VERSION "ICM"

NS_ :

BS_ :

BU_ : ICM Vector_XXX

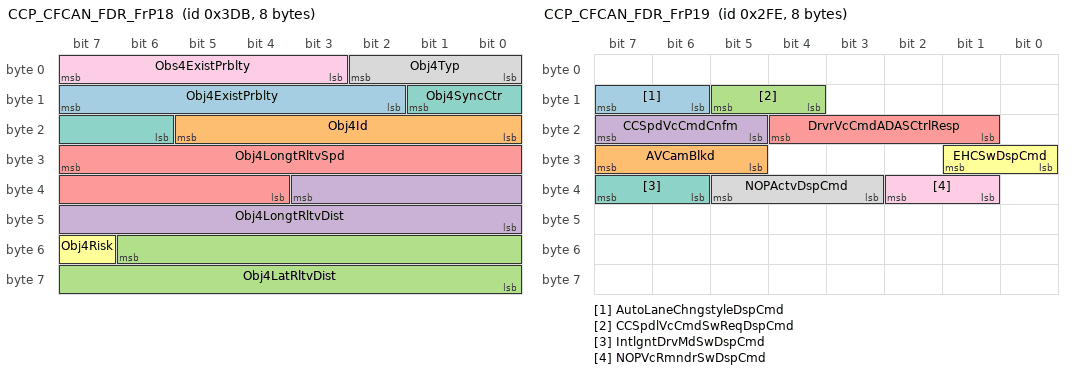
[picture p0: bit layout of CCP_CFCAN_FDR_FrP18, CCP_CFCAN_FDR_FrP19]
BO_ 987 CCP_CFCAN_FDR_FrP18 : 8 Vector_XXX
 SG_ Obj4ExistPrblty : 15|6@0+ (0.015625,0.0) [0.0|0.984375] "" ICM
 SG_ Obj4Id : 21|6@0+ (1.0,0.0) [0.0|63.0] "" ICM
 SG_ Obj4LatRltvDist : 54|15@0+ (0.0078,-128.0) [-128.0|127.58259999999999] "" ICM
 SG_ Obj4LongtRltvDist : 35|12@0+ (0.0625,-128.0) [-128.0|127.9375] "" ICM
 SG_ Obj4LongtRltvSpd : 31|12@0+ (0.0625,-128.0) [-128.0|127.9375] "" ICM
 SG_ Obj4Risk : 55|1@0+ (1,0) [0|1] "" ICM
 SG_ Obj4SyncCtr : 9|4@0+ (1.0,0.0) [0.0|15.0] "" ICM
 SG_ Obj4Typ : 2|3@0+ (1,0) [0|7] "" ICM
 SG_ Obs4ExistPrblty : 7|5@0+ (0.03125,0.0) [0.0|0.96875] "" ICM

BO_ 766 CCP_CFCAN_FDR_FrP19 : 8 Vector_XXX
 SG_ AutoLaneChngstyleDspCmd : 15|2@0+ (1,0) [0|3] "" ICM
 SG_ AVCamBlkd : 31|3@0+ (1,0) [0|7] "" ICM
 SG_ CCSpdlVcCmdSwReqDspCmd : 13|2@0+ (1,0) [0|3] "" ICM
 SG_ CCSpdVcCmdCnfm : 23|3@0+ (1,0) [0|7] "" ICM
 SG_ DrvrVcCmdADASCtrlResp : 20|4@0+ (1,0) [0|15] "" ICM
 SG_ EHCSwDspCmd : 25|2@0+ (1,0) [0|3] "" ICM
 SG_ IntlgntDrvMdSwDspCmd : 39|2@0+ (1,0) [0|3] "" ICM
 SG_ NOPActvDspCmd : 37|3@0+ (1,0) [0|7] "" ICM
 SG_ NOPVcRmndrSwDspCmd : 34|2@0+ (1,0) [0|3] "" ICM

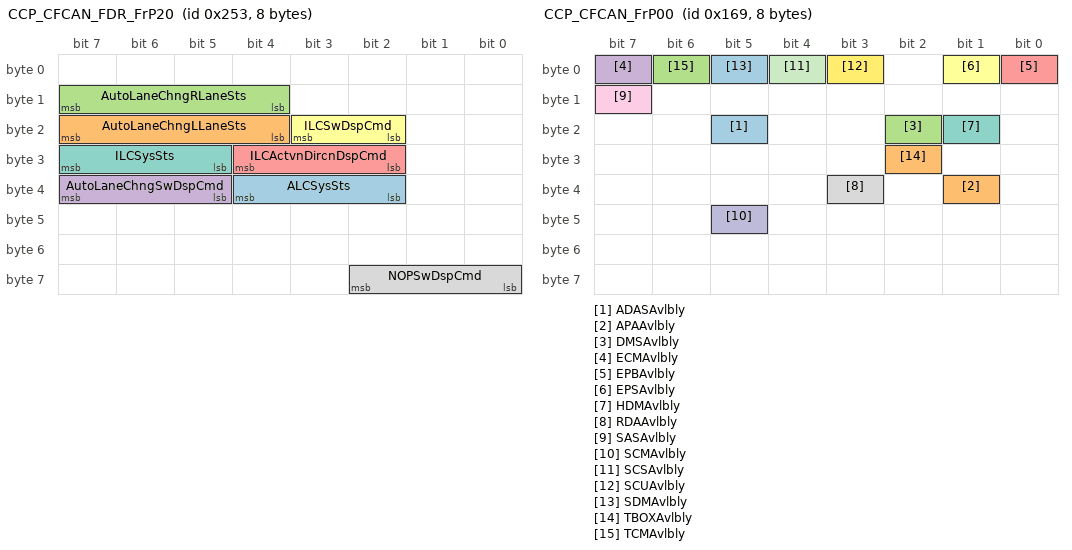
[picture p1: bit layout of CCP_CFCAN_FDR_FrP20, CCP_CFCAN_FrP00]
BO_ 595 CCP_CFCAN_FDR_FrP20 : 8 Vector_XXX
 SG_ ALCSysSts : 36|3@0+ (1,0) [0|7] "" ICM
 SG_ AutoLaneChngLLaneSts : 23|4@0+ (1,0) [0|15] "" ICM
 SG_ AutoLaneChngRLaneSts : 15|4@0+ (1,0) [0|15] "" ICM
 SG_ AutoLaneChngSwDspCmd : 39|3@0+ (1,0) [0|7] "" ICM
 SG_ ILCActvnDircnDspCmd : 28|3@0+ (1,0) [0|7] "" ICM
 SG_ ILCSwDspCmd : 19|2@0+ (1,0) [0|3] "" ICM
 SG_ ILCSysSts : 31|3@0+ (1,0) [0|7] "" ICM
 SG_ NOPSwDspCmd : 58|3@0+ (1,0) [0|7] "" ICM

BO_ 361 CCP_CFCAN_FrP00 : 8 Vector_XXX
 SG_ ADASAvlbly : 21|1@0+ (1,0) [0|1] "" ICM
 SG_ APAAvlbly : 33|1@0+ (1,0) [0|1] "" ICM
 SG_ DMSAvlbly : 18|1@0+ (1,0) [0|1] "" ICM
 SG_ ECMAvlbly : 7|1@0+ (1,0) [0|1] "" ICM
 SG_ EPBAvlbly : 0|1@0+ (1,0) [0|1] "" ICM
 SG_ EPSAvlbly : 1|1@0+ (1,0) [0|1] "" ICM
 SG_ HDMAvlbly : 17|1@0+ (1,0) [0|1] "" ICM
 SG_ RDAAvlbly : 35|1@0+ (1,0) [0|1] "" ICM
 SG_ SASAvlbly : 15|1@0+ (1,0) [0|1] "" ICM
 SG_ SCMAvlbly : 45|1@0+ (1,0) [0|1] "" ICM
 SG_ SCSAvlbly : 4|1@0+ (1,0) [0|1] "" ICM
 SG_ SCUAvlbly : 3|1@0+ (1,0) [0|1] "" ICM
 SG_ SDMAvlbly : 5|1@0+ (1,0) [0|1] "" ICM
 SG_ TBOXAvlbly : 26|1@0+ (1,0) [0|1] "" ICM
 SG_ TCMAvlbly : 6|1@0+ (1,0) [0|1] "" ICM

BO_ 821 CCP_CFCAN_FrP01 : 8 Vector_XXX
 SG_ VehEnrgRdyLvl : 26|3@0+ (1,0) [0|7] "" ICM
 SG_ VehEnrgRdyLvlV : 12|1@0+ (1,0) [0|1] "" ICM

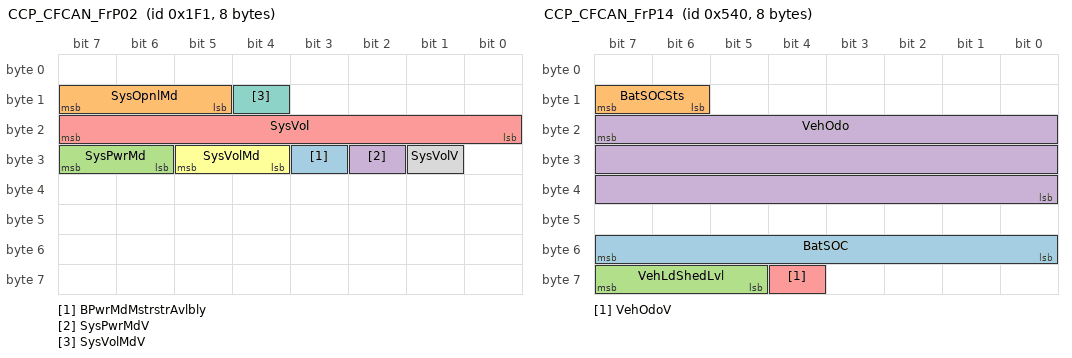
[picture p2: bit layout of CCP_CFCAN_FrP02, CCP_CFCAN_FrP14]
BO_ 497 CCP_CFCAN_FrP02 : 8 Vector_XXX
 SG_ BPwrMdMstrstrAvlbly : 27|1@0+ (1,0) [0|1] "" ICM
 SG_ SysOpnlMd : 15|3@0+ (1,0) [0|7] "" ICM
 SG_ SysPwrMd : 31|2@0+ (1,0) [0|3] "" ICM
 SG_ SysPwrMdV : 26|1@0+ (1,0) [0|1] "" ICM
 SG_ SysVol : 23|8@0+ (0.1,3.0) [3.0|28.5] "V" ICM
 SG_ SysVolMd : 29|2@0+ (1,0) [0|3] "" ICM
 SG_ SysVolMdV : 12|1@0+ (1,0) [0|1] "" ICM
 SG_ SysVolV : 25|1@0+ (1,0) [0|1] "" ICM

BO_ 803 CCP_CFCAN_FrP04 : 8 Vector_XXX
 SG_ BatAgngSta : 55|3@0+ (1,0) [0|7] "" ICM
 SG_ BatVol : 39|14@0+ (0.00097656,3.0) [3.0|17.9999616] "V" ICM

BO_ 794 CCP_CFCAN_FrP05 : 8 Vector_XXX
 SG_ VehCofignBodyCtrlrTyp : 2|3@0+ (1,0) [0|7] "" ICM
 SG_ VehCofignCCTyp : 41|2@0+ (1,0) [0|3] "" ICM
 SG_ VehCofignEnTyp : 12|5@0+ (1.0,0.0) [13.0|31.0] "Reserved" ICM
 SG_ VehCofignParkngBrkTyp : 55|2@0+ (1,0) [0|3] "" ICM
 SG_ VehCofignSlipCtrlTyp : 53|2@0+ (1,0) [0|3] "" ICM
 SG_ VehCofignSpSt : 51|1@0+ (1,0) [0|1] "" ICM
 SG_ VehCofignStrgTyp : 45|2@0+ (1,0) [0|3] "" ICM
 SG_ VehCofignTPMSTyp : 14|2@0+ (1,0) [0|3] "" ICM
 SG_ VehCofignTrnsfCaseTyp : 43|2@0+ (1,0) [0|3] "" ICM
 SG_ VehCofignTrTyp : 19|4@0+ (1.0,0.0) [9.0|15.0] "Reserved" ICM
 SG_ VehInfoBodyTyp : 31|4@0+ (1.0,0.0) [5.0|15.0] "Reserved" ICM
 SG_ VehInfoBrand : 47|2@0+ (1,0) [0|3] "" ICM
 SG_ VehInfoDrvHadlTyp : 15|1@0+ (1,0) [0|1] "" ICM
 SG_ VehInfoEmsnRegn : 23|4@0+ (1,0) [0|15] "" ICM
 SG_ VehInfoMdlYear : 63|5@0+ (1,0) [0|31] "" ICM
 SG_ VehInfoMkt : 7|5@0+ (1.0,0.0) [7.0|31.0] "Reserved" ICM
 SG_ VehInfoPf : 27|4@0+ (1.0,0.0) [8.0|15.0] "Reserved" ICM

BO_ 872 CCP_CFCAN_FrP06 : 6 Vector_XXX
 SG_ VehDrvngMd : 15|3@0+ (1,0) [0|7] "" ICM
 SG_ VehDrvngMdCofign : 21|4@0+ (1,0) [0|15] "" ICM
 SG_ VehDrvngMdRmndr : 23|2@0+ (1,0) [0|3] "" ICM

BO_ 814 CCP_CFCAN_FrP07 : 8 Vector_XXX
 SG_ GenrSta : 15|3@0+ (1,0) [0|7] "" ICM
 SG_ GwStrgCustSetngDspCmd : 26|2@0+ (1,0) [0|3] "" ICM

BO_ 886 CCP_CFCAN_FrP08 : 8 Vector_XXX
 SG_ PMDCSta : 33|2@0+ (1,0) [0|3] "" ICM

BO_ 1008 CCP_CFCAN_FrP12 : 8 Vector_XXX
 SG_ OtsdAirTemCrVal : 63|8@0+ (0.5,-40.0) [-40.0|87.5] "deg C" ICM
 SG_ OtsdAirTemCrValV : 48|1@0+ (1,0) [0|1] "" ICM

BO_ 1344 CCP_CFCAN_FrP14 : 8 Vector_XXX
 SG_ BatSOC : 55|8@0+ (0.4,0.0) [0.0|100.0] "%" ICM
 SG_ BatSOCSts : 15|2@0+ (1,0) [0|3] "" ICM
 SG_ VehLdShedLvl : 63|3@0+ (1,0) [0|7] "" ICM
 SG_ VehOdo : 23|24@0+ (1.0,0.0) [0.0|16777200.0] "" ICM
 SG_ VehOdoV : 60|1@0+ (1,0) [0|1] "" ICM

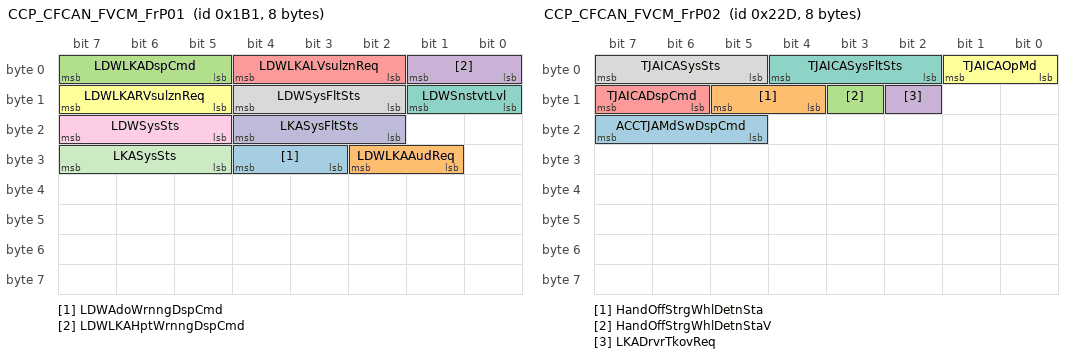
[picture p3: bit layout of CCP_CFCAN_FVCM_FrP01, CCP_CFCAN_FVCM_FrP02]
BO_ 433 CCP_CFCAN_FVCM_FrP01 : 8 Vector_XXX
 SG_ LDWAdoWrnngDspCmd : 28|2@0+ (1,0) [0|3] "" ICM
 SG_ LDWLKAAudReq : 26|2@0+ (1,0) [0|3] "" ICM
 SG_ LDWLKADspCmd : 7|3@0+ (1,0) [0|7] "" ICM
 SG_ LDWLKAHptWrnngDspCmd : 1|2@0+ (1,0) [0|3] "" ICM
 SG_ LDWLKALVsulznReq : 4|3@0+ (1,0) [0|7] "" ICM
 SG_ LDWLKARVsulznReq : 15|3@0+ (1,0) [0|7] "" ICM
 SG_ LDWSnstvtLvl : 9|2@0+ (1,0) [0|3] "" ICM
 SG_ LDWSysFltSts : 12|3@0+ (1,0) [0|7] "" ICM
 SG_ LDWSysSts : 23|3@0+ (1,0) [0|7] "" ICM
 SG_ LKASysFltSts : 20|3@0+ (1,0) [0|7] "" ICM
 SG_ LKASysSts : 31|3@0+ (1,0) [0|7] "" ICM

BO_ 557 CCP_CFCAN_FVCM_FrP02 : 8 Vector_XXX
 SG_ ACCTJAMdSwDspCmd : 23|3@0+ (1,0) [0|7] "" ICM
 SG_ HandOffStrgWhlDetnSta : 13|2@0+ (1,0) [0|3] "" ICM
 SG_ HandOffStrgWhlDetnStaV : 11|1@0+ (1,0) [0|1] "" ICM
 SG_ LKADrvrTkovReq : 10|1@0+ (1,0) [0|1] "" ICM
 SG_ TJAICADspCmd : 15|2@0+ (1,0) [0|3] "" ICM
 SG_ TJAICAOpMd : 1|2@0+ (1,0) [0|3] "" ICM
 SG_ TJAICASysFltSts : 4|3@0+ (1,0) [0|7] "" ICM
 SG_ TJAICASysSts : 7|3@0+ (1,0) [0|7] "" ICM

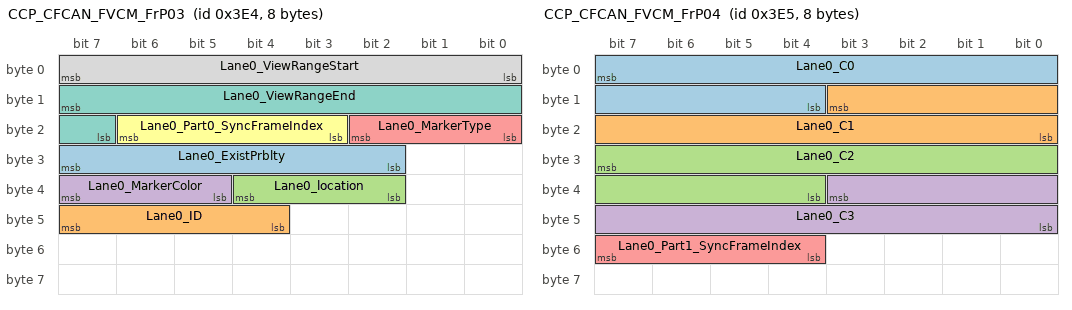
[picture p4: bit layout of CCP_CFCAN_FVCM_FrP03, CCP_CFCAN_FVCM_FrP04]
BO_ 996 CCP_CFCAN_FVCM_FrP03 : 8 Vector_XXX
 SG_ Lane0_ExistPrblty : 31|6@0+ (0.015625,0.0) [0.0|0.984375] "" ICM
 SG_ Lane0_ID : 47|4@0+ (1.0,0.0) [0.0|15.0] "" ICM
 SG_ Lane0_location : 36|3@0+ (1,0) [0|7] "" ICM
 SG_ Lane0_MarkerColor : 39|3@0+ (1,0) [0|7] "" ICM
 SG_ Lane0_MarkerType : 18|3@0+ (1,0) [0|7] "" ICM
 SG_ Lane0_Part0_SyncFrameIndex : 22|4@0+ (1.0,0.0) [0.0|15.0] "" ICM
 SG_ Lane0_ViewRangeEnd : 15|9@0+ (0.25,0.0) [0.0|127.75] "" ICM
 SG_ Lane0_ViewRangeStart : 7|8@0+ (0.25,0.0) [0.0|63.75] "" ICM

BO_ 997 CCP_CFCAN_FVCM_FrP04 : 8 Vector_XXX
 SG_ Lane0_C0 : 7|12@0+ (0.00390625,-8.0) [-8.0|7.99609375] "" ICM
 SG_ Lane0_C1 : 11|12@0+ (0.00048828125,-1.0) [-1.0|0.99951171875] "" ICM
 SG_ Lane0_C2 : 31|12@0+ (0.000015259,-0.03124285) [-0.03124285|-0.023689645] "" ICM
 SG_ Lane0_C3 : 35|12@0+ (0.0000038147,-0.0078125) [-0.0078125|0.0078086965] "" ICM
 SG_ Lane0_Part1_SyncFrameIndex : 55|4@0+ (1.0,0.0) [0.0|15.0] "" ICM

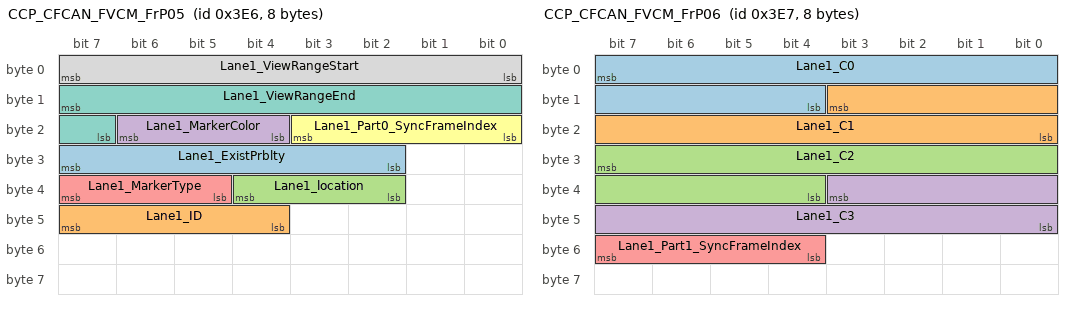
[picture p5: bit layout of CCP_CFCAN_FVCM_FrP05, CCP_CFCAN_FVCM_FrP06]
BO_ 998 CCP_CFCAN_FVCM_FrP05 : 8 Vector_XXX
 SG_ Lane1_ExistPrblty : 31|6@0+ (0.015625,0.0) [0.0|0.984375] "" ICM
 SG_ Lane1_ID : 47|4@0+ (1.0,0.0) [0.0|15.0] "" ICM
 SG_ Lane1_location : 36|3@0+ (1,0) [0|7] "" ICM
 SG_ Lane1_MarkerColor : 22|3@0+ (1,0) [0|7] "" ICM
 SG_ Lane1_MarkerType : 39|3@0+ (1,0) [0|7] "" ICM
 SG_ Lane1_Part0_SyncFrameIndex : 19|4@0+ (1.0,0.0) [0.0|15.0] "" ICM
 SG_ Lane1_ViewRangeEnd : 15|9@0+ (0.25,0.0) [0.0|127.75] "" ICM
 SG_ Lane1_ViewRangeStart : 7|8@0+ (0.25,0.0) [0.0|63.75] "" ICM

BO_ 999 CCP_CFCAN_FVCM_FrP06 : 8 Vector_XXX
 SG_ Lane1_C0 : 7|12@0+ (0.00390625,-8.0) [-8.0|7.99609375] "" ICM
 SG_ Lane1_C1 : 11|12@0+ (0.00048828125,-1.0) [-1.0|0.99951171875] "" ICM
 SG_ Lane1_C2 : 31|12@0+ (0.000015259,-0.03124285) [-0.03124285|0.031242755000000007] "" ICM
 SG_ Lane1_C3 : 35|12@0+ (0.0000038147,-0.0078125) [-0.0078125|0.0078086965] "" ICM
 SG_ Lane1_Part1_SyncFrameIndex : 55|4@0+ (1.0,0.0) [0.0|15.0] "" ICM

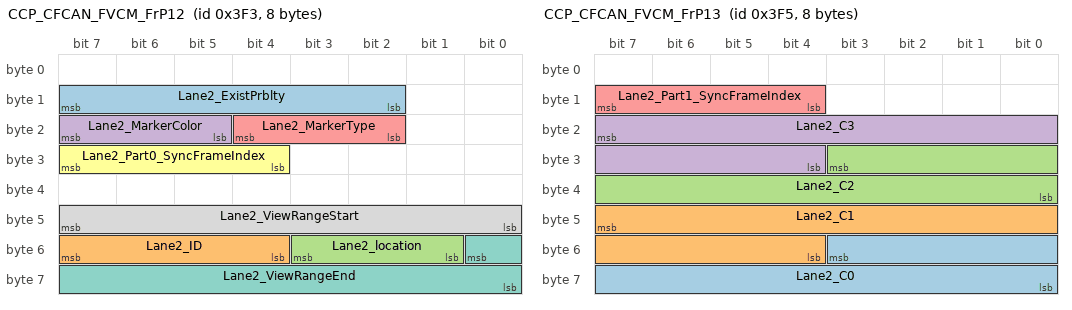
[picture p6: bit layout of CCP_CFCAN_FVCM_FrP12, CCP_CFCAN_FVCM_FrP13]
BO_ 1011 CCP_CFCAN_FVCM_FrP12 : 8 Vector_XXX
 SG_ Lane2_ExistPrblty : 15|6@0+ (0.015625,0.0) [0.0|0.984375] "" ICM
 SG_ Lane2_ID : 55|4@0+ (1.0,0.0) [0.0|15.0] "" ICM
 SG_ Lane2_location : 51|3@0+ (1,0) [0|7] "" ICM
 SG_ Lane2_MarkerColor : 23|3@0+ (1,0) [0|7] "" ICM
 SG_ Lane2_MarkerType : 20|3@0+ (1,0) [0|7] "" ICM
 SG_ Lane2_Part0_SyncFrameIndex : 31|4@0+ (1.0,0.0) [0.0|15.0] "" ICM
 SG_ Lane2_ViewRangeEnd : 48|9@0+ (0.25,0.0) [0.0|127.75] "" ICM
 SG_ Lane2_ViewRangeStart : 47|8@0+ (0.25,0.0) [0.0|63.75] "" ICM

BO_ 1013 CCP_CFCAN_FVCM_FrP13 : 8 Vector_XXX
 SG_ Lane2_C0 : 51|12@0+ (0.00390625,-8.0) [-8.0|7.99609375] "" ICM
 SG_ Lane2_C1 : 47|12@0+ (0.00048828125,-1.0) [-1.0|0.99951171875] "" ICM
 SG_ Lane2_C2 : 27|12@0+ (0.000015259,-0.03124285) [-0.03124285|0.031242755000000007] "" ICM
 SG_ Lane2_C3 : 23|12@0+ (0.0000038147,-0.0078125) [-0.0078125|0.0078086965] "" ICM
 SG_ Lane2_Part1_SyncFrameIndex : 15|4@0+ (1.0,0.0) [0.0|15.0] "" ICM

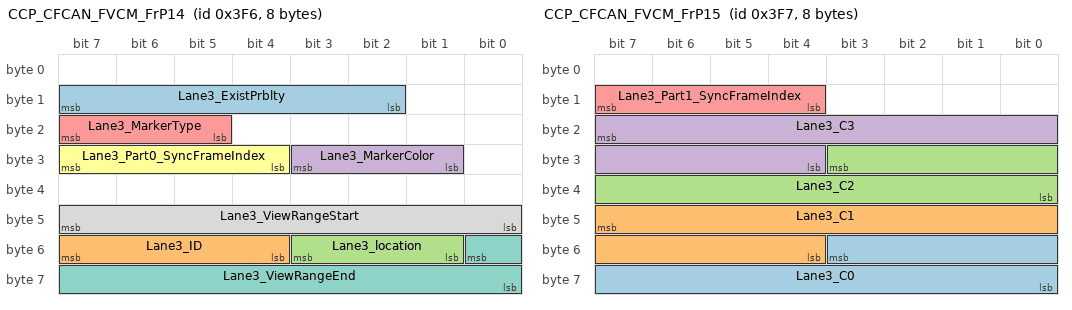
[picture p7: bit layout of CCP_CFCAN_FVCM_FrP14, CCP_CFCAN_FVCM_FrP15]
BO_ 1014 CCP_CFCAN_FVCM_FrP14 : 8 Vector_XXX
 SG_ Lane3_ExistPrblty : 15|6@0+ (0.015625,0.0) [0.0|0.984375] "" ICM
 SG_ Lane3_ID : 55|4@0+ (1.0,0.0) [0.0|15.0] "" ICM
 SG_ Lane3_location : 51|3@0+ (1,0) [0|7] "" ICM
 SG_ Lane3_MarkerColor : 27|3@0+ (1,0) [0|7] "" ICM
 SG_ Lane3_MarkerType : 23|3@0+ (1,0) [0|7] "" ICM
 SG_ Lane3_Part0_SyncFrameIndex : 31|4@0+ (1.0,0.0) [0.0|15.0] "" ICM
 SG_ Lane3_ViewRangeEnd : 48|9@0+ (0.25,0.0) [0.0|127.75] "" ICM
 SG_ Lane3_ViewRangeStart : 47|8@0+ (0.25,0.0) [0.0|63.75] "" ICM

BO_ 1015 CCP_CFCAN_FVCM_FrP15 : 8 Vector_XXX
 SG_ Lane3_C0 : 51|12@0+ (0.00390625,-8.0) [-8.0|7.99609375] "" ICM
 SG_ Lane3_C1 : 47|12@0+ (0.00048828125,-1.0) [-1.0|0.99951171875] "" ICM
 SG_ Lane3_C2 : 27|12@0+ (0.000015259,-0.03124285) [-0.03124285|0.031242755000000007] "" ICM
 SG_ Lane3_C3 : 23|12@0+ (0.0000038147,-0.0078125) [-0.0078125|0.0078086965] "" ICM
 SG_ Lane3_Part1_SyncFrameIndex : 15|4@0+ (1.0,0.0) [0.0|15.0] "" ICM

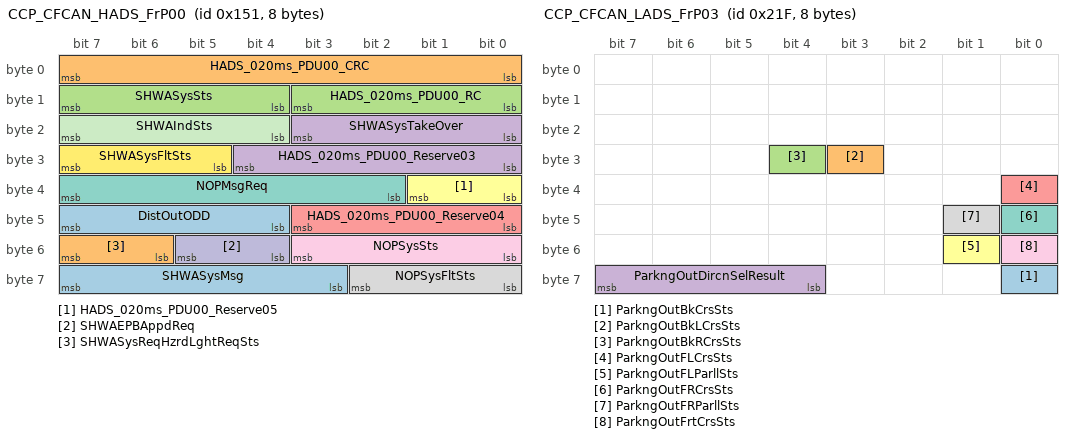
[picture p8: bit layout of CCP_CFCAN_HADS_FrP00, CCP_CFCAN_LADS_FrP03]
BO_ 337 CCP_CFCAN_HADS_FrP00 : 8 Vector_XXX
 SG_ DistOutODD : 47|4@0+ (1,0) [0|15] "" ICM
 SG_ HADS_020ms_PDU00_CRC : 7|8@0+ (1.0,0.0) [0.0|255.0] "" ICM
 SG_ HADS_020ms_PDU00_RC : 11|4@0+ (1.0,0.0) [0.0|15.0] "" ICM
 SG_ HADS_020ms_PDU00_Reserve03 : 28|5@0+ (1,0) [0|31] "" ICM
 SG_ HADS_020ms_PDU00_Reserve04 : 43|4@0+ (1,0) [0|15] "" ICM
 SG_ HADS_020ms_PDU00_Reserve05 : 33|2@0+ (1,0) [0|3] "" ICM
 SG_ NOPMsgReq : 39|6@0+ (1,0) [0|63] "" ICM
 SG_ NOPSysFltSts : 58|3@0+ (1,0) [0|7] "" ICM
 SG_ NOPSysSts : 51|4@0+ (1,0) [0|15] "" ICM
 SG_ SHWAEPBAppdReq : 53|2@0+ (1,0) [0|3] "" ICM
 SG_ SHWAIndSts : 23|4@0+ (1,0) [0|15] "" ICM
 SG_ SHWASysFltSts : 31|3@0+ (1,0) [0|7] "" ICM
 SG_ SHWASysMsg : 63|5@0+ (1,0) [0|31] "" ICM
 SG_ SHWASysReqHzrdLghtReqSts : 55|2@0+ (1,0) [0|3] "" ICM
 SG_ SHWASysSts : 15|4@0+ (1,0) [0|15] "" ICM
 SG_ SHWASysTakeOver : 19|4@0+ (1,0) [0|15] "" ICM

BO_ 581 CCP_CFCAN_HDM_FrP00 : 8 Vector_XXX
 SG_ HDMLicVPrd : 31|16@0+ (1.0,0.0) [0.0|65534.0] "days" ICM
 SG_ HDMSysFltSts : 15|2@0+ (1,0) [0|3] "" ICM
 SG_ HDMSysIMUCalSts : 20|3@0+ (1,0) [0|7] "" ICM
 SG_ HDMSysLicActvnSts : 47|3@0+ (1,0) [0|7] "" ICM

BO_ 591 CCP_CFCAN_LADS_FrP02 : 8 Vector_XXX
 SG_ APASts : 27|3@0+ (1,0) [0|7] "" ICM

BO_ 543 CCP_CFCAN_LADS_FrP03 : 8 Vector_XXX
 SG_ ParkngOutBkCrsSts : 56|1@0+ (1,0) [0|1] "" ICM
 SG_ ParkngOutBkLCrsSts : 27|1@0+ (1,0) [0|1] "" ICM
 SG_ ParkngOutBkRCrsSts : 28|1@0+ (1,0) [0|1] "" ICM
 SG_ ParkngOutDircnSelResult : 63|4@0+ (1,0) [0|15] "" ICM
 SG_ ParkngOutFLCrsSts : 32|1@0+ (1,0) [0|1] "" ICM
 SG_ ParkngOutFLParllSts : 49|1@0+ (1,0) [0|1] "" ICM
 SG_ ParkngOutFRCrsSts : 40|1@0+ (1,0) [0|1] "" ICM
 SG_ ParkngOutFRParllSts : 41|1@0+ (1,0) [0|1] "" ICM
 SG_ ParkngOutFrtCrsSts : 48|1@0+ (1,0) [0|1] "" ICM

BO_ 765 CCP_CFCAN_LADS_FrP10 : 8 Vector_XXX
 SG_ AVMCalMdReqResp_LADS : 39|3@0+ (1,0) [0|7] "" ICM
 SG_ AVMSysSts_LADS : 13|2@0+ (1,0) [0|3] "" ICM

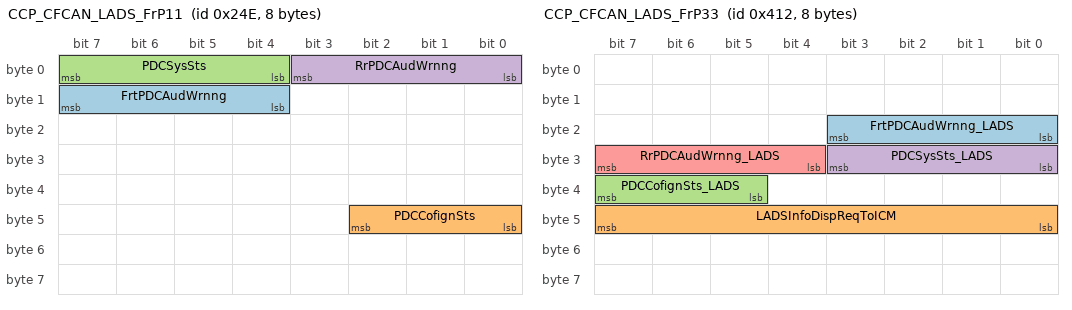
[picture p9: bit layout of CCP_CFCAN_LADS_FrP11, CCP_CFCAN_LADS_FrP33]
BO_ 590 CCP_CFCAN_LADS_FrP11 : 8 Vector_XXX
 SG_ FrtPDCAudWrnng : 15|4@0+ (1,0) [0|15] "" ICM
 SG_ PDCCofignSts : 42|3@0+ (1,0) [0|7] "" ICM
 SG_ PDCSysSts : 7|4@0+ (1,0) [0|15] "" ICM
 SG_ RrPDCAudWrnng : 3|4@0+ (1,0) [0|15] "" ICM

BO_ 1038 CCP_CFCAN_LADS_FrP30 : 8 Vector_XXX
 SG_ MUWSwSts : 26|2@0+ (1,0) [0|3] "" ICM

BO_ 605 CCP_CFCAN_LADS_FrP32 : 8 Vector_XXX
 SG_ HD_AVMCurView : 39|6@0+ (1,0) [0|63] "" ICM
 SG_ HD_AVMsysrdy : 33|1@0+ (1,0) [0|1] "" ICM

BO_ 1042 CCP_CFCAN_LADS_FrP33 : 8 Vector_XXX
 SG_ FrtPDCAudWrnng_LADS : 19|4@0+ (1,0) [0|15] "" ICM
 SG_ LADSInfoDispReqToICM : 47|8@0+ (1,0) [0|255] "" ICM
 SG_ PDCCofignSts_LADS : 39|3@0+ (1,0) [0|7] "" ICM
 SG_ PDCSysSts_LADS : 27|4@0+ (1,0) [0|15] "" ICM
 SG_ RrPDCAudWrnng_LADS : 31|4@0+ (1,0) [0|15] "" ICM

BO_ 1216 CCP_CFCAN_NM : 8 Vector_XXX
 SG_ NmPDU_CFCAN_CCP : 7|64@0+ (1,0) [0|0] "" ICM

BO_ 778 CCP_CFCAN_SCM_FrP01 : 8 Vector_XXX
 SG_ SCMCustSetngDspCmd : 15|2@0+ (1,0) [0|3] "" ICM
 SG_ SusFlrSts : 23|2@0+ (1,0) [0|3] "" ICM
 SG_ SusMdSts : 13|2@0+ (1,0) [0|3] "" ICM

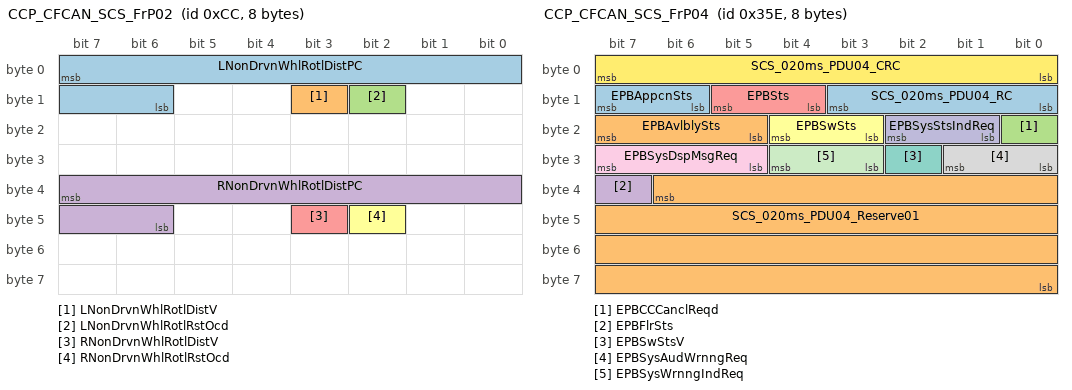
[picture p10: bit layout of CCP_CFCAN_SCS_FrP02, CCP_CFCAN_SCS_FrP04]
BO_ 204 CCP_CFCAN_SCS_FrP02 : 8 Vector_XXX
 SG_ LNonDrvnWhlRotlDistPC : 7|10@0+ (1.0,0.0) [0.0|1023.0] "" ICM
 SG_ LNonDrvnWhlRotlDistV : 11|1@0+ (1,0) [0|1] "" ICM
 SG_ LNonDrvnWhlRotlRstOcd : 10|1@0+ (1,0) [0|1] "" ICM
 SG_ RNonDrvnWhlRotlDistPC : 39|10@0+ (1.0,0.0) [0.0|1023.0] "" ICM
 SG_ RNonDrvnWhlRotlDistV : 43|1@0+ (1,0) [0|1] "" ICM
 SG_ RNonDrvnWhlRotlRstOcd : 42|1@0+ (1,0) [0|1] "" ICM

BO_ 862 CCP_CFCAN_SCS_FrP04 : 8 Vector_XXX
 SG_ EPBAppcnSts : 15|2@0+ (1,0) [0|3] "" ICM
 SG_ EPBAvlblySts : 23|3@0+ (1,0) [0|7] "" ICM
 SG_ EPBCCCanclReqd : 16|1@0+ (1,0) [0|1] "" ICM
 SG_ EPBFlrSts : 39|1@0+ (1,0) [0|1] "" ICM
 SG_ EPBSts : 13|2@0+ (1,0) [0|3] "" ICM
 SG_ EPBSwSts : 20|2@0+ (1,0) [0|3] "" ICM
 SG_ EPBSwStsV : 26|1@0+ (1,0) [0|1] "" ICM
 SG_ EPBSysAudWrnngReq : 25|2@0+ (1,0) [0|3] "" ICM
 SG_ EPBSysDspMsgReq : 31|3@0+ (1,0) [0|7] "" ICM
 SG_ EPBSysStsIndReq : 18|2@0+ (1,0) [0|3] "" ICM
 SG_ EPBSysWrnngIndReq : 28|2@0+ (1,0) [0|3] "" ICM
 SG_ SCS_020ms_PDU04_CRC : 7|8@0+ (1.0,0.0) [0.0|255.0] "" ICM
 SG_ SCS_020ms_PDU04_RC : 11|4@0+ (1.0,0.0) [0.0|15.0] "" ICM
 SG_ SCS_020ms_PDU04_Reserve01 : 38|31@0+ (1,0) [0|2147483647] "" ICM

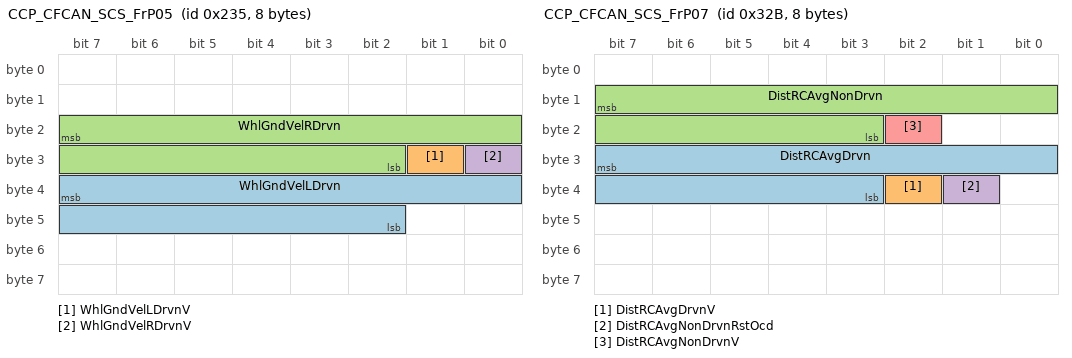
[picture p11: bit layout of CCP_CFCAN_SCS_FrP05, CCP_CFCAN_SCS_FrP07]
BO_ 565 CCP_CFCAN_SCS_FrP05 : 8 Vector_XXX
 SG_ WhlGndVelLDrvn : 39|14@0+ (0.03125,0.0) [0.0|511.96875] "km/h" ICM
 SG_ WhlGndVelLDrvnV : 25|1@0+ (1,0) [0|1] "" ICM
 SG_ WhlGndVelRDrvn : 23|14@0+ (0.03125,0.0) [0.0|511.96875] "km/h" ICM
 SG_ WhlGndVelRDrvnV : 24|1@0+ (1,0) [0|1] "" ICM

BO_ 811 CCP_CFCAN_SCS_FrP07 : 8 Vector_XXX
 SG_ DistRCAvgDrvn : 31|13@0+ (0.125,0.0) [0.0|1023.875] "m" ICM
 SG_ DistRCAvgDrvnV : 34|1@0+ (1,0) [0|1] "" ICM
 SG_ DistRCAvgNonDrvn : 15|13@0+ (0.125,0.0) [0.0|1023.875] "m" ICM
 SG_ DistRCAvgNonDrvnRstOcd : 33|1@0+ (1,0) [0|1] "" ICM
 SG_ DistRCAvgNonDrvnV : 18|1@0+ (1,0) [0|1] "" ICM

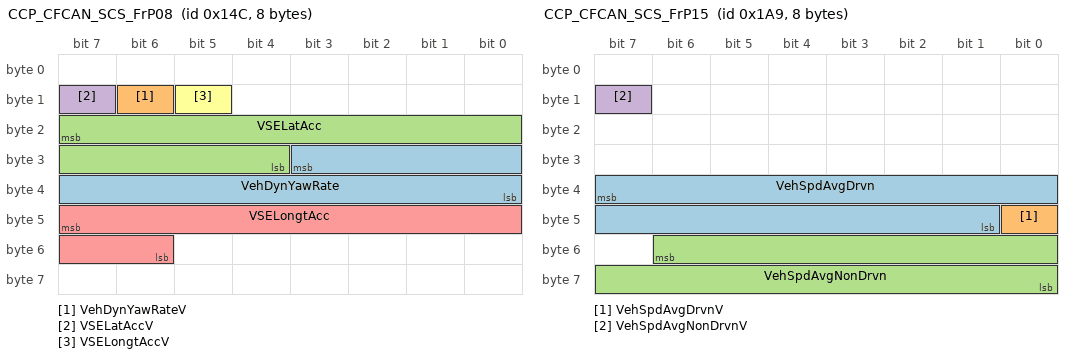
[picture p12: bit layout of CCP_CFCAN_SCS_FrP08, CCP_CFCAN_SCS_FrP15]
BO_ 332 CCP_CFCAN_SCS_FrP08 : 8 Vector_XXX
 SG_ VehDynYawRate : 27|12@0- (0.0625,0.0) [-128.0|127.9375] "deg/sec" ICM
 SG_ VehDynYawRateV : 14|1@0+ (1,0) [0|1] "" ICM
 SG_ VSELatAcc : 23|12@0- (0.015625,0.0) [-32.0|31.984375] "m/s^2" ICM
 SG_ VSELatAccV : 15|1@0+ (1,0) [0|1] "" ICM
 SG_ VSELongtAcc : 47|10@0- (0.03,0.0) [-15.36|15.33] "m/s^2" ICM
 SG_ VSELongtAccV : 13|1@0+ (1,0) [0|1] "" ICM

BO_ 425 CCP_CFCAN_SCS_FrP15 : 8 Vector_XXX
 SG_ VehSpdAvgDrvn : 39|15@0+ (0.015625,0.0) [0.0|511.984375] "km/h" ICM
 SG_ VehSpdAvgDrvnV : 40|1@0+ (1,0) [0|1] "" ICM
 SG_ VehSpdAvgNonDrvn : 54|15@0+ (0.015625,0.0) [0.0|511.984375] "km/h" ICM
 SG_ VehSpdAvgNonDrvnV : 15|1@0+ (1,0) [0|1] "" ICM

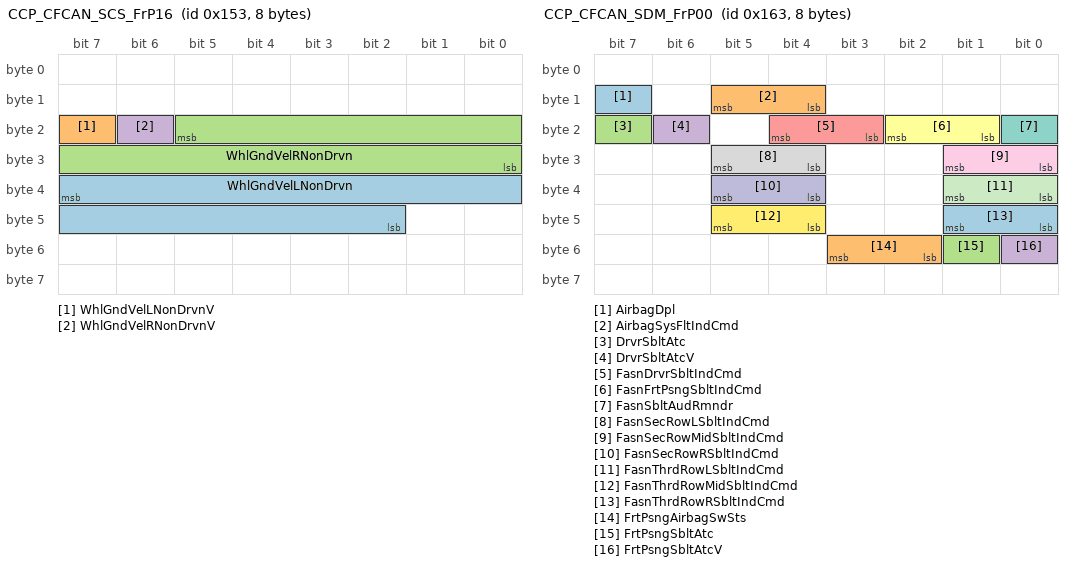
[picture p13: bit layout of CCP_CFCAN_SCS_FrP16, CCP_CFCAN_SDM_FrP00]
BO_ 339 CCP_CFCAN_SCS_FrP16 : 8 Vector_XXX
 SG_ WhlGndVelLNonDrvn : 39|14@0+ (0.03125,0.0) [0.0|511.96875] "km/h" ICM
 SG_ WhlGndVelLNonDrvnV : 23|1@0+ (1,0) [0|1] "" ICM
 SG_ WhlGndVelRNonDrvn : 21|14@0+ (0.03125,0.0) [0.0|511.96875] "km/h" ICM
 SG_ WhlGndVelRNonDrvnV : 22|1@0+ (1,0) [0|1] "" ICM

BO_ 355 CCP_CFCAN_SDM_FrP00 : 8 Vector_XXX
 SG_ AirbagDpl : 15|1@0+ (1,0) [0|1] "" ICM
 SG_ AirbagSysFltIndCmd : 13|2@0+ (1,0) [0|3] "" ICM
 SG_ DrvrSbltAtc : 23|1@0+ (1,0) [0|1] "" ICM
 SG_ DrvrSbltAtcV : 22|1@0+ (1,0) [0|1] "" ICM
 SG_ FasnDrvrSbltIndCmd : 20|2@0+ (1,0) [0|3] "" ICM
 SG_ FasnFrtPsngSbltIndCmd : 18|2@0+ (1,0) [0|3] "" ICM
 SG_ FasnSbltAudRmndr : 16|1@0+ (1,0) [0|1] "" ICM
 SG_ FasnSecRowLSbltIndCmd : 29|2@0+ (1,0) [0|3] "" ICM
 SG_ FasnSecRowMidSbltIndCmd : 25|2@0+ (1,0) [0|3] "" ICM
 SG_ FasnSecRowRSbltIndCmd : 37|2@0+ (1,0) [0|3] "" ICM
 SG_ FasnThrdRowLSbltIndCmd : 33|2@0+ (1,0) [0|3] "" ICM
 SG_ FasnThrdRowMidSbltIndCmd : 45|2@0+ (1,0) [0|3] "" ICM
 SG_ FasnThrdRowRSbltIndCmd : 41|2@0+ (1,0) [0|3] "" ICM
 SG_ FrtPsngAirbagSwSts : 51|2@0+ (1,0) [0|3] "" ICM
 SG_ FrtPsngSbltAtc : 49|1@0+ (1,0) [0|1] "" ICM
 SG_ FrtPsngSbltAtcV : 48|1@0+ (1,0) [0|1] "" ICM

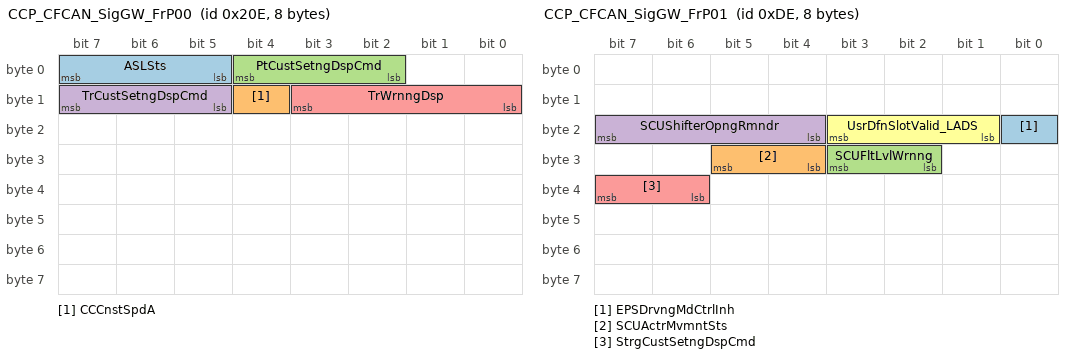
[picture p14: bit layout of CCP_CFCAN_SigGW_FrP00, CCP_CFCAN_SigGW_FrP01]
BO_ 526 CCP_CFCAN_SigGW_FrP00 : 8 Vector_XXX
 SG_ ASLSts : 7|3@0+ (1,0) [0|7] "" ICM
 SG_ CCCnstSpdA : 12|1@0+ (1,0) [0|1] "" ICM
 SG_ PtCustSetngDspCmd : 4|3@0+ (1,0) [0|7] "" ICM
 SG_ TrCustSetngDspCmd : 15|3@0+ (1.0,0.0) [0.0|7.0] "" ICM
 SG_ TrWrnngDsp : 11|4@0+ (1,0) [0|15] "" ICM

BO_ 222 CCP_CFCAN_SigGW_FrP01 : 8 Vector_XXX
 SG_ EPSDrvngMdCtrlInh : 16|1@0+ (1,0) [0|1] "" ICM
 SG_ SCUActrMvmntSts : 29|2@0+ (1,0) [0|3] "" ICM
 SG_ SCUFltLvlWrnng : 27|2@0+ (1,0) [0|3] "" ICM
 SG_ SCUShifterOpngRmndr : 23|4@0+ (1,0) [0|15] "" ICM
 SG_ StrgCustSetngDspCmd : 39|2@0+ (1,0) [0|3] "" ICM
 SG_ UsrDfnSlotValid_LADS : 19|3@0+ (1,0) [0|7] "" ICM

BO_ 362 CCP_CFCAN_SigGW_FrP02 : 8 Vector_XXX
 SG_ ABSIO : 47|1@0+ (1,0) [0|1] "" ICM
 SG_ ACCSysFltSts : 2|3@0+ (1,0) [0|7] "" ICM
 SG_ ACCSysSts : 15|3@0+ (1,0) [0|7] "" ICM
 SG_ AEBSysFltSts : 12|3@0+ (1,0) [0|7] "" ICM
 SG_ AEBSysSts : 23|3@0+ (1,0) [0|7] "" ICM
 SG_ AutoHoldMsg : 7|3@0+ (1,0) [0|7] "" ICM
 SG_ AutoHoldSysSts : 60|2@0+ (1,0) [0|3] "" ICM
 SG_ AutoMainBeamLghtReq : 9|2@0+ (1,0) [0|3] "" ICM
 SG_ BrkSysRedBrkTlltReq : 4|1@0+ (1,0) [0|1] "" ICM
 SG_ EnASSSta : 25|2@0+ (1,0) [0|3] "" ICM
 SG_ FCTASysFltSts : 28|3@0+ (1,0) [0|7] "" ICM
 SG_ FVCMBlkd : 29|1@0+ (1,0) [0|1] "" ICM
 SG_ FVCMCalPrgsReq : 20|3@0+ (1,0) [0|7] "" ICM
 SG_ FVCMFltSts : 17|2@0+ (1,0) [0|3] "" ICM
 SG_ HDCSysSts : 63|3@0+ (1,0) [0|7] "" ICM
 SG_ SCSMdSts : 31|2@0+ (1,0) [0|3] "" ICM
 SG_ TCSOpngMd : 45|3@0+ (1,0) [0|7] "" ICM
 SG_ TCSOpngSts : 42|3@0+ (1,0) [0|7] "" ICM
 SG_ VSEMd : 53|3@0+ (1,0) [0|7] "" ICM
 SG_ VSESts : 50|3@0+ (1,0) [0|7] "" ICM

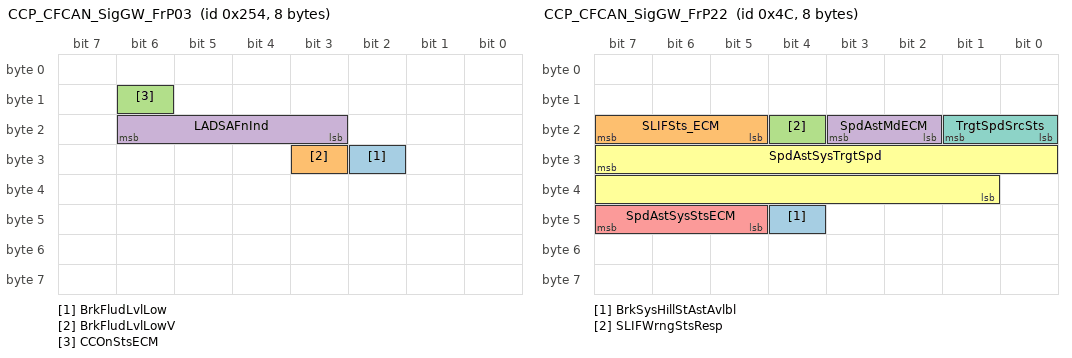
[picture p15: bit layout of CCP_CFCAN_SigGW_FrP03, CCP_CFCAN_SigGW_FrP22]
BO_ 596 CCP_CFCAN_SigGW_FrP03 : 8 Vector_XXX
 SG_ BrkFludLvlLow : 26|1@0+ (1,0) [0|1] "" ICM
 SG_ BrkFludLvlLowV : 27|1@0+ (1,0) [0|1] "" ICM
 SG_ CCOnStsECM : 14|1@0+ (1,0) [0|1] "" ICM
 SG_ LADSAFnInd : 22|4@0+ (1,0) [0|15] "" ICM

BO_ 1353 CCP_CFCAN_SigGW_FrP06 : 8 Vector_XXX
 SG_ EnOilPrsLowIO : 3|1@0+ (1,0) [0|1] "" ICM

BO_ 934 CCP_CFCAN_SigGW_FrP21 : 8 Vector_XXX
 SG_ StrgCDMSSetngDspCmd : 7|7@0+ (1,0) [0|127] "" ICM

BO_ 76 CCP_CFCAN_SigGW_FrP22 : 8 Vector_XXX
 SG_ BrkSysHillStAstAvlbl : 44|1@0+ (1,0) [0|1] "" ICM
 SG_ SLIFSts_ECM : 23|3@0+ (1,0) [0|7] "" ICM
 SG_ SLIFWrngStsResp : 20|1@0+ (1,0) [0|1] "" ICM
 SG_ SpdAstMdECM : 19|2@0+ (1,0) [0|3] "" ICM
 SG_ SpdAstSysStsECM : 47|3@0+ (1,0) [0|7] "" ICM
 SG_ SpdAstSysTrgtSpd : 31|15@0+ (0.015625,0.0) [0.0|511.984375] "" ICM
 SG_ TrgtSpdSrcSts : 17|2@0+ (1,0) [0|3] "" ICM

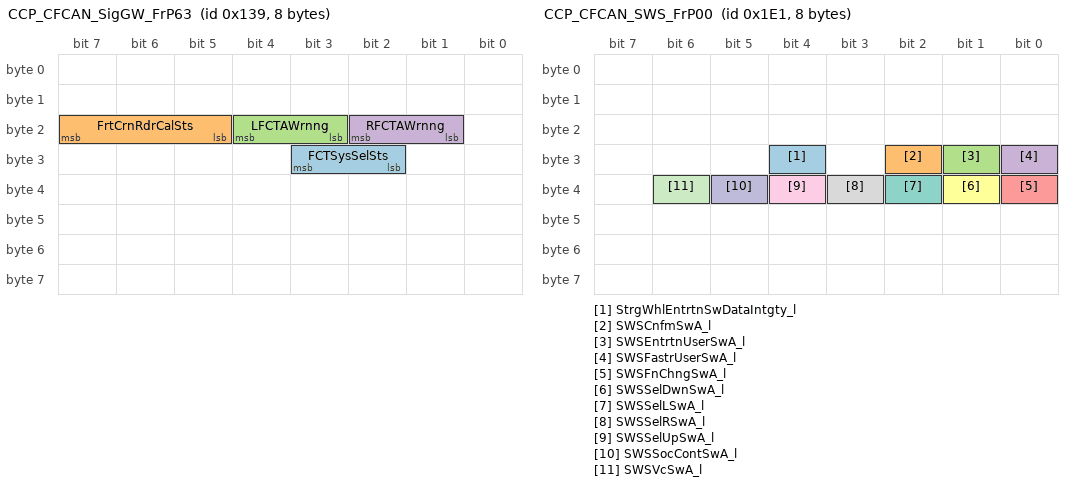
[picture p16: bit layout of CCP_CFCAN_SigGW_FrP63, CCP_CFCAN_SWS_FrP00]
BO_ 313 CCP_CFCAN_SigGW_FrP63 : 8 Vector_XXX
 SG_ FCTSysSelSts : 27|2@0+ (1,0) [0|3] "" ICM
 SG_ FrtCrnRdrCalSts : 23|3@0+ (1,0) [0|7] "" ICM
 SG_ LFCTAWrnng : 20|2@0+ (1,0) [0|3] "" ICM
 SG_ RFCTAWrnng : 18|2@0+ (1,0) [0|3] "" ICM

BO_ 553 CCP_CFCAN_SigGW_FrP67 : 8 Vector_XXX
 SG_ BSDSelSts : 29|2@0+ (1,0) [0|3] "" ICM
 SG_ DOWSelSts : 39|2@0+ (1,0) [0|3] "" ICM
 SG_ LBSDAndLCAWrnng : 37|2@0+ (1,0) [0|3] "" ICM
 SG_ LCASelSts : 27|2@0+ (1,0) [0|3] "" ICM
 SG_ LDOWWrnng : 35|2@0+ (1,0) [0|3] "" ICM
 SG_ LRCTAWrnng : 33|2@0+ (1,0) [0|3] "" ICM
 SG_ RBSDAndLCAWrnng : 47|2@0+ (1,0) [0|3] "" ICM
 SG_ RCTBPrflReq : 63|1@0+ (1,0) [0|1] "" ICM
 SG_ RCTBReq : 31|2@0+ (1,0) [0|3] "" ICM
 SG_ RCTBSysFltSts : 10|3@0+ (1,0) [0|7] "" ICM
 SG_ RCTBSysSta : 15|5@0+ (1,0) [0|31] "" ICM
 SG_ RCTBTrgtDcl : 7|8@0+ (0.1,-12.7) [-12.7|12.8] "m/s^2" ICM
 SG_ RCTSysSelSts : 45|2@0+ (1,0) [0|3] "" ICM
 SG_ RCWSelSts : 43|2@0+ (1,0) [0|3] "" ICM
 SG_ RCWWrnng : 41|2@0+ (1,0) [0|3] "" ICM
 SG_ RDASwSts : 25|2@0+ (1,0) [0|3] "" ICM
 SG_ RDASysSta : 23|5@0+ (1,0) [0|31] "" ICM
 SG_ RDOWWrnng : 55|2@0+ (1,0) [0|3] "" ICM
 SG_ RrCrnRdrCalSts : 18|3@0+ (1,0) [0|7] "" ICM
 SG_ RRCTAWrnng : 49|2@0+ (1,0) [0|3] "" ICM

BO_ 560 CCP_CFCAN_SigGW_FrP90 : 8 Vector_XXX
 SG_ ELSDCustSetngDspCmd : 31|2@0+ (1,0) [0|3] "" ICM
 SG_ EnToqActuExtdRng : 51|12@0+ (0.5,-848.0) [-848.0|1199.5] "Nm" ICM

BO_ 481 CCP_CFCAN_SWS_FrP00 : 8 Vector_XXX
 SG_ StrgWhlEntrtnSwDataIntgty_l : 28|1@0+ (1,0) [0|1] "" ICM
 SG_ SWSCnfmSwA_l : 26|1@0+ (1,0) [0|1] "" ICM
 SG_ SWSEntrtnUserSwA_l : 25|1@0+ (1,0) [0|1] "" ICM
 SG_ SWSFastrUserSwA_l : 24|1@0+ (1,0) [0|1] "" ICM
 SG_ SWSFnChngSwA_l : 32|1@0+ (1,0) [0|1] "" ICM
 SG_ SWSSelDwnSwA_l : 33|1@0+ (1,0) [0|1] "" ICM
 SG_ SWSSelLSwA_l : 34|1@0+ (1,0) [0|1] "" ICM
 SG_ SWSSelRSwA_l : 35|1@0+ (1,0) [0|1] "" ICM
 SG_ SWSSelUpSwA_l : 36|1@0+ (1,0) [0|1] "" ICM
 SG_ SWSSocContSwA_l : 37|1@0+ (1,0) [0|1] "" ICM
 SG_ SWSVcSwA_l : 38|1@0+ (1,0) [0|1] "" ICM

BO_ 819 CCP_CFCAN_TBOX_FrP01 : 8 Vector_XXX
 SG_ FOTASts : 15|1@0+ (1,0) [0|1] "" ICM
 SG_ FOTAStsV : 23|1@0+ (1,0) [0|1] "" ICM

BO_ 852 CCP_CFCAN_TBOX_FrP02 : 8 Vector_XXX
 SG_ EmgcCallFlrSts : 6|2@0+ (1,0) [0|3] "" ICM
 SG_ EmgcCallTrigd : 4|1@0+ (1,0) [0|1] "" ICM

BO_ 501 CCP_CFCAN_TCM_FrP02 : 8 Vector_XXX
 SG_ AutocTrCmddGear_TCM : 15|4@0+ (1,0) [0|15] "" ICM
 SG_ DrvrShftCtrlReqDndIO : 21|1@0+ (1,0) [0|1] "" ICM
 SG_ DrvrShftCtrlTrgtGear_TCM : 19|4@0+ (1,0) [0|15] "" ICM
 SG_ TCM_025ms_PDU02_CRC : 7|8@0+ (1.0,0.0) [0.0|255.0] "" ICM
 SG_ TCM_025ms_PDU02_RC : 11|4@0+ (1.0,0.0) [0.0|15.0] "" ICM
 SG_ TCM_025ms_PDU02_Reserve03 : 47|1@0+ (1,0) [0|1] "" ICM
 SG_ TCM_025ms_PDU02_Reserve04 : 23|2@0+ (1,0) [0|3] "" ICM
 SG_ TCM_025ms_PDU02_Reserve05 : 63|8@0+ (1,0) [0|255] "" ICM
 SG_ TrCrpMdA_TCM : 46|1@0+ (1,0) [0|1] "" ICM
 SG_ TrEngdSta_TCM : 49|2@0+ (1,0) [0|3] "" ICM
 SG_ TrEngdStaV_TCM : 50|1@0+ (1,0) [0|1] "" ICM
 SG_ TrEPBAppReq : 20|1@0+ (1,0) [0|1] "" ICM
 SG_ TrEstdGear_TCM : 39|4@0+ (1,0) [0|15] "" ICM
 SG_ TrEstdGearV_TCM : 45|1@0+ (1,0) [0|1] "" ICM
 SG_ TrIntnlSwPos : 54|4@0+ (1,0) [0|15] "" ICM
 SG_ TrIntnlSwPosV : 55|1@0+ (1,0) [0|1] "" ICM
 SG_ TrPrkPos : 31|2@0+ (1,0) [0|3] "" ICM
 SG_ TrPrkSysF : 29|1@0+ (1,0) [0|1] "" ICM
 SG_ TrShftLvrPos_TCM : 27|4@0+ (1,0) [0|15] "" ICM
 SG_ TrShftLvrPosV_TCM : 28|1@0+ (1,0) [0|1] "" ICM
 SG_ TrShftPtrnASts_TCM : 44|3@0+ (1,0) [0|7] "" ICM
 SG_ TrTapUpTapDwnMdSts_TCM : 41|2@0+ (1,0) [0|3] "" ICM
 SG_ TrTrgtShftLvrPos : 35|4@0+ (1,0) [0|15] "" ICM

BO_ 1358 CCP_CFCAN_TCM_FrP09 : 8 Vector_XXX
 SG_ TrClThrmlProtnNotfn : 35|4@0+ (1,0) [0|15] "" ICM
 SG_ TrEstdClCldnTemTrgtDsp : 55|8@0+ (0.392157,0.0) [0.0|100.000035] "%" ICM
 SG_ TrEstdClTemDsp : 47|8@0+ (0.392157,0.0) [0.0|100.000035] "%" ICM
 SG_ TrNonEmsnRltdMalfA : 4|1@0+ (1,0) [0|1] "" ICM

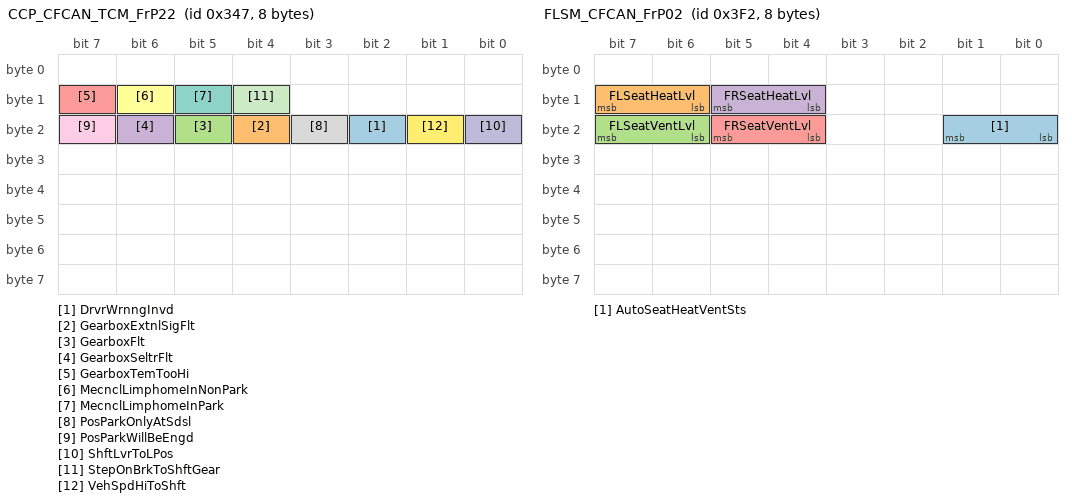
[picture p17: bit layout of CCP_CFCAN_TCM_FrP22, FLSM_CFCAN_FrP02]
BO_ 839 CCP_CFCAN_TCM_FrP22 : 8 Vector_XXX
 SG_ DrvrWrnngInvd : 18|1@0+ (1,0) [0|1] "" ICM
 SG_ GearboxExtnlSigFlt : 20|1@0+ (1,0) [0|1] "" ICM
 SG_ GearboxFlt : 21|1@0+ (1,0) [0|1] "" ICM
 SG_ GearboxSeltrFlt : 22|1@0+ (1,0) [0|1] "" ICM
 SG_ GearboxTemTooHi : 15|1@0+ (1,0) [0|1] "" ICM
 SG_ MecnclLimphomeInNonPark : 14|1@0+ (1,0) [0|1] "" ICM
 SG_ MecnclLimphomeInPark : 13|1@0+ (1,0) [0|1] "" ICM
 SG_ PosParkOnlyAtSdsl : 19|1@0+ (1,0) [0|1] "" ICM
 SG_ PosParkWillBeEngd : 23|1@0+ (1,0) [0|1] "" ICM
 SG_ ShftLvrToLPos : 16|1@0+ (1,0) [0|1] "" ICM
 SG_ StepOnBrkToShftGear : 12|1@0+ (1,0) [0|1] "" ICM
 SG_ VehSpdHiToShft : 17|1@0+ (1,0) [0|1] "" ICM

BO_ 770 CMM_CFCAN_FrP01 : 8 Vector_XXX
 SG_ FuelDoorOpenIO : 23|1@0+ (1,0) [0|1] "" ICM
 SG_ RmndPwrOffIO : 12|1@0+ (1,0) [0|1] "" ICM
 SG_ SrvcFuelSysIO : 13|1@0+ (1,0) [0|1] "" ICM
 SG_ VehRfulSta : 15|2@0+ (1,0) [0|3] "" ICM

BO_ 2015 Diag_CFCAN_FunReq : 8 Vector_XXX
 SG_ Diag_CFCAN_FunReq : 7|64@0+ (1,0) [0|0] "" ICM

BO_ 1889 Diag_CFCAN_PhyReq_FICM : 8 Vector_XXX
 SG_ Diag_CFCAN_PhyReq_ICM : 7|64@0+ (1,0) [0|0] "" ICM

BO_ 1546 DIAG_PhysReq_VKR : 8 Vector_XXX
 SG_ DiagnosticReqVKR : 7|64@0+ (1,0) [0|18446744073709551615] "" ICM

BO_ 1010 FLSM_CFCAN_FrP02 : 8 Vector_XXX
 SG_ AutoSeatHeatVentSts : 17|2@0+ (1,0) [0|3] "" ICM
 SG_ FLSeatHeatLvl : 15|2@0+ (1,0) [0|3] "" ICM
 SG_ FLSeatVentLvl : 23|2@0+ (1,0) [0|3] "" ICM
 SG_ FRSeatHeatLvl : 13|2@0+ (1,0) [0|3] "" ICM
 SG_ FRSeatVentLvl : 21|2@0+ (1,0) [0|3] "" ICM

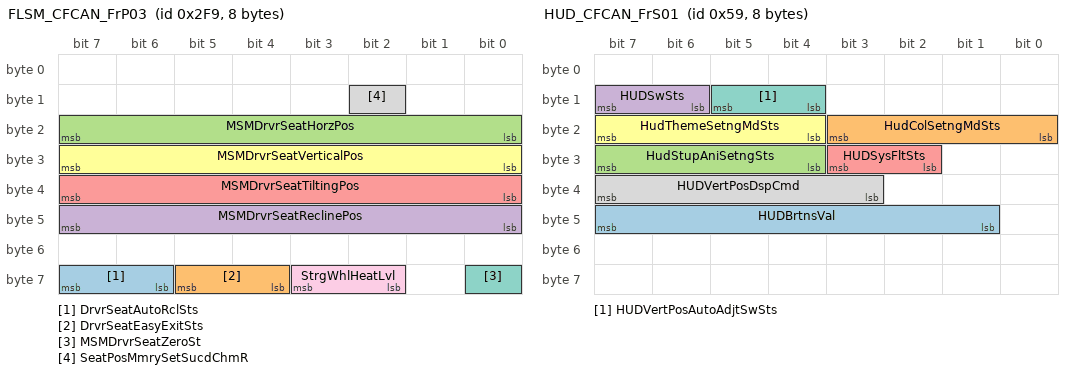
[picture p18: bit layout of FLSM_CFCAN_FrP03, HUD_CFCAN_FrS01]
BO_ 761 FLSM_CFCAN_FrP03 : 8 Vector_XXX
 SG_ DrvrSeatAutoRclSts : 63|2@0+ (1,0) [0|3] "" ICM
 SG_ DrvrSeatEasyExitSts : 61|2@0+ (1,0) [0|3] "" ICM
 SG_ MSMDrvrSeatHorzPos : 23|8@0+ (1.0,0.0) [0.0|100.0] "%" ICM
 SG_ MSMDrvrSeatReclinePos : 47|8@0+ (1.0,0.0) [0.0|100.0] "%" ICM
 SG_ MSMDrvrSeatTiltingPos : 39|8@0+ (1.0,0.0) [0.0|100.0] "%" ICM
 SG_ MSMDrvrSeatVerticalPos : 31|8@0+ (1.0,0.0) [0.0|100.0] "%" ICM
 SG_ MSMDrvrSeatZeroSt : 56|1@0+ (1,0) [0|1] "" ICM
 SG_ SeatPosMmrySetSucdChmR : 10|1@0+ (1,0) [0|1] "" ICM
 SG_ StrgWhlHeatLvl : 59|2@0+ (1,0) [0|3] "" ICM

BO_ 89 HUD_CFCAN_FrS01 : 8 Vector_XXX
 SG_ HUDBrtnsVal : 47|7@0+ (1,0) [0|127] "" ICM
 SG_ HudColSetngMdSts : 19|4@0+ (1,0) [0|15] "" ICM
 SG_ HudStupAniSetngSts : 31|4@0+ (1,0) [0|15] "" ICM
 SG_ HUDSwSts : 15|2@0+ (1,0) [0|3] "" ICM
 SG_ HUDSysFltSts : 27|2@0+ (1,0) [0|3] "" ICM
 SG_ HudThemeSetngMdSts : 23|4@0+ (1,0) [0|15] "" ICM
 SG_ HUDVertPosAutoAdjtSwSts : 13|2@0+ (1,0) [0|3] "" ICM
 SG_ HUDVertPosDspCmd : 39|5@0+ (1,0) [0|31] "" ICM

BO_ 90 HUD_CFCAN_FrS02 : 8 Vector_XXX
 SG_ HUDNavReq : 15|1@0+ (1,0) [0|1] "" ICM

BO_ 576 PEPS_CFCAN_FrP01 : 8 Vector_XXX
 SG_ PEPSAntFlt : 51|1@0+ (1,0) [0|1] "" ICM
 SG_ PEPSSSBFltSts : 54|3@0+ (1,0) [0|7] "" ICM

BO_ 518 PLCM_CFCAN_FrP00 : 8 Vector_XXX
 SG_ PwrLftgtPos : 23|7@0+ (0.787402,0.0) [0.0|100.000054] "%" ICM
 SG_ PwrLftgtPosV : 13|1@0+ (1,0) [0|1] "" ICM

BO_ 763 PLCM_CFCAN_FrP01 : 8 Vector_XXX
 SG_ PwrLftgtManuClsReq : 16|1@0+ (1,0) [0|1] "" ICM
 SG_ PwrLftgtPosSetngDspCmd : 23|7@0+ (0.787402,0.0) [0.0|100.000054] "%" ICM
 SG_ PwrLftgtPutInParkReq : 12|1@0+ (1,0) [0|1] "" ICM
 SG_ PwrLftgtSts : 15|3@0+ (1,0) [0|7] "" ICM

BO_ 1704 Tester_CFCAN_EOLRX : 8 Vector_XXX
 SG_ FICMEOLRx : 7|64@0+ (1,0) [0|18446744073709551615] "" ICM

BO_ 1703 Tester_CFCAN_EOLTX : 8 Vector_XXX
 SG_ FICMEOLTx : 7|64@0+ (1,0) [0|18446744073709551615] "" ICM

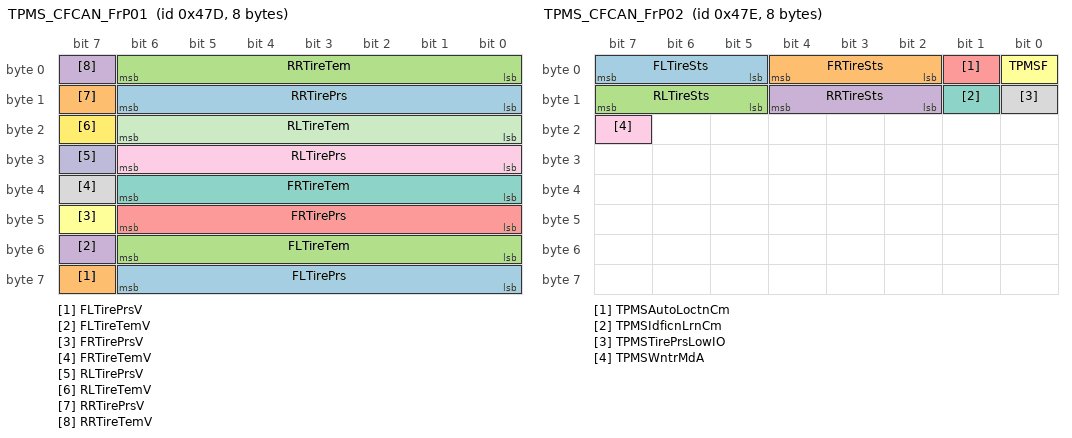
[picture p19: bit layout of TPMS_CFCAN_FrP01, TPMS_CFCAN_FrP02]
BO_ 1149 TPMS_CFCAN_FrP01 : 8 Vector_XXX
 SG_ FLTirePrs : 62|7@0+ (4.0,0.0) [0.0|508.0] "KPa" ICM
 SG_ FLTirePrsV : 63|1@0+ (1,0) [0|1] "" ICM
 SG_ FLTireTem : 54|7@0+ (2.0,-60.0) [-60.0|194.0] "Celsius degree" ICM
 SG_ FLTireTemV : 55|1@0+ (1,0) [0|1] "" ICM
 SG_ FRTirePrs : 46|7@0+ (4.0,0.0) [0.0|508.0] "KPa" ICM
 SG_ FRTirePrsV : 47|1@0+ (1,0) [0|1] "" ICM
 SG_ FRTireTem : 38|7@0+ (2.0,-60.0) [-60.0|194.0] "Celsius degree" ICM
 SG_ FRTireTemV : 39|1@0+ (1,0) [0|1] "" ICM
 SG_ RLTirePrs : 30|7@0+ (4.0,0.0) [0.0|508.0] "KPa" ICM
 SG_ RLTirePrsV : 31|1@0+ (1,0) [0|1] "" ICM
 SG_ RLTireTem : 22|7@0+ (2.0,-60.0) [-60.0|194.0] "Celsius degree" ICM
 SG_ RLTireTemV : 23|1@0+ (1,0) [0|1] "" ICM
 SG_ RRTirePrs : 14|7@0+ (4.0,0.0) [0.0|508.0] "KPa" ICM
 SG_ RRTirePrsV : 15|1@0+ (1,0) [0|1] "" ICM
 SG_ RRTireTem : 6|7@0+ (2.0,-60.0) [-60.0|194.0] "Celsius degree" ICM
 SG_ RRTireTemV : 7|1@0+ (1,0) [0|1] "" ICM

BO_ 1150 TPMS_CFCAN_FrP02 : 8 Vector_XXX
 SG_ FLTireSts : 7|3@0+ (1,0) [0|7] "" ICM
 SG_ FRTireSts : 4|3@0+ (1,0) [0|7] "" ICM
 SG_ RLTireSts : 15|3@0+ (1,0) [0|7] "" ICM
 SG_ RRTireSts : 12|3@0+ (1,0) [0|7] "" ICM
 SG_ TPMSAutoLoctnCm : 1|1@0+ (1,0) [0|1] "" ICM
 SG_ TPMSF : 0|1@0+ (1,0) [0|1] "" ICM
 SG_ TPMSIdficnLrnCm : 9|1@0+ (1,0) [0|1] "" ICM
 SG_ TPMSTirePrsLowIO : 8|1@0+ (1,0) [0|1] "" ICM
 SG_ TPMSWntrMdA : 23|1@0+ (1,0) [0|1] "" ICM

CM_ SG_ 987 Obj4ExistPrblty "Object 4 Exist Probability";
CM_ SG_ 987 Obj4Id "Object 4 Identifier";
CM_ SG_ 987 Obj4LatRltvDist "Object 4 Lateral Relative Distance";
CM_ SG_ 987 Obj4LongtRltvDist "Object 4 Longitudinal Relative Distance";
CM_ SG_ 987 Obj4LongtRltvSpd "Object 4 Longitudinal Relative Speed";
CM_ SG_ 987 Obj4Risk "Object 4 Risk";
CM_ SG_ 987 Obj4SyncCtr "Object 4 Synchronize Counter";
CM_ SG_ 987 Obj4Typ "Object 4 Type";
CM_ SG_ 987 Obs4ExistPrblty "Obstacle 4 Exist Probability";
CM_ SG_ 766 CCSpdlVcCmdSwReqDspCmd "Cruise Control Speed Voice Command Switch Request Display Command";
CM_ SG_ 766 CCSpdVcCmdCnfm "Cruise Control Speed Voice Command Confirm";
CM_ SG_ 595 ALCSysSts "Auto Lane Change System Status";
CM_ SG_ 595 AutoLaneChngLLaneSts "Auto Lane Change Left Lane Status";
CM_ SG_ 595 AutoLaneChngRLaneSts "Auto Lane Change Right Lane Status";
CM_ SG_ 595 AutoLaneChngSwDspCmd "Auto Lane Change Switch Display Command";
CM_ SG_ 361 ADASAvlbly "FDR Available

Detect if specific ECU is available according to node missing strategy by gateway ECU.

";
CM_ SG_ 361 DMSAvlbly "DMSAvlbly";
CM_ SG_ 361 ECMAvlbly "ECM Available

Detect if specific ECU is available according to node missing strategy by gateway ECU.

";
CM_ SG_ 361 EPBAvlbly "EPB Available

Detect if specific ECU is available according to node missing strategy by gateway ECU.

";
CM_ SG_ 361 EPSAvlbly "EPS Available

Detect if specific ECU is available according to node missing strategy by gateway ECU.

";
CM_ SG_ 361 HDMAvlbly "FDR Available

Detect if specific ECU is available according to node missing strategy by gateway ECU.

";
CM_ SG_ 361 RDAAvlbly "ECM Available

Detect if specific ECU is available according to node missing strategy by gateway ECU.

";
CM_ SG_ 361 SASAvlbly "SAS Available

Detect if specific ECU is available according to node missing strategy by gateway ECU.

";
CM_ SG_ 361 SCSAvlbly "BCM Available

Detect if specific ECU is available according to node missing strategy by gateway ECU.
";
CM_ SG_ 361 SCUAvlbly "SCU Available

Detect if specific ECU is available according to node missing strategy by gateway ECU.

";
CM_ SG_ 361 SDMAvlbly "SDM Available

Detect if specific ECU is available according to node missing strategy by gateway ECU.

";
CM_ SG_ 361 TBOXAvlbly "TBOX Available

Detect if specific ECU is available according to node missing strategy by gateway ECU.

";
CM_ SG_ 361 TCMAvlbly "TCM Available

Detect if specific ECU is available according to node missing strategy by gateway ECU.

";
CM_ SG_ 497 BPwrMdMstrstrAvlbly "Backup Power Mode Master Availability";
CM_ SG_ 497 SysOpnlMd "System Operational Mode";
CM_ SG_ 497 SysPwrMd "System Power Mode";
CM_ SG_ 497 SysPwrMdV "System Power Mode Validity ";
CM_ SG_ 497 SysVol "Battery Voltage";
CM_ SG_ 497 SysVolMd "System Voltage Mode ";
CM_ SG_ 497 SysVolMdV "System Voltage Mode Validity ";
CM_ SG_ 497 SysVolV "Battery Voltage Validity";
CM_ SG_ 803 BatAgngSta "Battery Aging State
";
CM_ SG_ 803 BatVol "Battery voltage sampled by PMDC";
CM_ SG_ 794 VehCofignBodyCtrlrTyp "Vehicl eConfiguration Body Controller Type
";
CM_ SG_ 794 VehCofignCCTyp "Vehicle Configuration Cruise Control Type
";
CM_ SG_ 794 VehCofignEnTyp "Vehicle Configuration Engine Type";
CM_ SG_ 794 VehCofignParkngBrkTyp "Vehicle Configuration Parking Brake Type
";
CM_ SG_ 794 VehCofignSlipCtrlTyp "Vehicle Configuration Slip Control Type
";
CM_ SG_ 794 VehCofignSpSt "Vehicle Configuration Stop Start
";
CM_ SG_ 794 VehCofignStrgTyp "Vehicle Configuration Steering Type
";
CM_ SG_ 794 VehCofignTPMSTyp "Vehicle Configuration Tire Pressure Monitor System Type
";
CM_ SG_ 794 VehCofignTrnsfCaseTyp "Vehicle Configuration Transfer Case Type
";
CM_ SG_ 794 VehCofignTrTyp "Vehicle Configuration Transmission Type";
CM_ SG_ 794 VehInfoBodyTyp "Vehicle Information Body Type";
CM_ SG_ 794 VehInfoBrand "Vehicle Information Brand";
CM_ SG_ 794 VehInfoDrvHadlTyp "Vehicle Information Drive Handle Type";
CM_ SG_ 794 VehInfoEmsnRegn "Vehicle Information Emissions Regulation
";
CM_ SG_ 794 VehInfoMdlYear "Vehicle Information Model Year";
CM_ SG_ 794 VehInfoMkt "Vehicle Information Market";
CM_ SG_ 794 VehInfoPf "Vehicle Information Platform";
CM_ SG_ 814 GenrSta "state of generator";
CM_ SG_ 886 PMDCSta "Power Management Direct Current Converter State";
CM_ SG_ 1008 OtsdAirTemCrVal "Outside Air Temperature Corrected Value";
CM_ SG_ 1008 OtsdAirTemCrValV "Outside Air Temperature Corrected Value Validity";
CM_ SG_ 1344 BatSOC "Battery State Of Charge";
CM_ SG_ 1344 BatSOCSts "Battery State Of Charge Status";
CM_ SG_ 1344 VehLdShedLvl "Vehicle Load Shed Level
power risk for load sheding";
CM_ SG_ 1344 VehOdo "Vehicle Odometer";
CM_ SG_ 1344 VehOdoV "Vehicle Odometer Validity";
CM_ SG_ 433 LDWAdoWrnngDspCmd "Lane Departure Warning Audio Warning Display Command
";
CM_ SG_ 433 LDWLKADspCmd "Lane Departure Warning Lane Keeping Assist Display Command
";
CM_ SG_ 433 LDWLKAHptWrnngDspCmd "Lane Departure Warning Lane Keeping Assist Haptic Warning Display Command";
CM_ SG_ 433 LDWLKALVsulznReq "Lane Departure Warning Lane Keeping Assist Left Visualization Request
";
CM_ SG_ 433 LDWLKARVsulznReq "Lane Departure Warning Lane Keeping Assist Right Visualization Request
";
CM_ SG_ 433 LDWSnstvtLvl "Lane Departure Warning Sensitivity Level
";
CM_ SG_ 433 LDWSysSts "Lane Departure Warning System Status
";
CM_ SG_ 557 ACCTJAMdSwDspCmd "Adaptive Cruise Control Traffic Jam Assist Mode Switch Display Command

";
CM_ SG_ 557 TJAICADspCmd "Traffic Jam Assist Integrated Cruise Assist Display Command";
CM_ SG_ 557 TJAICASysFltSts "Traffic Jam Assist Integrated Cruise Assist Fault Status
";
CM_ SG_ 557 TJAICASysSts "Traffic Jam Assist Integrated Cruise Assist System Status
";
CM_ SG_ 996 Lane0_ExistPrblty "Lane  Exist Probability
";
CM_ SG_ 1011 Lane2_ExistPrblty "Lane 2 Exist Probability";
CM_ SG_ 1011 Lane2_ID "Lane 2 Identifier";
CM_ SG_ 1011 Lane2_location "Lane 2 Position";
CM_ SG_ 1011 Lane2_MarkerColor "Lane 2 Line Color";
CM_ SG_ 1011 Lane2_MarkerType "Lane 2 Marker Type";
CM_ SG_ 1011 Lane2_Part0_SyncFrameIndex "Lane 2 Synchronize Counter";
CM_ SG_ 1011 Lane2_ViewRangeEnd "Lane 2 Curve Longitudinal Distance Stop";
CM_ SG_ 1011 Lane2_ViewRangeStart "Lane 2 Curve Longitudinal Distance Start";
CM_ SG_ 1013 Lane2_C0 "Lane 2 Curve Parameter C0";
CM_ SG_ 1013 Lane2_C1 "Lane 2 Curve Parameter C1";
CM_ SG_ 1013 Lane2_Part1_SyncFrameIndex "Lane 2 Second Synchronize Counter";
CM_ SG_ 1014 Lane3_ExistPrblty "Lane 3 Exist Probability";
CM_ SG_ 1014 Lane3_ID "Lane 3 Identifier";
CM_ SG_ 1014 Lane3_location "Lane 3 Position";
CM_ SG_ 1014 Lane3_MarkerColor "Lane 3 Line Color";
CM_ SG_ 1014 Lane3_MarkerType "Lane 3 Marker Type";
CM_ SG_ 1014 Lane3_Part0_SyncFrameIndex "Lane 3 Synchronize Counter";
CM_ SG_ 1014 Lane3_ViewRangeEnd "Lane 3 Curve Longitudinal Distance Stop";
CM_ SG_ 1014 Lane3_ViewRangeStart "Lane 3 Curve Longitudinal Distance Start";
CM_ SG_ 1015 Lane3_C0 "Lane 3 Curve Parameter C0";
CM_ SG_ 1015 Lane3_C1 "Lane 3 Curve Parameter C1";
CM_ SG_ 1015 Lane3_Part1_SyncFrameIndex "Lane 3 Second Synchronize Counter";
CM_ SG_ 337 SHWAEPBAppdReq "Super HighWay Assist Electric Park Brake Applied Request";
CM_ SG_ 337 SHWAIndSts "Super HighWay Assist Indication Status";
CM_ SG_ 337 SHWASysFltSts "Super Highway Assist Fault Status";
CM_ SG_ 337 SHWASysMsg "Super Highway Assist System Message";
CM_ SG_ 337 SHWASysSts "Super Highway Assist System Status";
CM_ SG_ 337 SHWASysTakeOver "Super Highway Assist System Take Over";
CM_ SG_ 581 HDMLicVPrd "High Definition Map System License Validity Period";
CM_ SG_ 581 HDMSysFltSts "High Definition Map System Fault Status";
CM_ SG_ 581 HDMSysIMUCalSts "High Definition Map System Inertial Measurement Unit Calibration Status";
CM_ SG_ 581 HDMSysLicActvnSts "High Definition Map System License Activation Status";
CM_ SG_ 543 ParkngOutBkCrsSts "Parking Out Back Cross Status";
CM_ SG_ 543 ParkngOutBkLCrsSts "Parking Out Back Left Cross Status";
CM_ SG_ 543 ParkngOutBkRCrsSts "Parking Out Back Right Cross Status";
CM_ SG_ 543 ParkngOutFLCrsSts "Parking Out Front Left Cross Status";
CM_ SG_ 543 ParkngOutFLParllSts "Parking Out Front Left Parallel Status";
CM_ SG_ 543 ParkngOutFRCrsSts "Parking Out Front Right Cross Status";
CM_ SG_ 543 ParkngOutFRParllSts "Parking Out Front Right Parallel Status";
CM_ SG_ 543 ParkngOutFrtCrsSts "Parking Out Front Cross Status";
CM_ SG_ 765 AVMCalMdReqResp_LADS "Around View Monitor Calibration Mode Request Response";
CM_ SG_ 590 FrtPDCAudWrnng "Front Park Distance Control Audible Warning";
CM_ SG_ 590 PDCCofignSts "Park Distance Control Configuration Status";
CM_ SG_ 590 PDCSysSts "Park Distance Control System Status";
CM_ SG_ 590 RrPDCAudWrnng "Rear Park Distance Control Audible Warning";
CM_ SG_ 605 HD_AVMCurView "Hd_around View Monitor Current View";
CM_ SG_ 605 HD_AVMsysrdy "Hd_avm System Ready";
CM_ SG_ 1042 FrtPDCAudWrnng_LADS "Front Park Distance Control Audible Warning";
CM_ SG_ 1042 LADSInfoDispReqToICM "Lads Information Display Request To Icm";
CM_ SG_ 1042 PDCSysSts_LADS "Park Distance Control System Status";
CM_ SG_ 1042 RrPDCAudWrnng_LADS "Rear Park Distance Control Audible Warning";
CM_ SG_ 204 LNonDrvnWhlRotlDistPC "Left Non Driven Wheel Rotational Distance Pulse Counter";
CM_ SG_ 204 LNonDrvnWhlRotlDistV "Left Non Driven Wheel Rotational Distance Validity";
CM_ SG_ 204 LNonDrvnWhlRotlRstOcd "Left Non Driven Wheel Rotational Reset Occurred";
CM_ SG_ 204 RNonDrvnWhlRotlDistPC "Right Non Driven Wheel Rotational Distance Pulse Counter";
CM_ SG_ 204 RNonDrvnWhlRotlDistV "Right Non Driven Wheel Rotational Distance Validity";
CM_ SG_ 204 RNonDrvnWhlRotlRstOcd "Right Non Driven Wheel Rotational Reset Occurred";
CM_ SG_ 862 EPBAppcnSts "Electric Park Brake Application Status";
CM_ SG_ 862 EPBAvlblySts "Electric Park Brake Availability Status";
CM_ SG_ 862 EPBCCCanclReqd "Electric Park Brake Cruise Control Cancel Request";
CM_ SG_ 862 EPBFlrSts "Electric Park Brake Failure Status";
CM_ SG_ 862 EPBSts "Electric Park Brake Status";
CM_ SG_ 862 EPBSwSts "Electric Park Brake Switch Status";
CM_ SG_ 862 EPBSwStsV "Electric Park Brake Switch Status Validity";
CM_ SG_ 862 EPBSysAudWrnngReq "Electric Park Brake System Audible Warning Request";
CM_ SG_ 862 EPBSysDspMsgReq "Electric Park Brake System Display Message Request";
CM_ SG_ 862 EPBSysStsIndReq "Electric Park Brake System Status Indication Request";
CM_ SG_ 862 EPBSysWrnngIndReq "Electric Park Brake System Warning Indication Request";
CM_ SG_ 862 SCS_020ms_PDU04_CRC "Wheel Ground Velocity Non Driven Checksum
Regarding high integrity requirement, a checksum signal is used for the bit field in same frame. The signal XOR operation is recommended for the calculation.";
CM_ SG_ 565 WhlGndVelLDrvn "Wheel Ground Velocity Left Driven";
CM_ SG_ 565 WhlGndVelLDrvnV "Wheel Ground Velocity Left Driven Validity";
CM_ SG_ 565 WhlGndVelRDrvn "Wheel Ground Velocity Right Driven";
CM_ SG_ 565 WhlGndVelRDrvnV "Wheel Ground Velocity Right Driven Validity";
CM_ SG_ 811 DistRCAvgDrvn "Distance Rolling Count Average Driven";
CM_ SG_ 811 DistRCAvgDrvnV "Distance Rolling Count Average Driven Validity";
CM_ SG_ 811 DistRCAvgNonDrvn "Distance Rolling Count Average Non Driven";
CM_ SG_ 811 DistRCAvgNonDrvnRstOcd "Distance Rolling Count Average Non Driven Reset Occurred";
CM_ SG_ 811 DistRCAvgNonDrvnV "Distance Rolling Count Average Non Driven Validity";
CM_ SG_ 332 VehDynYawRate "Vehicle Dynamics Yaw Rate:Counterclockwise is Positive;Clockwise is Negative.

Note:
1.The true signal type of  VehDynYawRate is signed. But the VTP only support unsigned.
2.VehDynYawRate is logical value in hex in VTP level and should be converted into physical value in application.
3. Encoding: E = N * 0.0625 deg/sec";
CM_ SG_ 332 VehDynYawRateV "Vehicle Dynamics Yaw Rate Validity";
CM_ SG_ 332 VSELatAcc "Vehicle Stability Enhancement Lateral Acceleration ";
CM_ SG_ 332 VSELatAccV "20200810
A Rx:
VSELongtAcc
VSELongtAccV
";
CM_ SG_ 332 VSELongtAcc "Vehicle Stability Enhancement Longitudinal Acceleration
Note:
1.The true signal type of  VehStabEnhmntLongtAcc is signed. but the VTP only support unsigned.
2.VehStabEnhmntLongtAcc is logical value in hex in VTP level and should be converted into physical value in application.
3. Encoding: E = N * 0.03 ";
CM_ SG_ 332 VSELongtAccV "Vehicle Stability Enhancement Longitudinal Acceleration Validity";
CM_ SG_ 425 VehSpdAvgDrvn "Vehicle Speed Average Driven";
CM_ SG_ 425 VehSpdAvgDrvnV "Vehicle Speed Average Driven Validity";
CM_ SG_ 425 VehSpdAvgNonDrvn "Vehicle Speed Average Non Driven";
CM_ SG_ 425 VehSpdAvgNonDrvnV "Vehicle Speed Average Non Driven Validity";
CM_ SG_ 339 WhlGndVelLNonDrvn "Wheel Ground Velocity Left Non Driven";
CM_ SG_ 339 WhlGndVelLNonDrvnV "Wheel Ground Velocity Left Non Driven Validity";
CM_ SG_ 339 WhlGndVelRNonDrvn "Wheel Ground Velocity Right Non Driven";
CM_ SG_ 339 WhlGndVelRNonDrvnV "Wheel Ground Velocity Right  Non Driven Validity";
CM_ SG_ 355 AirbagDpl "Airbag Deployed";
CM_ SG_ 355 AirbagSysFltIndCmd "Airbag System Fault Indication Command";
CM_ SG_ 355 DrvrSbltAtc "Driver Seatbelt Attached
indicate the driver has fasten seatbelt";
CM_ SG_ 355 DrvrSbltAtcV "Driver Seatbelt Attached Validity";
CM_ SG_ 355 FasnDrvrSbltIndCmd "Fasten Driver Seatbelt Indication Command";
CM_ SG_ 355 FasnFrtPsngSbltIndCmd "Fasten Front Passenger Seatbelt Indication Command";
CM_ SG_ 355 FasnSbltAudRmndr "Fasten Seatbelt Audible Reminder
";
CM_ SG_ 355 FasnSecRowLSbltIndCmd "Fasten Second Row Left Seatbelt Indication Command
";
CM_ SG_ 355 FasnSecRowMidSbltIndCmd "Fasten Second Row Middle Seatbelt Indication Command
";
CM_ SG_ 355 FasnSecRowRSbltIndCmd "Fasten Second Row Right Seatbelt Indication Command
";
CM_ SG_ 355 FasnThrdRowLSbltIndCmd "Fasten Third Row Left Seatbelt Indication Command";
CM_ SG_ 355 FasnThrdRowMidSbltIndCmd "Fasten Third Row Middle Seatbelt Indication Command";
CM_ SG_ 355 FasnThrdRowRSbltIndCmd "Fasten Third Row Right Seatbelt Indication Command";
CM_ SG_ 355 FrtPsngSbltAtc "Front Passenger Seatbelt Attached
";
CM_ SG_ 355 FrtPsngSbltAtcV "Front Passenger Seatbelt Attached Validity";
CM_ SG_ 526 CCCnstSpdA "Cruise Control Constant Speed Active";
CM_ SG_ 222 StrgCustSetngDspCmd "Steering Customization Setting Display Command
";
CM_ SG_ 362 ABSIO "Antilock Brake System Indication On";
CM_ SG_ 362 ACCSysFltSts "Adaptive Cruise Control System Fault Status
";
CM_ SG_ 362 AutoHoldMsg "Autohold Message";
CM_ SG_ 362 AutoHoldSysSts "Auto Hold System Status";
CM_ SG_ 362 AutoMainBeamLghtReq "Auto Main Beam Light Request
";
CM_ SG_ 362 BrkSysRedBrkTlltReq "Brake System Red Brake Telltale Request";
CM_ SG_ 362 EnASSSta "Engine Auto Stop Start State";
CM_ SG_ 362 FCTASysFltSts "Front Cross Traffic Alert System Fault Status";
CM_ SG_ 362 FVCMBlkd "Front View Camera Module Blocked";
CM_ SG_ 362 FVCMFltSts "Front View Camera Module Fault Status";
CM_ SG_ 362 HDCSysSts "Hill Descent Control System Status";
CM_ SG_ 362 TCSOpngMd "Traction Control System Operating Mode";
CM_ SG_ 362 TCSOpngSts "Traction Control System Operating Status";
CM_ SG_ 362 VSEMd "Vehicle Stability Enhancement Mode";
CM_ SG_ 362 VSESts "Vehicle Stability Enhancement Status";
CM_ SG_ 596 BrkFludLvlLow "Brake Fluid Level Low";
CM_ SG_ 596 BrkFludLvlLowV "Brake Fluid Level Low Validity";
CM_ SG_ 1353 EnOilPrsLowIO "Engine Oil Pressure Low Indication On";
CM_ SG_ 934 StrgCDMSSetngDspCmd "Steering Continuous Drive Mode Switch Setting Display Command";
CM_ SG_ 76 BrkSysHillStAstAvlbl "Brake System Hill Start Assist Available";
CM_ SG_ 76 SLIFSts_ECM "Speed Limit Information Function Status_ecm
";
CM_ SG_ 76 SpdAstMdECM "Speed Assist Mode Front Infotainment Control Module";
CM_ SG_ 76 SpdAstSysStsECM "Speed Assist System Status Engine Control Module
";
CM_ SG_ 76 SpdAstSysTrgtSpd "Speed Assist System Target Speed
";
CM_ SG_ 76 TrgtSpdSrcSts "Target Speed Source Status
";
CM_ SG_ 313 LFCTAWrnng "Left Front Cross Traffic Alert Warning";
CM_ SG_ 313 RFCTAWrnng "Right Front Cross Traffic Alert Warning";
CM_ SG_ 553 RCTBPrflReq "Rear Cross Traffic Braking Prefill Request
";
CM_ SG_ 560 EnToqActuExtdRng "Engine Torque Actual Extended Range";
CM_ SG_ 819 FOTASts "Firmware Over The Air Status
";
CM_ SG_ 819 FOTAStsV "Firmware Over The Air Status Validity
";
CM_ SG_ 852 EmgcCallFlrSts "Emergency Call Failure Status
";
CM_ SG_ 852 EmgcCallTrigd "Emergency Call Triggered";
CM_ SG_ 501 AutocTrCmddGear_TCM "Automatic Transmission Commanded Gear";
CM_ SG_ 501 DrvrShftCtrlTrgtGear_TCM "Driver Shift Control Target Gear";
CM_ SG_ 501 TCM_025ms_PDU02_CRC "Wheel Ground Velocity Non Driven Checksum
Regarding high integrity requirement, a checksum signal is used for the bit field in same frame. The signal XOR operation is recommended for the calculation.";
CM_ SG_ 501 TrCrpMdA_TCM "Transmission Creep Mode Active";
CM_ SG_ 501 TrEngdSta_TCM "Transmission Engaged State";
CM_ SG_ 501 TrEngdStaV_TCM "Transmission Engaged State Validity";
CM_ SG_ 501 TrEstdGear_TCM "Transmission Estimated Gear";
CM_ SG_ 501 TrEstdGearV_TCM "Transmission Estimated Gear Validity";
CM_ SG_ 501 TrShftLvrPos_TCM "Transmission Shift Lever Position from TCM";
CM_ SG_ 501 TrShftLvrPosV_TCM "Transmission Shift Lever Position Validity from TCM";
CM_ SG_ 501 TrShftPtrnASts_TCM "Transmission Shift Pattern Active Status";
CM_ SG_ 501 TrTapUpTapDwnMdSts_TCM "Transmission Tap Up Tap Down Mode Status";
CM_ SG_ 1358 TrClThrmlProtnNotfn "Transmission Clutch Thermal Protection Notification";
CM_ SG_ 1358 TrEstdClCldnTemTrgtDsp "Transmission Estimated Clutch Cooldown Temperature Target Display";
CM_ SG_ 1358 TrEstdClTemDsp "Transmission Estimated Clutch Temperature Display";
CM_ SG_ 1358 TrNonEmsnRltdMalfA "Transmission Non Emissions Related Malfunction Active";
CM_ SG_ 1010 FLSeatHeatLvl "Front Left Seat Heat Level";
CM_ SG_ 1010 FLSeatVentLvl "Front Left Seat Vent Level";
CM_ SG_ 1010 FRSeatHeatLvl "Front Right Seat Heat Level";
CM_ SG_ 1010 FRSeatVentLvl "Front Right Seat Vent Level";
CM_ SG_ 761 MSMDrvrSeatHorzPos "Msm Driver Seat Horizontal Position";
CM_ SG_ 761 MSMDrvrSeatReclinePos "Msm Driver Seat Recline Position";
CM_ SG_ 761 MSMDrvrSeatTiltingPos "Msm Driver Seat Tilting Position";
CM_ SG_ 761 MSMDrvrSeatVerticalPos "Msm Driver Seat Vertical Position";
CM_ SG_ 761 MSMDrvrSeatZeroSt "Msm Driver Seat Zero Position Learning Status";
CM_ SG_ 761 SeatPosMmrySetSucdChmR "Seat Position Memory Set Succeed Chime Request
";
CM_ SG_ 761 StrgWhlHeatLvl "Steering Wheel Heat Level";
CM_ SG_ 576 PEPSAntFlt "Passive Entry Passive Start Antenna Fault";
CM_ SG_ 576 PEPSSSBFltSts "Passive Entry Passive Start Start Stop Button Fault Status
";
CM_ SG_ 518 PwrLftgtPos "Power Liftgate Position";
CM_ SG_ 518 PwrLftgtPosV "Power Liftgate Position Validity";
CM_ SG_ 763 PwrLftgtManuClsReq "Power Liftgate Manual Close Request";
CM_ SG_ 763 PwrLftgtPosSetngDspCmd "Power Liftgate Position Setting Display Command";
CM_ SG_ 763 PwrLftgtPutInParkReq "Power Liftgate Put In Park Request";
CM_ SG_ 763 PwrLftgtSts "Power Liftgate Status";
CM_ SG_ 1704 FICMEOLRx "FICM EOL Rx";
CM_ SG_ 1703 FICMEOLTx "FICM EOL Tx";
CM_ SG_ 1149 FLTirePrs "Front Left Tire Pressure";
CM_ SG_ 1149 FLTirePrsV "Front Left Tire Pressure Validity";
CM_ SG_ 1149 FLTireTem "Front Left Tire Temperature";
CM_ SG_ 1149 FLTireTemV "Front Left Tire Temperature Validity";
CM_ SG_ 1149 FRTirePrs "Front Right Tire Pressure";
CM_ SG_ 1149 FRTirePrsV "Front Right Tire Pressure Validity";
CM_ SG_ 1149 FRTireTem "Front Right Tire Temperature";
CM_ SG_ 1149 FRTireTemV "Front Right Tire Temperature Validity";
CM_ SG_ 1149 RLTirePrs "Rear Left Tire Pressure";
CM_ SG_ 1149 RLTirePrsV "Rear Left Tire Pressure Validity";
CM_ SG_ 1149 RLTireTem "Rear Left Tire Temperature";
CM_ SG_ 1149 RLTireTemV "Rear Left Tire Temperature Validity";
CM_ SG_ 1149 RRTirePrs "Rear Right Tire Pressure";
CM_ SG_ 1149 RRTirePrsV "Rear Right Tire Pressure Validity";
CM_ SG_ 1149 RRTireTem "Rear Right Tire Temperature";
CM_ SG_ 1149 RRTireTemV "Rear Right Tire Temperature Validity";
CM_ SG_ 1150 FLTireSts "Front Left Tire Status";
CM_ SG_ 1150 FRTireSts "Front Right Tire Status";
CM_ SG_ 1150 RLTireSts "Rear Left Tire Status";
CM_ SG_ 1150 RRTireSts "Rear Right Tire Status";
CM_ SG_ 1150 TPMSAutoLoctnCm "Tire Pressure Monitor System Auto Location Complete";
CM_ SG_ 1150 TPMSF "Tire Pressure Monitor System Failed";
CM_ SG_ 1150 TPMSIdficnLrnCm "Tire Pressure Monitor System Identification Learn Complete";
CM_ SG_ 1150 TPMSTirePrsLowIO "Tire Pressure Monitor System Tire Pressure Low Indication On";
CM_ SG_ 1150 TPMSWntrMdA "Tire Pressure Monitor System Winter Mode Active";
BA_DEF_ BO_ "GenMsgSendType" ENUM "cyclic","spontaneous","cyclicIfActive","spontaneousWithDelay","cyclicAndSpontaneous","cyclicAndSpontaneousWithDelay","IfActive","NoMsgSendType"; // [us]
BA_DEF_ BO_ "GenMsgCycleTime" FLOAT 0 300000; // [ms]
BA_DEF_ BO_ "GenMsgStartDelayTime" FLOAT 0 300000; // [ms]
BA_DEF_ BO_ "GenMsgDelayTime" FLOAT 0 300000; // [ms]
BA_DEF_ SG_ "GenSigSendType" ENUM "Cyclic","OnWrite","OnWriteWithRepetition","OnChange","OnChangeWithRepetition","IfActive","IfActiveWithRepetition","NoSigSendType";
BA_DEF_ SG_ "GenSigStartValue" FLOAT -1.7976931348623157E308 18446744073709551615;

BA_DEF_DEF_ "GenSigStartValue" 0;
BA_DEF_DEF_ "GenSigSendType" "Cyclic";
// Frame: CCP_CFCAN_FDR_FrP18
BA_ "GenMsgSendType" BO_ 987 1;
BA_ "GenMsgDelayTime" BO_ 987 100.000;
// Frame: CCP_CFCAN_FDR_FrP19
BA_ "GenMsgSendType" BO_ 766 1;
BA_ "GenMsgDelayTime" BO_ 766 100.000;
BA_ "GenSigStartValue" SG_ 766 NOPActvDspCmd 1;
// Frame: CCP_CFCAN_FDR_FrP20
BA_ "GenMsgSendType" BO_ 595 0;
BA_ "GenMsgCycleTime" BO_ 595 50.000;
BA_ "GenMsgStartDelayTime" BO_ 595 5.000;
BA_ "GenSigStartValue" SG_ 595 AutoLaneChngSwDspCmd 1;
// Frame: CCP_CFCAN_FrP00
BA_ "GenMsgSendType" BO_ 361 0;
BA_ "GenMsgCycleTime" BO_ 361 20.000;
BA_ "GenMsgStartDelayTime" BO_ 361 5.000;
// Frame: CCP_CFCAN_FrP01
BA_ "GenMsgSendType" BO_ 821 0;
BA_ "GenMsgCycleTime" BO_ 821 100.000;
BA_ "GenMsgStartDelayTime" BO_ 821 0.000;
BA_ "GenSigStartValue" SG_ 821 VehEnrgRdyLvl 1;
// Frame: CCP_CFCAN_FrP02
BA_ "GenMsgSendType" BO_ 497 0;
BA_ "GenMsgCycleTime" BO_ 497 20.000;
BA_ "GenMsgStartDelayTime" BO_ 497 5.000;
// Frame: CCP_CFCAN_FrP04
BA_ "GenMsgSendType" BO_ 803 0;
BA_ "GenMsgCycleTime" BO_ 803 100.000;
BA_ "GenMsgStartDelayTime" BO_ 803 20.000;
BA_ "GenSigStartValue" SG_ 803 BatVol 16383;
// Frame: CCP_CFCAN_FrP05
BA_ "GenMsgSendType" BO_ 794 0;
BA_ "GenMsgCycleTime" BO_ 794 100.000;
BA_ "GenMsgStartDelayTime" BO_ 794 20.000;
// Frame: CCP_CFCAN_FrP06
BA_ "GenMsgSendType" BO_ 872 0;
BA_ "GenMsgCycleTime" BO_ 872 100.000;
BA_ "GenMsgStartDelayTime" BO_ 872 5.000;
// Frame: CCP_CFCAN_FrP07
BA_ "GenMsgSendType" BO_ 814 0;
BA_ "GenMsgCycleTime" BO_ 814 100.000;
BA_ "GenMsgStartDelayTime" BO_ 814 5.000;
// Frame: CCP_CFCAN_FrP08
BA_ "GenMsgSendType" BO_ 886 0;
BA_ "GenMsgCycleTime" BO_ 886 100.000;
BA_ "GenMsgStartDelayTime" BO_ 886 15.000;
// Frame: CCP_CFCAN_FrP12
BA_ "GenMsgSendType" BO_ 1008 0;
BA_ "GenMsgCycleTime" BO_ 1008 250.000;
BA_ "GenMsgStartDelayTime" BO_ 1008 5.000;
// Frame: CCP_CFCAN_FrP14
BA_ "GenMsgSendType" BO_ 1344 0;
BA_ "GenMsgCycleTime" BO_ 1344 1000.000;
BA_ "GenMsgStartDelayTime" BO_ 1344 25.000;
BA_ "GenSigStartValue" SG_ 1344 BatSOC 187;
BA_ "GenSigStartValue" SG_ 1344 BatSOCSts 2;
// Frame: CCP_CFCAN_FVCM_FrP01
BA_ "GenMsgSendType" BO_ 433 1;
BA_ "GenMsgDelayTime" BO_ 433 20.000;
BA_ "GenSigStartValue" SG_ 433 LDWAdoWrnngDspCmd 2;
BA_ "GenSigStartValue" SG_ 433 LDWLKADspCmd 1;
BA_ "GenSigStartValue" SG_ 433 LDWLKAHptWrnngDspCmd 2;
BA_ "GenSigStartValue" SG_ 433 LDWSnstvtLvl 2;
// Frame: CCP_CFCAN_FVCM_FrP02
BA_ "GenMsgSendType" BO_ 557 0;
BA_ "GenMsgCycleTime" BO_ 557 50.000;
BA_ "GenMsgStartDelayTime" BO_ 557 0.000;
BA_ "GenSigStartValue" SG_ 557 ACCTJAMdSwDspCmd 1;
BA_ "GenSigStartValue" SG_ 557 HandOffStrgWhlDetnSta 1;
BA_ "GenSigStartValue" SG_ 557 TJAICADspCmd 1;
// Frame: CCP_CFCAN_FVCM_FrP03
BA_ "GenMsgSendType" BO_ 996 1;
BA_ "GenMsgDelayTime" BO_ 996 10.000;
// Frame: CCP_CFCAN_FVCM_FrP04
BA_ "GenMsgSendType" BO_ 997 1;
BA_ "GenMsgDelayTime" BO_ 997 10.000;
// Frame: CCP_CFCAN_FVCM_FrP05
BA_ "GenMsgSendType" BO_ 998 1;
BA_ "GenMsgDelayTime" BO_ 998 10.000;
// Frame: CCP_CFCAN_FVCM_FrP06
BA_ "GenMsgSendType" BO_ 999 1;
BA_ "GenMsgDelayTime" BO_ 999 10.000;
// Frame: CCP_CFCAN_FVCM_FrP12
BA_ "GenMsgSendType" BO_ 1011 1;
BA_ "GenMsgDelayTime" BO_ 1011 100.000;
// Frame: CCP_CFCAN_FVCM_FrP13
BA_ "GenMsgSendType" BO_ 1013 1;
BA_ "GenMsgDelayTime" BO_ 1013 100.000;
// Frame: CCP_CFCAN_FVCM_FrP14
BA_ "GenMsgSendType" BO_ 1014 1;
BA_ "GenMsgDelayTime" BO_ 1014 100.000;
// Frame: CCP_CFCAN_FVCM_FrP15
BA_ "GenMsgSendType" BO_ 1015 1;
BA_ "GenMsgDelayTime" BO_ 1015 100.000;
// Frame: CCP_CFCAN_HADS_FrP00
BA_ "GenMsgSendType" BO_ 337 1;
BA_ "GenMsgDelayTime" BO_ 337 10.000;
BA_ "GenSigStartValue" SG_ 337 HADS_020ms_PDU00_Reserve03 31;
BA_ "GenSigStartValue" SG_ 337 HADS_020ms_PDU00_Reserve04 15;
BA_ "GenSigStartValue" SG_ 337 HADS_020ms_PDU00_Reserve05 3;
// Frame: CCP_CFCAN_HDM_FrP00
BA_ "GenMsgSendType" BO_ 581 1;
BA_ "GenMsgDelayTime" BO_ 581 50.000;
BA_ "GenSigStartValue" SG_ 581 HDMLicVPrd 65535;
BA_ "GenSigStartValue" SG_ 581 HDMSysLicActvnSts 4;
// Frame: CCP_CFCAN_LADS_FrP02
BA_ "GenMsgSendType" BO_ 591 1;
BA_ "GenMsgDelayTime" BO_ 591 50.000;
// Frame: CCP_CFCAN_LADS_FrP03
BA_ "GenMsgSendType" BO_ 543 1;
BA_ "GenMsgDelayTime" BO_ 543 100.000;
// Frame: CCP_CFCAN_LADS_FrP10
BA_ "GenMsgSendType" BO_ 765 1;
BA_ "GenMsgDelayTime" BO_ 765 100.000;
// Frame: CCP_CFCAN_LADS_FrP11
BA_ "GenMsgSendType" BO_ 590 1;
BA_ "GenMsgDelayTime" BO_ 590 50.000;
BA_ "GenSigStartValue" SG_ 590 PDCCofignSts 1;
// Frame: CCP_CFCAN_LADS_FrP30
BA_ "GenMsgSendType" BO_ 1038 1;
BA_ "GenMsgDelayTime" BO_ 1038 100.000;
// Frame: CCP_CFCAN_LADS_FrP32
BA_ "GenMsgSendType" BO_ 605 1;
BA_ "GenMsgDelayTime" BO_ 605 50.000;
// Frame: CCP_CFCAN_LADS_FrP33
BA_ "GenMsgSendType" BO_ 1042 1;
BA_ "GenMsgDelayTime" BO_ 1042 50.000;
// Frame: CCP_CFCAN_NM
BA_ "GenMsgSendType" BO_ 1216 1;
BA_ "GenMsgDelayTime" BO_ 1216 10.000;
// Frame: CCP_CFCAN_SCM_FrP01
BA_ "GenMsgSendType" BO_ 778 1;
BA_ "GenMsgDelayTime" BO_ 778 25.000;
// Frame: CCP_CFCAN_SCS_FrP02
BA_ "GenMsgSendType" BO_ 204 0;
BA_ "GenMsgCycleTime" BO_ 204 20.000;
BA_ "GenMsgStartDelayTime" BO_ 204 0.000;
// Frame: CCP_CFCAN_SCS_FrP04
BA_ "GenMsgSendType" BO_ 862 0;
BA_ "GenMsgCycleTime" BO_ 862 100.000;
BA_ "GenMsgStartDelayTime" BO_ 862 25.000;
BA_ "GenSigStartValue" SG_ 862 SCS_020ms_PDU04_Reserve01 2147483647;
// Frame: CCP_CFCAN_SCS_FrP05
BA_ "GenMsgSendType" BO_ 565 1;
BA_ "GenMsgDelayTime" BO_ 565 20.000;
BA_ "GenSigStartValue" SG_ 565 WhlGndVelLDrvnV 1;
BA_ "GenSigStartValue" SG_ 565 WhlGndVelRDrvnV 1;
// Frame: CCP_CFCAN_SCS_FrP07
BA_ "GenMsgSendType" BO_ 811 1;
BA_ "GenMsgDelayTime" BO_ 811 10.000;
// Frame: CCP_CFCAN_SCS_FrP08
BA_ "GenMsgSendType" BO_ 332 1;
BA_ "GenMsgDelayTime" BO_ 332 20.000;
// Frame: CCP_CFCAN_SCS_FrP15
BA_ "GenMsgSendType" BO_ 425 1;
BA_ "GenMsgDelayTime" BO_ 425 20.000;
// Frame: CCP_CFCAN_SCS_FrP16
BA_ "GenMsgSendType" BO_ 339 1;
BA_ "GenMsgDelayTime" BO_ 339 20.000;
BA_ "GenSigStartValue" SG_ 339 WhlGndVelLNonDrvnV 1;
BA_ "GenSigStartValue" SG_ 339 WhlGndVelRNonDrvnV 1;
// Frame: CCP_CFCAN_SDM_FrP00
BA_ "GenMsgSendType" BO_ 355 1;
BA_ "GenMsgDelayTime" BO_ 355 20.000;
// Frame: CCP_CFCAN_SigGW_FrP00
BA_ "GenMsgSendType" BO_ 526 0;
BA_ "GenMsgCycleTime" BO_ 526 50.000;
BA_ "GenMsgStartDelayTime" BO_ 526 10.000;
// Frame: CCP_CFCAN_SigGW_FrP01
BA_ "GenMsgSendType" BO_ 222 0;
BA_ "GenMsgCycleTime" BO_ 222 10.000;
BA_ "GenMsgStartDelayTime" BO_ 222 5.000;
BA_ "GenSigStartValue" SG_ 222 EPSDrvngMdCtrlInh 1;
// Frame: CCP_CFCAN_SigGW_FrP02
BA_ "GenMsgSendType" BO_ 362 0;
BA_ "GenMsgCycleTime" BO_ 362 20.000;
BA_ "GenMsgStartDelayTime" BO_ 362 15.000;
BA_ "GenSigStartValue" SG_ 362 AEBSysSts 1;
BA_ "GenSigStartValue" SG_ 362 EnASSSta 1;
// Frame: CCP_CFCAN_SigGW_FrP03
BA_ "GenMsgSendType" BO_ 596 0;
BA_ "GenMsgCycleTime" BO_ 596 50.000;
BA_ "GenMsgStartDelayTime" BO_ 596 0.000;
// Frame: CCP_CFCAN_SigGW_FrP06
BA_ "GenMsgSendType" BO_ 1353 0;
BA_ "GenMsgCycleTime" BO_ 1353 500.000;
BA_ "GenMsgStartDelayTime" BO_ 1353 5.000;
// Frame: CCP_CFCAN_SigGW_FrP21
BA_ "GenMsgSendType" BO_ 934 0;
BA_ "GenMsgCycleTime" BO_ 934 100.000;
BA_ "GenMsgStartDelayTime" BO_ 934 0.000;
BA_ "GenSigStartValue" SG_ 934 StrgCDMSSetngDspCmd 50;
// Frame: CCP_CFCAN_SigGW_FrP22
BA_ "GenMsgSendType" BO_ 76 0;
BA_ "GenMsgCycleTime" BO_ 76 20.000;
BA_ "GenMsgStartDelayTime" BO_ 76 0.000;
// Frame: CCP_CFCAN_SigGW_FrP63
BA_ "GenMsgSendType" BO_ 313 0;
BA_ "GenMsgCycleTime" BO_ 313 20.000;
BA_ "GenMsgStartDelayTime" BO_ 313 0.000;
// Frame: CCP_CFCAN_SigGW_FrP67
BA_ "GenMsgSendType" BO_ 553 0;
BA_ "GenMsgCycleTime" BO_ 553 50.000;
BA_ "GenMsgStartDelayTime" BO_ 553 0.000;
BA_ "GenSigStartValue" SG_ 553 RCTBTrgtDcl 127;
BA_ "GenSigStartValue" SG_ 553 RDASysSta 1;
// Frame: CCP_CFCAN_SigGW_FrP90
BA_ "GenMsgSendType" BO_ 560 0;
BA_ "GenMsgCycleTime" BO_ 560 100.000;
BA_ "GenMsgStartDelayTime" BO_ 560 10.000;
// Frame: CCP_CFCAN_SWS_FrP00
BA_ "GenMsgSendType" BO_ 481 0;
BA_ "GenMsgCycleTime" BO_ 481 50.000;
BA_ "GenMsgStartDelayTime" BO_ 481 5.000;
// Frame: CCP_CFCAN_TBOX_FrP01
BA_ "GenMsgSendType" BO_ 819 0;
BA_ "GenMsgCycleTime" BO_ 819 100.000;
BA_ "GenMsgStartDelayTime" BO_ 819 20.000;
// Frame: CCP_CFCAN_TBOX_FrP02
BA_ "GenMsgSendType" BO_ 852 0;
BA_ "GenMsgCycleTime" BO_ 852 100.000;
BA_ "GenMsgStartDelayTime" BO_ 852 20.000;
// Frame: CCP_CFCAN_TCM_FrP02
BA_ "GenMsgSendType" BO_ 501 1;
BA_ "GenMsgDelayTime" BO_ 501 25.000;
BA_ "GenSigStartValue" SG_ 501 TCM_025ms_PDU02_Reserve03 1;
BA_ "GenSigStartValue" SG_ 501 TCM_025ms_PDU02_Reserve04 3;
BA_ "GenSigStartValue" SG_ 501 TCM_025ms_PDU02_Reserve05 255;
// Frame: CCP_CFCAN_TCM_FrP09
BA_ "GenMsgSendType" BO_ 1358 1;
BA_ "GenMsgDelayTime" BO_ 1358 500.000;
// Frame: CCP_CFCAN_TCM_FrP22
BA_ "GenMsgSendType" BO_ 839 1;
BA_ "GenMsgDelayTime" BO_ 839 100.000;
// Frame: CMM_CFCAN_FrP01
BA_ "GenMsgSendType" BO_ 770 0;
BA_ "GenMsgCycleTime" BO_ 770 100.000;
BA_ "GenMsgStartDelayTime" BO_ 770 0.000;
// Frame: Diag_CFCAN_FunReq
BA_ "GenMsgSendType" BO_ 2015 1;
BA_ "GenMsgDelayTime" BO_ 2015 20.000;
// Frame: Diag_CFCAN_PhyReq_FICM
BA_ "GenMsgSendType" BO_ 1889 1;
BA_ "GenMsgDelayTime" BO_ 1889 20.000;
// Frame: DIAG_PhysReq_VKR
BA_ "GenMsgSendType" BO_ 1546 1;
BA_ "GenMsgDelayTime" BO_ 1546 5.000;
BA_ "GenSigSendType" SG_ 1546 DiagnosticReqVKR 1;
// Frame: FLSM_CFCAN_FrP02
BA_ "GenMsgSendType" BO_ 1010 0;
BA_ "GenMsgCycleTime" BO_ 1010 100.000;
BA_ "GenMsgStartDelayTime" BO_ 1010 10.000;
BA_ "GenSigStartValue" SG_ 1010 AutoSeatHeatVentSts 3;
// Frame: FLSM_CFCAN_FrP03
BA_ "GenMsgSendType" BO_ 761 0;
BA_ "GenMsgCycleTime" BO_ 761 100.000;
BA_ "GenMsgStartDelayTime" BO_ 761 0.000;
BA_ "GenSigStartValue" SG_ 761 DrvrSeatAutoRclSts 3;
BA_ "GenSigStartValue" SG_ 761 DrvrSeatEasyExitSts 3;
BA_ "GenSigStartValue" SG_ 761 MSMDrvrSeatHorzPos 127;
BA_ "GenSigStartValue" SG_ 761 MSMDrvrSeatReclinePos 127;
BA_ "GenSigStartValue" SG_ 761 MSMDrvrSeatTiltingPos 127;
BA_ "GenSigStartValue" SG_ 761 MSMDrvrSeatVerticalPos 127;
// Frame: HUD_CFCAN_FrS01
BA_ "GenMsgSendType" BO_ 89 1;
BA_ "GenMsgDelayTime" BO_ 89 5.000;
BA_ "GenSigStartValue" SG_ 89 HUDBrtnsVal 11;
BA_ "GenSigSendType" SG_ 89 HUDBrtnsVal 1;
BA_ "GenSigStartValue" SG_ 89 HudColSetngMdSts 1;
BA_ "GenSigSendType" SG_ 89 HudColSetngMdSts 1;
BA_ "GenSigSendType" SG_ 89 HudStupAniSetngSts 1;
BA_ "GenSigStartValue" SG_ 89 HUDSwSts 2;
BA_ "GenSigSendType" SG_ 89 HUDSwSts 1;
BA_ "GenSigSendType" SG_ 89 HUDSysFltSts 1;
BA_ "GenSigSendType" SG_ 89 HudThemeSetngMdSts 1;
BA_ "GenSigStartValue" SG_ 89 HUDVertPosAutoAdjtSwSts 2;
BA_ "GenSigSendType" SG_ 89 HUDVertPosAutoAdjtSwSts 1;
BA_ "GenSigStartValue" SG_ 89 HUDVertPosDspCmd 11;
BA_ "GenSigSendType" SG_ 89 HUDVertPosDspCmd 1;
// Frame: HUD_CFCAN_FrS02
BA_ "GenMsgSendType" BO_ 90 1;
BA_ "GenMsgDelayTime" BO_ 90 5.000;
BA_ "GenSigSendType" SG_ 90 HUDNavReq 1;
// Frame: PEPS_CFCAN_FrP01
BA_ "GenMsgSendType" BO_ 576 0;
BA_ "GenMsgCycleTime" BO_ 576 50.000;
BA_ "GenMsgStartDelayTime" BO_ 576 0.000;
// Frame: PLCM_CFCAN_FrP00
BA_ "GenMsgSendType" BO_ 518 0;
BA_ "GenMsgCycleTime" BO_ 518 50.000;
BA_ "GenMsgStartDelayTime" BO_ 518 0.000;
// Frame: PLCM_CFCAN_FrP01
BA_ "GenMsgSendType" BO_ 763 0;
BA_ "GenMsgCycleTime" BO_ 763 100.000;
BA_ "GenMsgStartDelayTime" BO_ 763 0.000;
BA_ "GenSigStartValue" SG_ 763 PwrLftgtPosSetngDspCmd 127;
BA_ "GenSigStartValue" SG_ 763 PwrLftgtSts 6;
// Frame: Tester_CFCAN_EOLRX
BA_ "GenMsgSendType" BO_ 1704 1;
BA_ "GenMsgDelayTime" BO_ 1704 10.000;
BA_ "GenSigSendType" SG_ 1704 FICMEOLRx 1;
// Frame: Tester_CFCAN_EOLTX
BA_ "GenMsgSendType" BO_ 1703 1;
BA_ "GenMsgDelayTime" BO_ 1703 10.000;
BA_ "GenSigSendType" SG_ 1703 FICMEOLTx 1;
// Frame: TPMS_CFCAN_FrP01
BA_ "GenMsgSendType" BO_ 1149 0;
BA_ "GenMsgCycleTime" BO_ 1149 400.000;
BA_ "GenMsgStartDelayTime" BO_ 1149 0.000;
BA_ "GenSigStartValue" SG_ 1149 FLTirePrs 55;
BA_ "GenSigStartValue" SG_ 1149 FLTireTem 45;
BA_ "GenSigStartValue" SG_ 1149 FRTirePrs 55;
BA_ "GenSigStartValue" SG_ 1149 FRTireTem 45;
BA_ "GenSigStartValue" SG_ 1149 RLTirePrs 55;
BA_ "GenSigStartValue" SG_ 1149 RLTireTem 45;
BA_ "GenSigStartValue" SG_ 1149 RRTirePrs 55;
BA_ "GenSigStartValue" SG_ 1149 RRTireTem 45;
// Frame: TPMS_CFCAN_FrP02
BA_ "GenMsgSendType" BO_ 1150 0;
BA_ "GenMsgCycleTime" BO_ 1150 400.000;
BA_ "GenMsgStartDelayTime" BO_ 1150 0.000;
BA_ "GenSigStartValue" SG_ 1150 TPMSAutoLoctnCm 1;
VAL_ 987 Obj4Risk 0 "Obj4Risk_0_NoRisk" 1 "Obj4Risk_1_RiskExist";
VAL_ 987 Obj4Typ 0 "Obj4Typ_0_Unknown" 1 "Obj4Typ_1_Car" 2 "Obj4Typ_2_Truck" 3 "Obj4Typ_3_Motorbike" 4 "Obj4Typ_4_Bicycle" 5 "Obj4Typ_5_Reserved" 6 "Obj4Typ_6_Reserved" 7 "Obj4Typ_7_Reserved";
VAL_ 766 AutoLaneChngstyleDspCmd 0 "AutoLaneChngstyleDspCmd_0_Unavailable" 1 "AutoLaneChngstyleDspCmd_1_comfortable" 2 "AutoLaneChngstyleDspCmd_2_dynamic";
VAL_ 766 AVCamBlkd 0 "AVCamBlkd_0_No_Fault" 1 "AVCamBlkd_1_LF_Camera_Blocked_or_Fuzzy" 2 "AVCamBlkd_2_RF_Camera_Blocked_or_Fuzzy" 3 "AVCamBlkd_3_LR_Camera_Blocked_or_Fuzzy" 4 "AVCamBlkd_4_RR_Camera_Blocked_or_Fuzzy" 5 "AVCamBlkd_5_Rear_Camera_Blocked_or_Fuzzy" 6 "AVCamBlkd_6_2_cameras_Blocked_or_Fuzzy" 7 "AVCamBlkd_7_3_and_4_cameras_Blocked_or_Fuzzy";
VAL_ 766 CCSpdlVcCmdSwReqDspCmd 0 "CCSpdlVcCmdSwReqDspCmd_0_unavailable" 1 "CCSpdlVcCmdSwReqDspCmd_1_off" 2 "CCSpdlVcCmdSwReqDspCmd_2_on" 3 "CCSpdlVcCmdSwReqDspCmd_3_reserved";
VAL_ 766 CCSpdVcCmdCnfm 0 "CCSpdVcCmdCnfm_0_Noresponse" 1 "CCSpdVcCmdCnfm_1_SpeedisConfirmed" 2 "CCSpdVcCmdCnfm_2_DistanceisConfirmed" 3 "CCSpdVcCmdCnfm_3_Notintherange" 4 "CCSpdVcCmdCnfm_4_Alreadyinmaximunrange" 5 "CCSpdVcCmdCnfm_5_Alreadyinminimumrange" 6 "CCSpdVcCmdCnfm_6_reserved" 7 "CCSpdVcCmdCnfm_7_reserved";
VAL_ 766 DrvrVcCmdADASCtrlResp 0 "DrvrVcCmdADASCtrlResp_0_No_response" 1 "DrvrVcCmdADASCtrlResp_1_Condition_not_fullfilled" 2 "DrvrVcCmdADASCtrlResp_2_Only_ACC_active" 3 "DrvrVcCmdADASCtrlResp_3_SHWA_active" 4 "DrvrVcCmdADASCtrlResp_4_Left_side_lane_change_finished" 5 "DrvrVcCmdADASCtrlResp_5_Right_side_lane_change_finished" 6 "DrvrVcCmdADASCtrlResp_6_Waiting_for_Left_side_lane_change" 7 "DrvrVcCmdADASCtrlResp_7_Waiting_for_Right_side_lane_change" 8 "DrvrVcCmdADASCtrlResp_8_Reserved" 9 "DrvrVcCmdADASCtrlResp_9_Reserved" 10 "DrvrVcCmdADASCtrlResp_10_Reserved" 11 "DrvrVcCmdADASCtrlResp_11_Reserved" 12 "DrvrVcCmdADASCtrlResp_12_Reserved" 13 "DrvrVcCmdADASCtrlResp_13_Reserved" 14 "DrvrVcCmdADASCtrlResp_14_Reserved" 15 "DrvrVcCmdADASCtrlResp_15_Reserved";
VAL_ 766 EHCSwDspCmd 0 "EHCSwDspCmd_0_0_unavailable" 1 "EHCSwDspCmd_1_1_off" 2 "EHCSwDspCmd_2_2_on" 3 "EHCSwDspCmd_3_3_reserved";
VAL_ 766 IntlgntDrvMdSwDspCmd 0 "IntlgntDrvMdSwDspCmd_0_unavailable" 1 "IntlgntDrvMdSwDspCmd_1_off" 2 "IntlgntDrvMdSwDspCmd_2_on" 3 "IntlgntDrvMdSwDspCmd_3_reserved";
VAL_ 766 NOPActvDspCmd 0 "NOPActvDspCmd_0_unavailable" 1 "NOPActvDspCmd_1_off" 2 "NOPActvDspCmd_2_NOP" 3 "NOPActvDspCmd_3_TJA" 4 "NOPActvDspCmd_4_reserved" 5 "NOPActvDspCmd_5_reserved" 6 "NOPActvDspCmd_6_reserved" 7 "NOPActvDspCmd_7_reserved";
VAL_ 766 NOPVcRmndrSwDspCmd 0 "NOPVcRmndrSwDspCmd_0_unavailable" 1 "NOPVcRmndrSwDspCmd_1_standard" 2 "NOPVcRmndrSwDspCmd_2_simple" 3 "NOPVcRmndrSwDspCmd_3_silence";
VAL_ 595 ALCSysSts 0 "ALCSysSts_0_Off" 1 "ALCSysSts_1_Standby" 2 "ALCSysSts_2_ActiveRequest" 3 "ALCSysSts_3_ActiveControl" 4 "ALCSysSts_4_Passive" 5 "ALCSysSts_5_LaneChangeReturning" 6 "ALCSysSts_6_TOR" 7 "ALCSysSts_7_Reserved";
VAL_ 595 AutoLaneChngLLaneSts 0 "AutoLaneChngLLaneSts_0_norequest" 1 "AutoLaneChngLLaneSts_1_lanechangeinhibit" 2 "AutoLaneChngLLaneSts_2_waitingforlanechangestarting" 3 "AutoLaneChngLLaneSts_3_lanechangeinprogress" 4 "AutoLaneChngLLaneSts_4_lanechangesucces" 5 "AutoLaneChngLLaneSts_5_lanechangefailed" 6 "AutoLaneChngLLaneSts_6_lanechangesuppressbydriver" 7 "AutoLaneChngLLaneSts_7_ReturntoegoLanebydriver" 8 "AutoLaneChngLLaneSts_8_ReturntoegoLanebyALC" 9 "AutoLaneChngLLaneSts_9_Lanechangemanoeuvrewithrisk";
VAL_ 595 AutoLaneChngRLaneSts 0 "AutoLaneChngRLaneSts_0_norequest" 1 "AutoLaneChngRLaneSts_1_lanechangeinhibit" 2 "AutoLaneChngRLaneSts_2_waitingforlanechangestarting" 3 "AutoLaneChngRLaneSts_3_lanechangeinprogress" 4 "AutoLaneChngRLaneSts_4_lanechangesucces" 5 "AutoLaneChngRLaneSts_5_lanechangefailed" 6 "AutoLaneChngRLaneSts_6_lanechangesuppressbydriver" 7 "AutoLaneChngRLaneSts_7_ReturntoegoLanebydriver" 8 "AutoLaneChngRLaneSts_8_ReturntoegoLanebyALC" 9 "AutoLaneChngRLaneSts_9_Lanechangemanoeuvrewithrisk";
VAL_ 595 AutoLaneChngSwDspCmd 0 "AutoLaneChngSwDspCmd_0_unavailable" 1 "AutoLaneChngSwDspCmd_1_off" 2 "AutoLaneChngSwDspCmd_2_lanechangesuggestion" 3 "AutoLaneChngSwDspCmd_3_ALCwithdriver" 4 "AutoLaneChngSwDspCmd_4_ALCwithoutdriver_Reserved_" 5 "AutoLaneChngSwDspCmd_5_reserved" 6 "AutoLaneChngSwDspCmd_6_reserved" 7 "AutoLaneChngSwDspCmd_7_Reserved";
VAL_ 595 ILCActvnDircnDspCmd 0 "ILCActvnDircnDspCmd_0_Unavailable" 1 "ILCActvnDircnDspCmd_1_ILC_Not_Active" 2 "ILCActvnDircnDspCmd_2_ILC_Active_Left" 3 "ILCActvnDircnDspCmd_3_ILC_Active_Right" 4 "ILCActvnDircnDspCmd_4_Reserved" 5 "ILCActvnDircnDspCmd_5_Reserved" 6 "ILCActvnDircnDspCmd_6_Reserved" 7 "ILCActvnDircnDspCmd_7_Reserved";
VAL_ 595 ILCSwDspCmd 0 "ILCSwDspCmd_0_unavailable" 1 "ILCSwDspCmd_1_off" 2 "ILCSwDspCmd_2_on" 3 "ILCSwDspCmd_3_reserved";
VAL_ 595 ILCSysSts 0 "ILCSysSts_0_Off" 1 "ILCSysSts_1_Failure" 2 "ILCSysSts_2_Standby" 3 "ILCSysSts_3_Passive" 4 "ILCSysSts_4_Active_Request" 5 "ILCSysSts_5_Active_Control" 6 "ILCSysSts_6_Reserved" 7 "ILCSysSts_7_Reserved";
VAL_ 595 NOPSwDspCmd 0 "NOPSwDspCmd_0_unavailable" 1 "NOPSwDspCmd_1_off" 2 "NOPSwDspCmd_2_NOP_NdConfirm" 3 "NOPSwDspCmd_3_NOP_NotNdConfirm" 4 "NOPSwDspCmd_4_Reserved" 5 "NOPSwDspCmd_5_Reserved" 6 "NOPSwDspCmd_6_Reserved" 7 "NOPSwDspCmd_7_Reserved";
VAL_ 361 ADASAvlbly 0 "False" 1 "True";
VAL_ 361 APAAvlbly 0 "False" 1 "True";
VAL_ 361 DMSAvlbly 0 "False" 1 "True";
VAL_ 361 ECMAvlbly 0 "False" 1 "True";
VAL_ 361 EPBAvlbly 0 "False" 1 "True";
VAL_ 361 EPSAvlbly 0 "False" 1 "True";
VAL_ 361 HDMAvlbly 0 "False" 1 "True";
VAL_ 361 RDAAvlbly 0 "False" 1 "True";
VAL_ 361 SASAvlbly 0 "False" 1 "True";
VAL_ 361 SCMAvlbly 0 "False" 1 "True";
VAL_ 361 SCSAvlbly 0 "False" 1 "True";
VAL_ 361 SCUAvlbly 0 "False" 1 "True";
VAL_ 361 SDMAvlbly 0 "False" 1 "True";
VAL_ 361 TBOXAvlbly 0 "False" 1 "True";
VAL_ 361 TCMAvlbly 0 "False" 1 "True";
VAL_ 821 VehEnrgRdyLvl 0 "VehEnrgRdyLvl_0_level_0" 1 "VehEnrgRdyLvl_1_level_1" 2 "VehEnrgRdyLvl_2_level_2" 3 "VehEnrgRdyLvl_3_level_3" 4 "VehEnrgRdyLvl_4_level_4" 5 "VehEnrgRdyLvl_5_level_5" 6 "VehEnrgRdyLvl_6_level_6" 7 "VehEnrgRdyLvl_7_level_7";
VAL_ 821 VehEnrgRdyLvlV 0 "VehEnrgRdyLvlV_0_vaild" 1 "VehEnrgRdyLvlV_1_Invaild";
VAL_ 497 BPwrMdMstrstrAvlbly 0 "False" 1 "True";
VAL_ 497 SysOpnlMd 0 "SysOpnlMd_Normal_Mode" 1 "SysOpnlMd_Manufacturing_Mode" 2 "SysOpnlMd_Transit_Mode" 3 "SysOpnlMd_Show_Room" 4 "SysOpnlMd_Storage_Mode" 5 "SysOpnlMd_Diagnosic_or_Reprogramming_Reserve_" 6 "SysOpnlMd_6_Service_mode";
VAL_ 497 SysPwrMd 0 "SysPwrMd_0_Off" 1 "SysPwrMd_1_ACC" 2 "SysPwrMd_2_Run" 3 "SysPwrMd_3_Crank_Request";
VAL_ 497 SysPwrMdV 0 "Valid" 1 "Invalid";
VAL_ 497 SysVolMd 0 "SysPwrMd_h5_Normal" 1 "SysVolMd_Low_System_Voltage" 2 "SysVolMd_High_System_Voltage" 3 "SysVolMd_Illegal_System_Voltage";
VAL_ 497 SysVolMdV 0 "Valid" 1 "Invalid";
VAL_ 497 SysVolV 0 "Valid" 1 "Invalid";
VAL_ 803 BatAgngSta 0 "BatAgngSta_Good" 1 "BatAgngSta_Little_Aging" 2 "BatAgngSta_Middle_Aging" 3 "BatAgngSta_Replace_reminding" 4 "BatAgngSta_4_reserved" 5 "BatAgngSta_5_reserved" 6 "BatAgngSta_6_reserved" 7 "BatAgngSta_7_reserved";
VAL_ 794 VehCofignBodyCtrlrTyp 0 "VehCofignBodyCtrlrTyp_BC01" 1 "VehCofignBodyCtrlrTyp_BC02" 2 "VehCofignBodyCtrlrTyp_BC03" 3 "VehCofignBodyCtrlrTyp_3_Reserved" 4 "VehCofignBodyCtrlrTyp_4_Reserved" 5 "VehCofignBodyCtrlrTyp_5_Reserved" 6 "VehCofignBodyCtrlrTyp_6_Reserved" 7 "VehCofignBodyCtrlrTyp_7_Reserved";
VAL_ 794 VehCofignCCTyp 0 "VehCofignCCTyp_No_Equipped" 1 "VehCofignCCTyp_Standard" 2 "VehCofignCCTyp_ACC" 3 "VehCofignCCTyp_Reserved";
VAL_ 794 VehCofignEnTyp 0 "VehCofignEnTyp_G13D_GSL_DOHC_NON_TURBO_" 1 "VehCofignEnTyp_G14DT_SGE" 2 "VehCofignEnTyp_G15DT_SGE" 3 "VehCofignEnTyp_G15DT_GSL_DOHC_TURBO_" 4 "VehCofignEnTyp_G15D_BASE_GSL_DOHC_NON_TURBO_" 5 "VehCofignEnTyp_G15D_VCT_GSL_DOHC_NON_TURBO_VCT_" 6 "VehCofignEnTyp_G18D_GSL_DOHC_NON_TURBO_VCT_" 7 "VehCofignEnTyp_G18DT_GSL_DOHC_TURBO_" 8 "VehCofignEnTyp_G20D_GSL_DOHC_4_CYL_MFI_ALUM_" 9 "VehCofignEnTyp_G20D_GDI_GSL_TURBO_" 10 "VehCofignEnTyp_G24D_GSL_DOHC_4_CYL_SIDI_VVT_ALUM_" 11 "VehCofignEnTyp_G30D_GSL_DOHC_6_CYL_SIDI_VVT_ALUM_" 12 "VehCofignEnTyp_D19_DSL_TCI_";
VAL_ 794 VehCofignParkngBrkTyp 0 "VehCofignParkngBrkTyp_HDL_P_BRAKE" 1 "VehCofignParkngBrkTyp_FOOT_P_BRAKE" 2 "VehCofignParkngBrkTyp_ELEC_P_BRAKE" 3 "VehCofignParkngBrkTyp_Reserved";
VAL_ 794 VehCofignSlipCtrlTyp 0 "VehCofignSlipCtrlTyp_ABS" 1 "VehCofignSlipCtrlTyp_ESP" 2 "VehCofignSlipCtrlTyp_2_Reserved" 3 "VehCofignSlipCtrlTyp_3_Reserved";
VAL_ 794 VehCofignSpSt 0 "VehCofignSpSt_Equipped" 1 "VehCofignSpSt_No_Equipped";
VAL_ 794 VehCofignStrgTyp 0 "VehCofignStrgTyp_EPS" 1 "VehCofignStrgTyp_EHPS" 2 "VehCofignStrgTyp_HPS" 3 "VehCofignStrgTyp_Reserved";
VAL_ 794 VehCofignTPMSTyp 0 "VehCofignTPMSTyp_iTPMS" 1 "VehCofignTPMSTyp_TPMS" 2 "VehCofignTPMSTyp_No_Equipped" 3 "VehCofignTPMSTyp_Reserved";
VAL_ 794 VehCofignTrnsfCaseTyp 0 "VehCofignTrnsfCaseTyp_2WD" 1 "VehCofignTrnsfCaseTyp_P_TIME" 2 "VehCofignTrnsfCaseTyp_TOD" 3 "VehCofignTrnsfCaseTyp_AWD";
VAL_ 794 VehCofignTrTyp 0 "VehCofignTrTyp_DCT_6SHFT_DCT360B" 1 "VehCofignTrTyp_DCT_7SHFT_DCT250" 2 "VehCofignTrTyp_A_T_4SHFT" 3 "VehCofignTrTyp_A_T_4SHFT_NEW_AW" 4 "VehCofignTrTyp_A_T_5SHFT" 5 "VehCofignTrTyp_A_T_6SHFT" 6 "VehCofignTrTyp_A_T_7SHFT" 7 "VehCofignTrTyp_M_T_5SHFT" 8 "VehCofignTrTyp_M_T_6SHFT";
VAL_ 794 VehInfoBodyTyp 0 "VehInfoBodyTyp_Sedan" 1 "VehInfoBodyTyp_MPV" 2 "VehInfoBodyTyp_Hatchback" 3 "VehInfoBodyTyp_SUV" 4 "VehInfoBodyTyp_Cross";
VAL_ 794 VehInfoBrand 0 "VehInfoBrand_Roewe" 1 "VehInfoBrand_MG" 2 "VehInfoBrand_Shanghai" 3 "VehInfoBrand_Reserved";
VAL_ 794 VehInfoDrvHadlTyp 0 "VehInfoDrvHadlTyp_Left_Hand_Drive" 1 "VehInfoDrvHadlTyp_Right_Hand_Drive";
VAL_ 794 VehInfoEmsnRegn 0 "VehInfoEmsnRegn_CN_IV" 1 "VehInfoEmsnRegn_CN_V" 2 "VehInfoEmsnRegn_Beijing_V" 3 "VehInfoEmsnRegn_CN_V_" 4 "VehInfoEmsnRegn_CN_VI" 5 "VehInfoEmsnRegn_EURO_IV" 6 "VehInfoEmsnRegn_EURO_V" 7 "VehInfoEmsnRegn_EURO_V_" 8 "VehInfoEmsnRegn_EURO_VI";
VAL_ 794 VehInfoMdlYear 0 "VehInfoMdlYear_2000" 1 "VehInfoMdlYear_2001" 2 "VehInfoMdlYear_2002" 3 "VehInfoMdlYear_2003" 4 "VehInfoMdlYear_2004" 5 "VehInfoMdlYear_2005" 6 "VehInfoMdlYear_2006" 7 "VehInfoMdlYear_2007" 8 "VehInfoMdlYear_2008" 9 "VehInfoMdlYear_2009" 10 "VehInfoMdlYear_2010" 11 "VehInfoMdlYear_2011" 12 "VehInfoMdlYear_2012" 13 "VehInfoMdlYear_2013" 14 "VehInfoMdlYear_2014" 15 "VehInfoMdlYear_2015" 16 "VehInfoMdlYear_2016" 17 "VehInfoMdlYear_2017" 18 "VehInfoMdlYear_2018" 19 "VehInfoMdlYear_2019" 20 "VehInfoMdlYear_2020" 21 "VehInfoMdlYear_2021" 22 "VehInfoMdlYear_2022" 23 "VehInfoMdlYear_2023" 24 "VehInfoMdlYear_2024" 25 "VehInfoMdlYear_2025" 26 "VehInfoMdlYear_2026" 27 "VehInfoMdlYear_2027" 28 "VehInfoMdlYear_2028" 29 "VehInfoMdlYear_2029" 30 "VehInfoMdlYear_2030" 31 "VehInfoMdlYear_2031";
VAL_ 794 VehInfoMkt 0 "VehInfoMkt_China" 1 "VehInfoMkt_Europe" 2 "VehInfoMkt_Egypt" 3 "VehInfoMkt_Middle_East" 4 "VehInfoMkt_Thailand" 5 "VehInfoMkt_Russia" 6 "VehInfoMkt_Others";
VAL_ 794 VehInfoPf 0 "VehInfoPf_AS2" 1 "VehInfoPf_AM" 2 "VehInfoPf_AP3" 3 "VehInfoPf_EP2" 4 "VehInfoPf_IP3" 5 "VehInfoPf_IS" 6 "VehInfoPf_ZP" 7 "VehInfoPf_ZS";
VAL_ 872 VehDrvngMd 0 "VehDrvngMdET_0_No_Driving_Mode" 1 "VehDrvngMdET_1_Super_ECO" 2 "VehDrvngMdET_2_ECO" 3 "VehDrvngMdET_3_Normal" 4 "VehDrvngMdET_4_Sport" 5 "VehDrvngMdET_5_Super_Sport" 6 "VehDrvngMdET_6_Reserved" 7 "VehDrvngMdET_7_Customization_Mode";
VAL_ 872 VehDrvngMdCofign 0 "VehDrvngMdCofign_0_No_Driving_Mode" 1 "VehDrvngMdCofign_1_Eco_Normal_Sport" 2 "VehDrvngMdCofign_2_Eco_Normal_Sport_Custom" 3 "VehDrvngMdCofign_3_Normal_SuperSport" 4 "VehDrvngMdCofign_4_Reserved";
VAL_ 872 VehDrvngMdRmndr 0 "VehDrvngMdRmndr_0_No_Reminder" 1 "VehDrvngMdRmndr_1_Inhibit_Reminder" 2 "VehDrvngMdRmndr_2_Fault_Warning" 3 "VehDrvngMdRmndr_3_Reserved";
VAL_ 814 GenrSta 0 "GenrSta_generator_is_ok" 1 "GenrSta_generator_lost_communication" 2 "GenrSta_generator_failed" 3 "GenrSta_generator_running_in_default_state" 4 "GenrSta_4_Reserved" 5 "GenrSta_5_Reserved" 6 "GenrSta_6_Reserved" 7 "GenrSta_7_Reserved";
VAL_ 814 GwStrgCustSetngDspCmd 0 "GwStrgCustSetngDspCmd_Function_Disable" 1 "GwStrgCustSetngDspCmd_Comfortable_Mode" 2 "GwStrgCustSetngDspCmd_Normal_Mode" 3 "GwStrgCustSetngDspCmd_Sport_Mode";
VAL_ 886 PMDCSta 0 "PMDCSta_PMDC_is_OK" 1 "PMDCSta_PMDC_LIN_communication_failed" 2 "PMDCSta_PMDC_sensor_failed" 3 "PMDCSta_PMDC_DCDC_failed";
VAL_ 1008 OtsdAirTemCrValV 0 "Valid" 1 "Invalid";
VAL_ 1344 BatSOCSts 0 "BatSOCSts_deviation_greater_than_15_" 1 "BatSOCSts_deviation_less_than_15_" 2 "BatSOCSts_delivation_less_than_10_" 3 "BatSOCSts_illogical_Value";
VAL_ 1344 VehLdShedLvl 0 "No Power Risk" 1 "Low Power Risk" 2 "Middle Power Risk" 3 "High Power Risk" 4 "Power management direct current converter(PMDC)-broken" 5 "VehLdShedLvl_5_reserved" 6 "VehLdShedLvl_6_reserved" 7 "VehLdShedLvl_7_reserved";
VAL_ 1344 VehOdoV 0 "Valid" 1 "Invalid";
VAL_ 433 LDWAdoWrnngDspCmd 0 "LDWAdoWrnngDspCmd_Unavailable" 1 "LDWAdoWrnngDspCmd_off" 2 "LDWAdoWrnngDspCmd_on" 3 "LDWAdoWrnngDspCmd_reserved";
VAL_ 433 LDWLKAAudReq 0 "no_request" 1 "level_1" 2 "level_2" 3 "level_3";
VAL_ 433 LDWLKADspCmd 0 "LDWLKADspCmd_Unavailable" 1 "LDWLKADspCmd_off" 2 "LDWLKADspCmd_LDW" 3 "LDWLKADspCmd_LDP" 4 "LDWLKADspCmd_LKA" 5 "LDWLKADspCmd_ELK" 6 "LDWLKADspCmd_reserved2" 7 "LDWLKADspCmd_reserved3";
VAL_ 433 LDWLKAHptWrnngDspCmd 0 "LDWLKAHptWrnngDspCmd_unavailable" 1 "LDWLKAHptWrnngDspCmd_off" 2 "LDWLKAHptWrnngDspCmd_on" 3 "LDWLKAHptWrnngDspCmd_reserved";
VAL_ 433 LDWLKALVsulznReq 0 "LDWLKALVsulznReq_no_display" 1 "LDWLKALVsulznReq_line_tracking" 2 "LDWLKALVsulznReq_intervention" 3 "LDWLKALVsulznReq_warning" 4 "LDWLKALVsulznReq_intervention_warning" 5 "LDWLKALVsulznReq_Reserved1" 6 "LDWLKALVsulznReq_Reserved2" 7 "LDWLKALVsulznReq_Reserved3";
VAL_ 433 LDWLKARVsulznReq 0 "LDWLKARVsulznReq_no_display" 1 "LDWLKARVsulznReq_line_tracking" 2 "LDWLKARVsulznReq_intervention" 3 "LDWLKARVsulznReq_warning" 4 "LDWLKARVsulznReq_intervention_warning" 5 "LDWLKARVsulznReq_Reserved1" 6 "LDWLKARVsulznReq_Reserved2" 7 "LDWLKARVsulznReq_Reserved3";
VAL_ 433 LDWSnstvtLvl 0 "LDWSnstvtLvl_unavailable" 1 "LDWSnstvtLvl_Low" 2 "LDWSnstvtLvl_Standard" 3 "LDWSnstvtLvl_High";
VAL_ 433 LDWSysFltSts 0 "LDWSysFltSts_no_error" 1 "LDWSysFltSts_performance_degradation" 2 "LDWSysFltSts_system_temporary_unavailable" 3 "LDWSysFltSts_service_required" 4 "LDWSysFltSts_4_Reserved" 5 "LDWSysFltSts_5_Reserved" 6 "LDWSysFltSts_6_Reserved" 7 "LDWSysFltSts_7_Reserved";
VAL_ 433 LDWSysSts 0 "LDWSysSts_Off" 1 "LDWSysSts_Stand_by" 2 "LDWSysSts_Active" 3 "LDWSysSts_Override" 4 "LDWSysSts_service_required" 5 "LDWSysSts_system_temporary_unavailable" 6 "LDWSysSts_6_reserved" 7 "LDWSysSts_7_reserved";
VAL_ 433 LKASysFltSts 0 "LKASysFltSts_no_error" 1 "LKASysFltSts_performance_degradation" 2 "LKASysFltSts_system_temporary_unavailable" 3 "LKASysFltSts_service_required";
VAL_ 433 LKASysSts 0 "LKASysSts_Off" 1 "LKASysSts_Stand_by" 2 "LKASysSts_Active" 3 "LKASysSts_Override";
VAL_ 557 ACCTJAMdSwDspCmd 0 "ACCTJAMdSwDspCmd_0_unavailable" 1 "ACCTJAMdSwDspCmd_1_ACC" 2 "ACCTJAMdSwDspCmd_2_TJA" 3 "ACCTJAMdSwDspCmd_3_SHWA" 4 "ACCTJAMdSwDspCmd_4_Off" 5 "ACCTJAMdSwDspCmd_5_NOP" 6 "ACCTJAMdSwDspCmd_6_Reserved" 7 "ACCTJAMdSwDspCmd_7_Reserved";
VAL_ 557 HandOffStrgWhlDetnSta 0 "HandOffStrgWhlDetnSta_Hands_Off_level_1" 1 "HandOffStrgWhlDetnSta_Hands_On" 2 "HandOffStrgWhlDetnSta_Hands_Off_level_2" 3 "HandOffStrgWhlDetnSta_Hands_Off_level_3";
VAL_ 557 HandOffStrgWhlDetnStaV 0 "Valid" 1 "Invalid";
VAL_ 557 LKADrvrTkovReq 0 "False" 1 "True";
VAL_ 557 TJAICADspCmd 0 "TJAICADspCmd_unavailable" 1 "TJAICADspCmd_off" 2 "TJAICADspCmd_on" 3 "TJAICADspCmd_reserved";
VAL_ 557 TJAICAOpMd 0 "TJAICAOpMd_no_request" 1 "TJAICAOpMd_Object_following" 2 "TJAICAOpMd_Lane_center" 3 "TJAICAOpMd_combined_mode";
VAL_ 557 TJAICASysFltSts 0 "TJAICASysFltSts_no_error" 1 "TJAICASysFltSts_performance_degradation" 2 "TJAICASysFltSts_system_temporary_unavailable" 3 "TJAICASysFltSts_service_required" 4 "TJAICASysFltSts_ALC_Fault" 5 "TJAICASysFltSts_Reserved2" 6 "TJAICASysFltSts_Reserved3" 7 "TJAICASysFltSts_Reserved4";
VAL_ 557 TJAICASysSts 0 "TJAICASysSts_Off" 1 "TJAICASysSts_Stand_by" 2 "TJAICASysSts_Active" 3 "TJAICASysSts_Override" 4 "TJAICASysSts_4_Passive" 5 "TJAICASysSts_reserved2" 6 "TJAICASysSts_reserved3" 7 "TJAICASysSts_reserved4";
VAL_ 996 Lane0_location 0 "Lane0_location_Left" 1 "Lane0_location_Right" 2 "Lane0_location_Next_Left" 3 "Lane0_location_Next_Right";
VAL_ 996 Lane0_MarkerColor 0 "Lane0_MarkerColor_no_line" 1 "Lane0_MarkerColor_white" 2 "Lane0_MarkerColor_red" 3 "Lane0_MarkerColor_Lane0_yellow" 4 "Lane0_MarkerColor_other";
VAL_ 996 Lane0_MarkerType 0 "Lane0_MarkerType_no_line" 1 "Lane0_MarkerType_solid" 2 "Lane0_MarkerType_dashed" 3 "Lane0_MarkerType_curbstone" 4 "Lane0_MarkerType_grass" 5 "Lane0_MarkerType_Bot_Dott" 6 "Lane0_MarkerType_other";
VAL_ 998 Lane1_location 0 "Lane1_location_Left" 1 "Lane1_location_Right" 2 "Lane1_location_Next_Left" 3 "Lane1_location_Next_Right";
VAL_ 998 Lane1_MarkerColor 0 "Lane1_MarkerColor_no_line" 1 "Lane1_MarkerColor_white" 2 "Lane1_MarkerColor_red" 3 "Lane1_MarkerColor_yellow" 4 "Lane1_MarkerColor_other";
VAL_ 998 Lane1_MarkerType 0 "Lane1_MarkerType_no_line" 1 "Lane1_MarkerType_solid" 2 "Lane1_MarkerType_dashed" 3 "Lane1_MarkerType_curbstone" 4 "Lane1_MarkerType_grass" 5 "Lane1_MarkerType_Bot_Dott" 6 "Lane1_MarkerType_other";
VAL_ 1011 Lane2_location 0 "Lane2_location_0_Left" 1 "Lane2_location_1_Right" 2 "Lane2_location_2_NextLeft" 3 "Lane2_location_3_NextRight";
VAL_ 1011 Lane2_MarkerColor 0 "Lane2_MarkerColor_0_no_line" 1 "Lane2_MarkerColor_1_white" 2 "Lane2_MarkerColor_2_red" 3 "Lane2_MarkerColor_3_yellow" 4 "Lane2_MarkerColor_4_other";
VAL_ 1011 Lane2_MarkerType 0 "Lane2_MarkerType_0_no_line" 1 "Lane2_MarkerType_1_solid" 2 "Lane2_MarkerType_2_dashed" 3 "Lane2_MarkerType_3_curbstone" 4 "Lane2_MarkerType_4_grass" 5 "Lane2_MarkerType_5_Bot_Dott" 6 "Lane2_MarkerType_6_other";
VAL_ 1014 Lane3_location 0 "Lane3_location_0_Left" 1 "Lane3_location_1_Right" 2 "Lane3_location_2_NextLeft" 3 "Lane3_location_3_NextRight";
VAL_ 1014 Lane3_MarkerColor 0 "Lane3_MarkerColor_0_no_line" 1 "Lane3_MarkerColor_1_white" 2 "Lane3_MarkerColor_2_red" 3 "Lane3_MarkerColor_3_yellow" 4 "Lane3_MarkerColor_4_other";
VAL_ 1014 Lane3_MarkerType 0 "Lane3_MarkerType_0_no_line" 1 "Lane3_MarkerType_1_solid" 2 "Lane3_MarkerType_2_dashed" 3 "Lane3_MarkerType_3_curbstone" 4 "Lane3_MarkerType_4_grass" 5 "Lane3_MarkerType_5_Bot_Dott" 6 "Lane3_MarkerType_6_other";
VAL_ 337 DistOutODD 0 "DistOutODD_0_no_display" 1 "DistOutODD_1_25m" 2 "DistOutODD_2_50m" 3 "DistOutODD_3_75m" 4 "DistOutODD_4_100m" 5 "DistOutODD_5_125m" 6 "DistOutODD_6_150m" 7 "DistOutODD_7_175m" 8 "DistOutODD_8_200m" 9 "DistOutODD_9_500m" 10 "DistOutODD_10_750m" 11 "DistOutODD_11_1000m" 12 "DistOutODD_12_1500m" 13 "DistOutODD_13_reserved" 14 "DistOutODD_14_reserved";
VAL_ 337 NOPMsgReq 0 "NOPMsgReq_0_No_display" 1 "NOPMsgReq_1_NOP_not_available" 2 "NOPMsgReq_2_NOP_has_activated" 3 "NOPMsgReq_3_NOP_has_deactivated" 4 "NOPMsgReq_4_Vehicle_is_inside_of_NOP_ODD_area" 5 "NOPMsgReq_5_NOP_will_be_deactivated_please_pay_attention_to_road_conditions" 6 "NOPMsgReq_6_Please_turn_on_the_left_direction_indicator_light_to_confirm_lane_change" 7 "NOPMsgReq_7_Please_turn_on_the_right_direction_indicator_light_to_confirm_lane_change" 8 "NOPMsgReq_8_The_road_conditions_are_complicated_please_change_lanes_manually" 9 "NOPMsgReq_9_There_are_many_trucks_please_be_careful" 10 "NOPMsgReq_10_Waiting_for_the_vehicle_in_adjacent_lane_to_pass" 11 "NOPMsgReq_11_Vehicle_will_change_to_the_left_lane" 12 "NOPMsgReq_12_Vehicle_will_change_to_the_right_lane" 13 "NOPMsgReq_13_Vehicle_will_merge_into_the_ramp" 14 "NOPMsgReq_14_Vehicle_will_merge_into_the_main_road" 15 "NOPMsgReq_15_Vehicle_will_change_to_the_fast_lane" 16 "NOPMsgReq_16_Vehicle_will_change_lane_due_to_cutting_off_line_ahead" 17 "NOPMsgReq_17_Vehicle_will_change_lane_due_to_front_low_speed_object" 18 "NOPMsgReq_18_Vehicle_will_drive_off_the_main_road" 19 "NOPMsgReq_19_Vehicle_will_drive_off_the_ramp" 20 "NOPMsgReq_20_Vehicle_will_accelerate_for_merging_into_main_road" 21 "NOPMsgReq_21_Vehicle_will_accelerate_for_evading_trucks" 22 "NOPMsgReq_22_Vehicle_will_deccelerate_for_evading_trucks" 23 "NOPMsgReq_23_Vehicle_will_deccelerate_for_adjacent_lane_object" 24 "NOPMsgReq_24_Vehicle_will_deccelerate_for_ramp_ahead" 25 "NOPMsgReq_25_Vehicle_will_deccelerate_for_curve_road_ahead" 26 "NOPMsgReq_26_Vehicle_will_deccelerate_for_tunnel_ahead" 27 "NOPMsgReq_27_Vehicle_will_deccelerate_for_close_cutting_in_object" 28 "NOPMsgReq_28_ILC_activated_to_the_left_side" 29 "NOPMsgReq_29_ILC_activated_to_the_right_side" 30 "NOPMsgReq_30_ACC_set_speed_will_be_increased" 31 "NOPMsgReq_31_ACC_set_speed_will_be_decreased" 32 "NOPMsgReq_32_Please_be_care_of_surrounding_road_conditions" 33 "NOPMsgReq_33_Please_take_over" 34 "NOPMsgReq_34_HDM_is_not_available" 35 "NOPMsgReq_35_IPS_is_not_available" 36 "NOPMsgReq_36_SD_map_is_not_available" 37 "NOPMsgReq_37_ALC_is_not_available" 38 "NOPMsgReq_38_Current_lane_line_is_not_clear" 39 "NOPMsgReq_39_Current_road_radius_is_too_small" 40 "NOPMsgReq_40_Current_vehicle_is_not_in_the_middle_of_lane" 41 "NOPMsgReq_41_Current_lane_is_too_wide" 42 "NOPMsgReq_42_Current_lane_is_too_narrow" 43 "NOPMsgReq_43_Current_vehicle_speed_is_too_high" 44 "NOPMsgReq_44_Ready_to_lane_change_to_left_before_changing_to_another_highway" 45 "NOPMsgReq_45_Ready_to_lane_change_to_right_before_changing_to_another_highway" 46 "NOPMsgReq_46_Ready_to_lane_change_to_left_in_the_ramp" 47 "NOPMsgReq_47_Ready_to_lane_change_to_right_in_the_ramp" 48 "NOPMsgReq_48_Ready_to_enter_NOP_ODD" 49 "NOPMsgReq_49_Already_exit_NOP_ODD" 50 "NOPMsgReq_50_Ready_to_enter_tunnel" 51 "NOPMsgReq_51_Ready_to_enter_construction_zone" 52 "NOPMsgReq_52_Vehicle_will_decelerate_for_abrupt_slope_ahead" 53 "NOPMsgReq_53_EHC_is_activated" 54 "NOPMsgReq_54_Vehicle_will_accelerate_for_evading_rear_vehicle" 55 "NOPMsgReq_55_Lane_change_is_failed" 56 "NOPMsgReq_56_NOP_cannot_be_activated_due_to_long_time_hands_off" 57 "NOPMsgReq_57_Vehicle_will_change_lane_for_low_speed_object_in_adjacent_lane" 58 "NOPMsgReq_58_Please_hands_on_for_lane_change" 59 "NOPMsgReq_59_NOP_cannot_be_activated_due_to_bad_weather" 60 "NOPMsgReq_60_Reserve" 61 "NOPMsgReq_61_Reserve" 62 "NOPMsgReq_62_Reserve" 63 "NOPMsgReq_63_Reserve";
VAL_ 337 NOPSysFltSts 0 "NOPSysFltSts_0_No_error" 1 "NOPSysFltSts_1_Performance_degradation" 2 "NOPSysFltSts_2_System_temporary_unavailable" 3 "NOPSysFltSts_3_Service_required" 4 "NOPSysFltSts_4_Reserved";
VAL_ 337 NOPSysSts 0 "NOPSysSts_0_Off" 1 "NOPSysSts_1_Passive" 2 "NOPSysSts_2_Standby" 3 "NOPSysSts_3_Active" 4 "NOPSysSts_4_Override" 5 "NOPSysSts_5_Idle" 6 "NOPSysSts_6_Reserved" 7 "NOPSysSts_7_Reserved" 8 "NOPSysSts_8_Reserved" 9 "NOPSysSts_9_Reserved" 10 "NOPSysSts_10_Reserved" 11 "NOPSysSts_11_Reserved" 12 "NOPSysSts_12_Reserved" 13 "NOPSysSts_13_Reserved" 14 "NOPSysSts_14_Reserved" 15 "NOPSysSts_15_Reserved";
VAL_ 337 SHWAEPBAppdReq 0 "SHWAEPBAppdReq_0_NoRequest" 1 "SHWAEPBAppdReq_1_Request" 2 "SHWAEPBAppdReq_2_Reserved" 3 "SHWAEPBAppdReq_3_Reserved";
VAL_ 337 SHWAIndSts 0 "SHWAIndSts_0_notready" 1 "SHWAIndSts_1_HFrecommend" 2 "SHWAIndSts_2_HFactive" 3 "SHWAIndSts_3_HFapproachboundary" 4 "SHWAIndSts_4_HFmodeexit" 5 "SHWAIndSts_5_Reserved" 6 "SHWAIndSts_6_Reserved" 7 "SHWAIndSts_7_Reserved" 8 "SHWAIndSts_8_Reserved" 9 "SHWAIndSts_9_Reserved" 10 "SHWAIndSts_10_Reserved" 11 "SHWAIndSts_11_Reserved" 12 "SHWAIndSts_12_Reserved" 13 "SHWAIndSts_13_Reserved" 14 "SHWAIndSts_14_Reserved" 15 "SHWAIndSts_15_Reserved";
VAL_ 337 SHWASysFltSts 0 "SHWASysFltSts_0_noerror" 1 "SHWASysFltSts_1_performancedegradation" 2 "SHWASysFltSts_2_systemtemporaryunavailable" 3 "SHWASysFltSts_3_servicerequired" 4 "SHWASysFltSts_4_Reserved" 5 "SHWASysFltSts_5_Reserved" 6 "SHWASysFltSts_6_Reserved" 7 "SHWASysFltSts_7_Reserved";
VAL_ 337 SHWASysMsg 0 "SHWASysMsg_0_nodisplay" 1 "SHWASysMsg_1_SHWAnotavailable" 2 "SHWASysMsg_2_Pleasefocusontheroad" 3 "SHWASysMsg_3_Approachingunreleasedhighwaysection" 4 "SHWASysMsg_4_Please_select_cruise_mode" 5 "SHWASysMsg_5_SHWAhandsfreenotavailable" 6 "SHWASysMsg_6_LKAsystemtemporaryunavailable" 7 "SHWASysMsg_7_LKAservicerequired" 8 "SHWASysMsg_8_LDWsystemtemporaryunavailable" 9 "SHWASysMsg_9_LDWservicerequired" 10 "SHWASysMsg_10_Lanemarkingsnotpresent" 11 "SHWASysMsg_11_Roadconditioninsufficient" 12 "SHWASysMsg_12_Unreleasedhighwaysection" 13 "SHWASysMsg_13_Pleasetakeabreak_Drowsinessdetected" 14 "SHWASysMsg_14_Wronggearselected" 15 "SHWASysMsg_15_Behaveaccordingtotheintendedsystemusage" 16 "SHWASysMsg_16_ESPintervention" 17 "SHWASysMsg_17_ESPnotavailable" 18 "SHWASysMsg_18_Cameraunabletoseeface" 19 "SHWASysMsg_19_Seatbeltunfastened" 20 "SHWASysMsg_20_Outsidespeedrange" 21 "SHWASysMsg_21_Neighbouringvehicletooclose" 22 "SHWASysMsg_22_Frontvehicletooclose" 23 "SHWASysMsg_23_TJAsystemtemporaryunavailable" 24 "SHWASysMsg_24_TJAservicerequired" 25 "SHWASysMsg_25_Speedoutofrangeremind" 26 "SHWASysMsg_26_Pleaseholdthesteer" 27 "SHWASysMsg_27_startup_remind" 28 "SHWASysMsg_28_Reserved" 29 "SHWASysMsg_29_Reserved" 30 "SHWASysMsg_30_Reserved" 31 "SHWASysMsg_31_Reserved";
VAL_ 337 SHWASysReqHzrdLghtReqSts 0 "SHWASysReqHzrdLghtReqSts_0_No_Request" 1 "SHWASysReqHzrdLghtReqSts_1_Request" 2 "SHWASysReqHzrdLghtReqSts_2_Reserved" 3 "SHWASysReqHzrdLghtReqSts_3_Reserved";
VAL_ 337 SHWASysSts 0 "SHWASysSts_0_Off" 1 "SHWASysSts_1_Passive" 2 "SHWASysSts_2_Stand_by" 3 "SHWASysSts_3_Active" 4 "SHWASysSts_4_Override" 5 "SHWASysSts_5_TOR" 6 "SHWASysSts_6_Safestop" 7 "SHWASysSts_7_Prohibition" 8 "SHWASysSts_8_Reserved" 9 "SHWASysSts_9_Reserved" 10 "SHWASysSts_10_Reserved" 11 "SHWASysSts_11_Reserved" 12 "SHWASysSts_12_Reserved" 13 "SHWASysSts_13_Reserved" 14 "SHWASysSts_14_Reserved" 15 "SHWASysSts_15_Reserved";
VAL_ 337 SHWASysTakeOver 0 "SHWASysTakeOver_0_norequest" 1 "SHWASysTakeOver_1_warninglevel1" 2 "SHWASysTakeOver_2_warninglevel2" 3 "SHWASysTakeOver_3_warninglevel3_EmergencyStop_" 4 "SHWASysTakeOver_4_warninglevel4_Prohibition_" 5 "SHWASysTakeOver_5_Reserved" 6 "SHWASysTakeOver_6_Reserved" 7 "SHWASysTakeOver_7_Reserved" 8 "SHWASysTakeOver_8_Reserved" 9 "SHWASysTakeOver_9_Reserved" 10 "SHWASysTakeOver_10_Reserved" 11 "SHWASysTakeOver_11_Reserved" 12 "SHWASysTakeOver_12_Reserved" 13 "SHWASysTakeOver_13_Reserved" 14 "SHWASysTakeOver_14_Reserved" 15 "SHWASysTakeOver_15_Reserved";
VAL_ 581 HDMLicVPrd 65535 "Unknown";
VAL_ 581 HDMSysFltSts 0 "HDMSysFltSts_0_NoError" 1 "HDMSysFltSts_1_HDMError_ServiceRequired" 2 "HDMSysFltSts_2_Reserved" 3 "HDMSysFltSts_3_Reserved";
VAL_ 581 HDMSysIMUCalSts 0 "HDMSysIMUCalSts_0_Unknown" 1 "HDMSysIMUCalSts_1_CalibrationinProcess" 2 "HDMSysIMUCalSts_2_Calibrated";
VAL_ 581 HDMSysLicActvnSts 0 "HDMSysLicActvnSts_0_Unconfigured" 1 "HDMSysLicActvnSts_1_LicenseUnactivated" 2 "HDMSysLicActvnSts_2_LicenseActivated" 3 "HDMSysLicActvnSts_3_LicenseExpired" 4 "HDMSysLicActvnSts_4_Unknown" 5 "HDMSysLicActvnSts_5_Reserved" 6 "HDMSysLicActvnSts_6_Reserved" 7 "HDMSysLicActvnSts_7_Reserved";
VAL_ 591 APASts 0 "APASts_Disable" 1 "APASts_Standby" 2 "APASts_Semi_APA_Active" 3 "APASts_Fully_APA_Active" 4 "APASts_Failed";
VAL_ 543 ParkngOutBkCrsSts 0 "ParkngOutBkCrsSts_0_invalid" 1 "ParkngOutBkCrsSts_1_valid";
VAL_ 543 ParkngOutBkLCrsSts 0 "ParkngOutBkLCrsSts_0_invalid" 1 "ParkngOutBkLCrsSts_1_valid";
VAL_ 543 ParkngOutBkRCrsSts 0 "ParkngOutBkRCrsSts_0_invalid" 1 "ParkngOutBkRCrsSts_1_valid";
VAL_ 543 ParkngOutDircnSelResult 0 "ParkngOutDircnSelResult_0_none" 1 "ParkngOutDircnSelResult_1_Front_Left_Cross" 2 "ParkngOutDircnSelResult_2_Front_Left_Parallel" 3 "ParkngOutDircnSelResult_3_Front_Out" 4 "ParkngOutDircnSelResult_4_Front_Right_Cross" 5 "ParkngOutDircnSelResult_5_Front_Right_Parallel" 6 "ParkngOutDircnSelResult_6_Back_Out" 7 "ParkngOutDircnSelResult_7_Back_Left_Cross" 8 "ParkngOutDircnSelResult_8_Back_Right_Cross" 9 "ParkngOutDircnSelResult_9_Reserved" 10 "ParkngOutDircnSelResult_10_Reserved" 11 "ParkngOutDircnSelResult_11_Reserved" 12 "ParkngOutDircnSelResult_12_Reserved" 13 "ParkngOutDircnSelResult_13_Reserved" 14 "ParkngOutDircnSelResult_14_Reserved" 15 "ParkngOutDircnSelResult_15_Reserved";
VAL_ 543 ParkngOutFLCrsSts 0 "ParkngOutFLCrsSts_0_invalid" 1 "ParkngOutFLCrsSts_1_valid";
VAL_ 543 ParkngOutFLParllSts 0 "ParkngOutFLParllSts_0_invalid" 1 "ParkngOutFLParllSts_1_valid";
VAL_ 543 ParkngOutFRCrsSts 0 "ParkngOutFRCrsSts_0_invalid" 1 "ParkngOutFRCrsSts_1_valid";
VAL_ 543 ParkngOutFRParllSts 0 "ParkngOutFRParllSts_0_invalid" 1 "ParkngOutFRParllSts_1_valid";
VAL_ 543 ParkngOutFrtCrsSts 0 "ParkngOutFrtCrsSts_0_invalid" 1 "ParkngOutFrtCrsSts_1_valid";
VAL_ 765 AVMCalMdReqResp_LADS 0 "AVMCalMdReqResp_LADS_0_NoRequest" 1 "AVMCalMdReqResp_LADS_1_Start" 2 "AVMCalMdReqResp_LADS_2_Inprocess" 3 "AVMCalMdReqResp_LADS_3_Success" 4 "AVMCalMdReqResp_LADS_4_Failed" 5 "AVMCalMdReqResp_LADS_5_Reserve" 6 "AVMCalMdReqResp_LADS_6_Reserve" 7 "AVMCalMdReqResp_LADS_7_Reserve";
VAL_ 765 AVMSysSts_LADS 0 "AVMSysSts_0_Standby" 1 "AVMSysSts_1_Active" 2 "AVMSysSts_2_Fault" 3 "AVMSysSts_3_Reserved";
VAL_ 590 FrtPDCAudWrnng 0 "FrtPDCAudWrnng_0_NoObstacle" 1 "FrtPDCAudWrnng_1_Range1" 2 "FrtPDCAudWrnng_2_Range2" 3 "FrtPDCAudWrnng_3_Range3" 4 "FrtPDCAudWrnng_4_Range4" 5 "FrtPDCAudWrnng_5_Range5" 6 "FrtPDCAudWrnng_6_Range6" 7 "FrtPDCAudWrnng_7_Range7" 8 "FrtPDCAudWrnng_8_Range8" 9 "FrtPDCAudWrnng_9_Range9" 10 "FrtPDCAudWrnng_10_Range10" 11 "FrtPDCAudWrnng_11_Range11" 12 "FrtPDCAudWrnng_12_Range12" 13 "FrtPDCAudWrnng_13_Range13" 14 "FrtPDCAudWrnng_14_Range14" 15 "FrtPDCAudWrnng_15_Range15";
VAL_ 590 PDCCofignSts 0 "PDCCofignSts_3_rear_sensors" 1 "PDCCofignSts_4_rear_sensors" 2 "PDCCofignSts_4_rear_sensors_and_2_front_side_sensors" 3 "PDCCofignSts_4_rear_sensors_and_4_front_sensors" 4 "PDCCofignSts_2_rear_sensors" 5 "PDCCofignSts_5_Reserved" 6 "PDCCofignSts_6_Reserved" 7 "PDCCofignSts_7_Reserved";
VAL_ 590 PDCSysSts 0 "PDCSysSts_System_OK" 1 "PDCSysSts_System_initialization_sucessful" 2 "PDCSysSts_System_Failed" 3 "PDCSysSts_System_Disabled" 4 "PDCSysSts_Front_PDC_Disabled" 5 "PDCSysSts_Front_PDC_Failed" 6 "PDCSysSts_Rear_PDC_Failed" 7 "PDCSysSts_Rear_PDC_Disabled";
VAL_ 590 RrPDCAudWrnng 0 "RrPDCAudWrnng_0_NoObstacle" 1 "RrPDCAudWrnng_1_Range1" 2 "RrPDCAudWrnng_2_Range2" 3 "RrPDCAudWrnng_3_Range3" 4 "RrPDCAudWrnng_4_Range4" 5 "RrPDCAudWrnng_5_Range5" 6 "RrPDCAudWrnng_6_Range6" 7 "RrPDCAudWrnng_7_Range7" 8 "RrPDCAudWrnng_8_Range8" 9 "RrPDCAudWrnng_9_Range9" 10 "RrPDCAudWrnng_10_Range10" 11 "RrPDCAudWrnng_11_Range11" 12 "RrPDCAudWrnng_12_Range12" 13 "RrPDCAudWrnng_13_Range13" 14 "RrPDCAudWrnng_14_Range14" 15 "RrPDCAudWrnng_15_Range15";
VAL_ 1038 MUWSwSts 0 "MUWSwSts_0_On" 1 "MUWSwSts_1_Off" 2 "MUWSwSts_2_Reserved";
VAL_ 605 HD_AVMCurView 0 "HD_AVMCurView_0_Norequest" 1 "HD_AVMCurView_1_2D_Frontviewrequest_2D_" 2 "HD_AVMCurView_2_2D_Front_wide_viewrequest_2D_" 3 "HD_AVMCurView_3_Rearviewrequest_2D_" 4 "HD_AVMCurView_4_2D_Rear_wide_viewrequest_2D_" 5 "HD_AVMCurView_5_2D_Left_Rightviewrequest_2D_" 6 "HD_AVMCurView_6_frontviewrequest_3D_" 7 "HD_AVMCurView_7_rearviewrequest_3D_" 8 "HD_AVMCurView_8_leftviewrequest_3D_" 9 "HD_AVMCurView_9_rightviewrequest_3D_" 10 "HD_AVMCurView_10_front_leftviewrequest_3D_" 11 "HD_AVMCurView_11_front_rightviewrequest_3D_" 12 "HD_AVMCurView_12_rear_leftviewrequest_3D_" 13 "HD_AVMCurView_13_rear_rightviewrequest_3D_" 14 "HD_AVMCurView_14_Surroundviewrequest_3D_" 16 "HD_AVMCurView_16_frontobstacleview" 18 "HD_AVMCurView_18_rearobstacleview" 19 "HD_AVMCurView_19_frontstereogarageview" 20 "HD_AVMCurView_20_rearstereogarageview" 21 "HD_AVMCurView_21_left_wing_view" 22 "HD_AVMCurView_22_right_wing_view";
VAL_ 605 HD_AVMsysrdy 0 "HD_AVMsysrdy_0_not_ready" 1 "HD_AVMsysrdy_1_ready";
VAL_ 1042 FrtPDCAudWrnng_LADS 0 "FrtPDCAudWrnng_LADS_0_NoObstacle" 1 "FrtPDCAudWrnng_LADS_1_Range1" 2 "FrtPDCAudWrnng_LADS_2_Range2" 3 "FrtPDCAudWrnng_LADS_3_Range3" 4 "FrtPDCAudWrnng_LADS_4_Range4" 5 "FrtPDCAudWrnng_LADS_5_Range5" 6 "FrtPDCAudWrnng_LADS_6_Range6" 7 "FrtPDCAudWrnng_LADS_7_Range7" 8 "FrtPDCAudWrnng_LADS_8_Range8" 9 "FrtPDCAudWrnng_LADS_9_Range9" 10 "FrtPDCAudWrnng_LADS_10_Range10" 11 "FrtPDCAudWrnng_LADS_11_Range11" 12 "FrtPDCAudWrnng_LADS_12_Range12" 13 "FrtPDCAudWrnng_LADS_13_Range13" 14 "FrtPDCAudWrnng_LADS_14_Range14" 15 "FrtPDCAudWrnng_LADS_15_Range15";
VAL_ 1042 LADSInfoDispReqToICM 0 "LADSInfoDispReqToICM_0_Reserved" 2 "LADSInfoDispReqToICM_2_VehiclespeedistoohighAPAsystemabort" 3 "LADSInfoDispReqToICM_3_Vehiclespeedistoohighpleasebeslowdown" 4 "LADSInfoDispReqToICM_4_Parkingslotsearching" 5 "LADSInfoDispReqToICM_5_ParkingExit" 7 "LADSInfoDispReqToICM_7_Pleasestopthecar" 9 "LADSInfoDispReqToICM_9_ParkingpausepleaseconfirminAPP" 10 "LADSInfoDispReqToICM_10_PressstartforAPAvehiclecontrolorchooseRPA" 11 "LADSInfoDispReqToICM_11_Parkingpausepleaseconfirmsafety" 12 "LADSInfoDispReqToICM_12_EPBoperatedParkingexit" 13 "LADSInfoDispReqToICM_13_Noobstacleparkoutbyyourself" 14 "LADSInfoDispReqToICM_14_Pleasepressstartparkout" 15 "LADSInfoDispReqToICM_15_Parkingpausepleasepresscontinue" 16 "LADSInfoDispReqToICM_16_Pleasefastenthesafetybelt" 17 "LADSInfoDispReqToICM_17_Pleaseclosethedoor" 18 "LADSInfoDispReqToICM_18_LADSunavailableparkingexit" 19 "LADSInfoDispReqToICM_19_Leftsteering" 22 "LADSInfoDispReqToICM_22_RPAreadyPleaseleavethecaranduseapp" 29 "LADSInfoDispReqToICM_29_Rightsteering" 30 "LADSInfoDispReqToICM_30_PleasesteponthebrakeandpresstheSSB" 33 "LADSInfoDispReqToICM_33_Barrierexistpleaseremove" 34 "LADSInfoDispReqToICM_34_Steeringwheelhasbeenturned" 35 "LADSInfoDispReqToICM_35_Acceleratorpressed" 37 "LADSInfoDispReqToICM_37_Shiftoperated" 38 "LADSInfoDispReqToICM_38_Adjustmenttimeexceeded" 39 "LADSInfoDispReqToICM_39_Slopetoobig" 40 "LADSInfoDispReqToICM_40_Disturbeovertime" 41 "LADSInfoDispReqToICM_41_Spacetoosmall" 44 "LADSInfoDispReqToICM_44_Pleasereleasebrakeandpayattentiontosurroundingsusingactivecontrolmeasureifnecessary" 45 "LADSInfoDispReqToICM_45_Parkingisongoing" 46 "LADSInfoDispReqToICM_46_Parkingmanoeuvrehascompleted:Pleasetakeovervehicle" 48 "LADSInfoDispReqToICM_48_SystemovertimeAPAsystemquit" 63 "LADSInfoDispReqToICM_63_EnvironmentChanged" 65 "LADSInfoDispReqToICM_65_Pleasestopthecarfirst" 66 "LADSInfoDispReqToICM_66_PleaseshifttoPfirst" 67 "LADSInfoDispReqToICM_67_PleaseapplytheEPBfirst" 68 "LADSInfoDispReqToICM_68_Pleasestartthevehicle" 69 "LADSInfoDispReqToICM_69_Pleaseunlockthevehicle" 70 "LADSInfoDispReqToICM_70_Pleasetakeover" 97 "LADSInfoDispReqToICM_97_Tirepressureabnormal" 98 "LADSInfoDispReqToICM_98_Pleaseturnofftheenginemanually" 99 "LADSInfoDispReqToICM_99_Pleaselockthevehicle" 100 "LADSInfoDispReqToICM_100_Longtimenotoperated" 101 "LADSInfoDispReqToICM_101_Enginestarterror" 102 "LADSInfoDispReqToICM_102_Hazardstarterror" 103 "LADSInfoDispReqToICM_103_Unlockfailed" 104 "LADSInfoDispReqToICM_104_SSBpressed" 105 "LADSInfoDispReqToICM_105_Bluetoothinactive" 106 "LADSInfoDispReqToICM_106_Haschangedtonormaldrivemode" 107 "LADSInfoDispReqToICM_107_ACCactivedLADSexit" 108 "LADSInfoDispReqToICM_108_AEBactivedLADSexit" 109 "LADSInfoDispReqToICM_109_TJAactivedLADSexit" 110 "LADSInfoDispReqToICM_110_Lockedthecar" 111 "LADSInfoDispReqToICM_111_NotchooseRPA" 112 "LADSInfoDispReqToICM_112_APPexitpleasemovetoFICM" 113 "LADSInfoDispReqToICM_113_Vehicledoesnotstop" 114 "LADSInfoDispReqToICM_114_Barrierinslotchangeanother" 128 "LADSInfoDispReqToICM_128_Pleasepressthebrakepadelvehiclecontrolhasnotstarted" 129 "LADSInfoDispReqToICM_129_Parkingpausepleasepressthebutton" 130 "LADSInfoDispReqToICM_130_Detectingiftheslotspaceisenough" 146 "LADSInfoDispReqToICM_146_Systemselfchecking" 147 "LADSInfoDispReqToICM_147_Pleaseselectparkoutdirection" 148 "LADSInfoDispReqToICM_148_NRCDisready" 149 "LADSInfoDispReqToICM_149_ParkingpausepleasepresscontinueinAPP" 160 "LADSInfoDispReqToICM_160_Engineisnotready" 161 "LADSInfoDispReqToICM_161_LADSfaultcannotopen" 162 "LADSInfoDispReqToICM_162_LADSbusycannotopen" 163 "LADSInfoDispReqToICM_163_Speedistoohighcannotopen" 164 "LADSInfoDispReqToICM_164_Vehicleisnotstopcannotopen" 165 "LADSInfoDispReqToICM_165_ADASisactived";
VAL_ 1042 PDCCofignSts_LADS 0 "PDCCofignSts_LADS_0_3rearsensors" 1 "PDCCofignSts_LADS_1_4rearsensors" 2 "PDCCofignSts_LADS_2_4rearsensorsand2frontsidesensors" 3 "PDCCofignSts_LADS_3_4rearsensorsand4frontsensors" 4 "PDCCofignSts_LADS_4_2rearsensors" 5 "PDCCofignSts_LADS_5_Reserved" 6 "PDCCofignSts_LADS_6_Reserved" 7 "PDCCofignSts_LADS_7_Reserved";
VAL_ 1042 PDCSysSts_LADS 0 "PDCSysSts_LADS_0_SystemOK" 1 "PDCSysSts_LADS_1_Systeminitializationsucessful" 2 "PDCSysSts_LADS_2_SystemFailed" 3 "PDCSysSts_LADS_3_SystemDisabled" 4 "PDCSysSts_LADS_4_FrontPDCDisabled" 5 "PDCSysSts_LADS_5_FrontPDCFailed" 6 "PDCSysSts_LADS_6_RearPDCFailed" 7 "PDCSysSts_LADS_7_RearPDCDisabled";
VAL_ 1042 RrPDCAudWrnng_LADS 0 "RrPDCAudWrnng_LADS_0_NoObstacle" 1 "RrPDCAudWrnng_LADS_1_Range1" 2 "RrPDCAudWrnng_LADS_2_Range2" 3 "RrPDCAudWrnng_LADS_3_Range3" 4 "RrPDCAudWrnng_LADS_4_Range4" 5 "RrPDCAudWrnng_LADS_5_Range5" 6 "RrPDCAudWrnng_LADS_6_Range6" 7 "RrPDCAudWrnng_LADS_7_Range7" 8 "RrPDCAudWrnng_LADS_8_Range8" 9 "RrPDCAudWrnng_LADS_9_Range9" 10 "RrPDCAudWrnng_LADS_10_Range10" 11 "RrPDCAudWrnng_LADS_11_Range11" 12 "RrPDCAudWrnng_LADS_12_Range12" 13 "RrPDCAudWrnng_LADS_13_Range13" 14 "RrPDCAudWrnng_LADS_14_Range14" 15 "RrPDCAudWrnng_LADS_15_Range15";
VAL_ 778 SCMCustSetngDspCmd 0 "SCMCustSetngDspCmd_0_Function_Disable" 1 "SCMCustSetngDspCmd_1_Comfort_Mode" 2 "SCMCustSetngDspCmd_2_Normal_Mode" 3 "SCMCustSetngDspCmd_3_Sport_Mode";
VAL_ 778 SusFlrSts 0 "SusFlrSts_0_AdcNoFailure" 1 "SusFlrSts_1_AdcTemporaryFailure" 2 "SusFlrSts_2_AdcFailure" 3 "SusFlrSts_3_Reserved";
VAL_ 778 SusMdSts 0 "SusMdSts_0_Function_Disable" 1 "SusMdSts_1_Comfort_Mode" 2 "SusMdSts_2_Normal_Mode" 3 "SusMdSts_3_Sport_Mode";
VAL_ 204 LNonDrvnWhlRotlDistV 0 "Valid" 1 "Invalid";
VAL_ 204 LNonDrvnWhlRotlRstOcd 0 "False" 1 "True";
VAL_ 204 RNonDrvnWhlRotlDistV 0 "Valid" 1 "Invalid";
VAL_ 204 RNonDrvnWhlRotlRstOcd 0 "False" 1 "True";
VAL_ 862 EPBAppcnSts 0 "EPBAppcnSts_Unknown" 1 "EPBAppcnSts_Park_Brake_Applied" 2 "EPBAppcnSts_Park_Brake_Released" 3 "EPBAppcnSts_Park_Brake_Application_in_Progress";
VAL_ 862 EPBAvlblySts 0 "EPBAvlblySts_Unavailable_Not_Failed" 1 "EPBAvlblySts_Available_Not_Failed" 2 "EPBAvlblySts_Unavailable_Failed_Applied" 3 "EPBAvlblySts_Unavailable_Failed_Released" 4 "EPBAvlblySts_Unavailable_Failed_other" 5 "EPBAvlblySts_Unused_and_Reserved_1" 6 "EPBAvlblySts_Unused_and_Reserved_2" 7 "EPBAvlblySts_Unused_and_Reserved_3";
VAL_ 862 EPBCCCanclReqd 0 "False" 1 "True";
VAL_ 862 EPBFlrSts 0 "EPBFlrSts_No_error_in_EPB" 1 "EPBFlrSts_Error_in_EPB";
VAL_ 862 EPBSts 0 "EPBSts_0_Released" 1 "EPBSts_1_Applied" 2 "EPBSts_2_Fault";
VAL_ 862 EPBSwSts 0 "NotActive" 1 "Release" 2 "Apply";
VAL_ 862 EPBSwStsV 0 "Valid" 1 "Invalid";
VAL_ 862 EPBSysAudWrnngReq 0 "EPBSysAudWrnngReq_Off" 1 "EPBSysAudWrnngReq_Warning_1" 2 "EPBSysAudWrnngReq_Warning_2";
VAL_ 862 EPBSysDspMsgReq 0 "EPBSysDspMsgReq_Off" 1 "EPBSysDspMsgReq_Message_1" 2 "EPBSysDspMsgReq_Message_2" 3 "EPBSysDspMsgReq_Message_3" 4 "EPBSysDspMsgReq_Message_4" 5 "EPBSysDspMsgReq_Message_5" 6 "EPBSysDspMsgReq_Message_6" 7 "EPBSysDspMsgReq_Message_7";
VAL_ 862 EPBSysStsIndReq 0 "EPBSysStsIndReq_No_Indication" 1 "EPBSysStsIndReq_Continuous_Indication" 2 "EPBSysStsIndReq_Flash_Rate_1_Indication" 3 "EPBSysStsIndReq_Flash_Rate_2_Indication";
VAL_ 862 EPBSysWrnngIndReq 0 "EPBSysWrnngIndReq_No_Indication" 1 "EPBSysWrnngIndReq_Continuous_Indication" 2 "EPBSysWrnngIndReq_Flash_Rate_1_Indication" 3 "EPBSysWrnngIndReq_Flash_Rate_2_Indication";
VAL_ 565 WhlGndVelLDrvnV 0 "Valid" 1 "Invalid";
VAL_ 565 WhlGndVelRDrvnV 0 "Valid" 1 "Invalid";
VAL_ 811 DistRCAvgDrvnV 0 "Valid" 1 "Invalid";
VAL_ 811 DistRCAvgNonDrvnRstOcd 0 "False" 1 "True";
VAL_ 811 DistRCAvgNonDrvnV 0 "Valid" 1 "Invalid";
VAL_ 332 VehDynYawRateV 0 "Valid" 1 "Invalid";
VAL_ 332 VSELatAccV 0 "Valid" 1 "Invalid";
VAL_ 332 VSELongtAccV 0 "Valid" 1 "Invalid";
VAL_ 425 VehSpdAvgDrvnV 0 "Valid" 1 "Invalid";
VAL_ 425 VehSpdAvgNonDrvnV 0 "Valid" 1 "Invalid";
VAL_ 339 WhlGndVelLNonDrvnV 0 "Valid" 1 "Invalid";
VAL_ 339 WhlGndVelRNonDrvnV 0 "Valid" 1 "Invalid";
VAL_ 355 AirbagDpl 0 "False" 1 "True";
VAL_ 355 AirbagSysFltIndCmd 0 "AirbagSysFltIndCmd_drive_lamp_OFF" 1 "AirbagSysFltIndCmd_drive_lamp_ON" 2 "AirbagSysFltIndCmd_drive_lamp_Flashing" 3 "AirbagSysFltIndCmd_3_reserved";
VAL_ 355 DrvrSbltAtc 0 "False" 1 "True";
VAL_ 355 DrvrSbltAtcV 0 "Valid" 1 "Invalid";
VAL_ 355 FasnDrvrSbltIndCmd 0 "FasnDrvrSbltIndCmd_Drive_lamp_OFF" 1 "FasnDrvrSbltIndCmd_Drive_lamp_ON" 2 "FasnDrvrSbltIndCmd_Drive_lamp_Flashing" 3 "FasnDrvrSbltIndCmd_Signal_not_available";
VAL_ 355 FasnFrtPsngSbltIndCmd 0 "FasnFrtPsngSbltIndCmd_Drive_lamp_OFF" 1 "FasnFrtPsngSbltIndCmd_Drive_lamp_ON" 2 "FasnFrtPsngSbltIndCmd_Drive_lamp_Flashing" 3 "FasnFrtPsngSbltIndCmd_Signal_not_available";
VAL_ 355 FasnSbltAudRmndr 0 "False" 1 "True";
VAL_ 355 FasnSecRowLSbltIndCmd 0 "FasnSecRowLSbltIndCmd_Off_Indication" 1 "FasnSecRowLSbltIndCmd_On_Indication" 2 "FasnSecRowLSbltIndCmd_Flashing_Indication" 3 "FasnSecRowLSbltIndCmd_Reserved";
VAL_ 355 FasnSecRowMidSbltIndCmd 0 "FasnSecRowMidSbltIndCmd_Off_Indication" 1 "FasnSecRowMidSbltIndCmd_On_Indication" 2 "FasnSecRowMidSbltIndCmd_Flashing_Indication" 3 "FasnSecRowMidSbltIndCmd_reserved";
VAL_ 355 FasnSecRowRSbltIndCmd 0 "FasnSecRowRSbltIndCmd_Off_Indication" 1 "FasnSecRowRSbltIndCmd_On_Indication" 2 "FasnSecRowRSbltIndCmd_Flashing_Indication" 3 "FasnSecRowRSbltIndCmd_Reserved";
VAL_ 355 FasnThrdRowLSbltIndCmd 0 "FasnThrdRowLSbltIndCmd_Off_Indication" 1 "FasnThrdRowLSbltIndCmd_On_Indication" 2 "FasnThrdRowLSbltIndCmd_Flashing_Indication" 3 "FasnThrdRowLSbltIndCmd_Reserved";
VAL_ 355 FasnThrdRowMidSbltIndCmd 0 "FasnThrdRowMidSbltIndCmd_Off_Indication" 1 "FasnThrdRowMidSbltIndCmd_On_Indication" 2 "FasnThrdRowMidSbltIndCmd_Flashing_Indication" 3 "FasnThrdRowMidSbltIndCmd_Reserved";
VAL_ 355 FasnThrdRowRSbltIndCmd 0 "FasnThrdRowRSbltIndCmd_Off_Indication" 1 "FasnThrdRowRSbltIndCmd_On_Indication" 2 "FasnThrdRowRSbltIndCmd_Flashing_Indication" 3 "FasnThrdRowRSbltIndCmd_Reserved";
VAL_ 355 FrtPsngAirbagSwSts 0 "FrtPsngAirbagSwSts_The_Front_Passenger_airbag_Switch_can_not_be_operated" 1 "FrtPsngAirbagSwSts_Passenger_Airbag_ON_Status" 2 "FrtPsngAirbagSwSts_Passenger_Airbag_OFF_Status" 3 "FrtPsngAirbagSwSts_Reserve";
VAL_ 355 FrtPsngSbltAtc 0 "False" 1 "True";
VAL_ 355 FrtPsngSbltAtcV 0 "Valid" 1 "Invalid";
VAL_ 526 ASLSts 0 "ASLSts_Off" 1 "ASLSts_Active_Limiting" 2 "ASLSts_Standby" 3 "ASLSts_Entry_condition_incorrect" 4 "ASLSts_Active_Overspeed" 5 "ASLSts_Fault" 6 "ASLSts_6_reserved" 7 "ASLSts_7_reserved";
VAL_ 526 CCCnstSpdA 0 "False" 1 "True";
VAL_ 526 PtCustSetngDspCmd 0 "PtCustSetngDspCmd_Function_Disable" 1 "PtCustSetngDspCmd_Super_ECO" 2 "PtCustSetngDspCmd_ECO" 3 "PtCustSetngDspCmd_Normal" 4 "PtCustSetngDspCmd_Sport" 5 "PtCustSetngDspCmd_Super_Sport" 6 "PtCustSetngDspCmd_6_Reserved" 7 "PtCustSetngDspCmd_7_Reserved";
VAL_ 526 TrWrnngDsp 0 "TrWrnngDsp_0_Normal" 1 "TrWrnngDsp_1_Park_System_Release_Failure" 2 "TrWrnngDsp_2_Park_Application_Failure" 3 "TrWrnngDsp_3_Park_Sensor_Failure" 4 "TrWrnngDsp_4_Select_Back_P_N_to_Resume_Driving_Function" 5 "TrWrnngDsp_5_Reserve" 6 "TrWrnngDsp_6_Park_Lock_Not_Engaged" 7 "TrWrnngDsp_7_Gearbox_In_Position_Neutral" 8 "TrWrnngDsp_8_Driver_Presence_Unknown_In_Drive_Or_Reverse" 9 "TrWrnngDsp_9_Engine_Start_if_want_shift";
VAL_ 222 EPSDrvngMdCtrlInh 0 "False" 1 "True";
VAL_ 222 SCUActrMvmntSts 0 "SCUActrMvmntSts_Actuator_Stop" 1 "SCUActrMvmntSts_ActuatorGo_out_of_P" 2 "SCUActrMvmntSts_Actuator_Go_Into_P" 3 "SCUActrMvmntSts_3_Reserved";
VAL_ 222 SCUFltLvlWrnng 0 "SCUFltLvlWrnng_No_Fault" 1 "SCUFltLvlWrnng_SCU_Limited_Fault" 2 "SCUFltLvlWrnng_SCU_Critical_Fault" 3 "SCUFltLvlWrnng_Transmission_Wrong_Gear_feedback";
VAL_ 222 SCUShifterOpngRmndr 0 "SCUShifterOpngRmndr_0_No_Reminder_Request" 1 "SCUShifterOpngRmndr_1_Please_Press_The_Unlock_Button" 2 "SCUShifterOpngRmndr_2_Please_Slam_On_The__Brake_Pedal" 3 "SCUShifterOpngRmndr_3_Please_Press_The__Unlock_Button_And_Slam_On_The__Brake_Pedal" 4 "SCUShifterOpngRmndr_4_Speed_Too_High_Go_Into_P_not_allowed" 5 "SCUShifterOpngRmndr_5_Speed_Too_High_Go_Into_R_not_allowed" 6 "SCUShifterOpngRmndr_6_Security_condition_not_met" 7 "SCUShifterOpngRmndr_7_shift_the_lever_to_left_postion";
VAL_ 222 StrgCustSetngDspCmd 0 "StrgCustSetngDspCmd_Function_Disable" 1 "StrgCustSetngDspCmd_Comfortable_Mode" 2 "StrgCustSetngDspCmd_Normal_Mode" 3 "StrgCustSetngDspCmd_Sport_Mode";
VAL_ 222 UsrDfnSlotValid_LADS 0 "UsrDfnSlotValid_LADS_0_Default" 1 "UsrDfnSlotValid_LADS_1_SlotVaild" 2 "UsrDfnSlotValid_LADS_2_SlotInvaild";
VAL_ 362 ABSIO 0 "False" 1 "True";
VAL_ 362 ACCSysFltSts 0 "ACCSysFltSts_No_Error" 1 "ACCSysFltSts_Performance_Degradation" 2 "ACCSysFltSts_System_Temporary_Unvailable" 3 "ACCSysFltSts_Service_Required" 4 "ACCSysFltSts_4_Reserved1" 5 "ACCSysFltSts_5_Reserved2" 6 "ACCSysFltSts_6_Reserved3" 7 "ACCSysFltSts_7_Reserved4";
VAL_ 362 ACCSysSts 0 "ACCSysSts_0_Off" 1 "ACCSysSts_Stand_By" 2 "ACCSysSts_2_Active" 3 "ACCSysSts_3_Override" 4 "ACCSysSts_Brake_Only" 5 "ACCSysSts_Standstill_Active" 6 "ACCSysSts_Standstill_Wait" 7 "ACCSysSts_7_Passive";
VAL_ 362 AEBSysFltSts 0 "AEBSysFltSts_No_Error" 1 "AEBSysFltSts_Performance_Degradation" 2 "AEBSysFltSts_System_Temporary_Unvailable" 3 "AEBSysFltSts_Service_Required" 4 "AEBSysFltSts_Reserved1" 5 "AEBSysFltSts_Reserved2" 6 "AEBSysFltSts_Reserved3" 7 "AEBSysFltStsReserved4";
VAL_ 362 AEBSysSts 0 "AEBSysSts_Off" 1 "AEBSysSts_On" 2 "AEBSysSts_Disable" 3 "AEBSysSts_Override" 4 "AEBSysSts_Active" 5 "AEBSysSts_5_Reserved1" 6 "AEBSysSts_6_Reserved2" 7 "AEBSysSts_7_Reserved";
VAL_ 362 AutoHoldMsg 0 "AutoHoldMsg_0_reserved" 1 "AutoHoldMsg_Seat_belt_not_fastend" 2 "AutoHoldMsg_Press_brake_pedal" 3 "AutoHoldMsg_Autohold_standby" 4 "AutoHoldMsg_Autohold_off" 5 "AutoHoldMsg_Autohold_release" 6 "AutoHoldMsg_6_reserved" 7 "AutoHoldMsg_7_reserved";
VAL_ 362 AutoHoldSysSts 0 "AutoHoldSysSts_Off" 1 "AutoHoldSysSts_intervention" 2 "AutoHoldSysSts_standby" 3 "AutoHoldSysSts_error";
VAL_ 362 AutoMainBeamLghtReq 0 "AutoMainBeamLghtReq_No_Request" 1 "AutoMainBeamLghtReq_Request_ON_from_camera" 2 "AutoMainBeamLghtReq_Request_OFF_from_camera" 3 "AutoMainBeamLghtReq_cannot_detected_the_environment";
VAL_ 362 BrkSysRedBrkTlltReq 0 "False" 1 "True";
VAL_ 362 EnASSSta 0 "EnASSSta_Engine_Off" 1 "EnASSSta_Engine_Running" 2 "EnASSSta_Engine_Starting" 3 "EnASSSta_Engine_Stopping";
VAL_ 362 FCTASysFltSts 0 "FCTASysFltSts_0_NoError" 1 "FCTASysFltSts_1_SystemTemporaryUnvailable" 2 "FCTASysFltSts_2_ServiceRequired" 3 "FCTASysFltSts_3_Reserved" 4 "FCTASysFltSts_4_Reserved" 5 "FCTASysFltSts_5_Reserved" 6 "FCTASysFltSts_6_Reserved" 7 "FCTASysFltSts_7_Reserved";
VAL_ 362 FVCMBlkd 0 "False" 1 "True";
VAL_ 362 FVCMCalPrgsReq 0 "FVCMCalPrgsReq_no_request" 1 "FVCMCalPrgsReq_0_Calibration_Started_" 2 "FVCMCalPrgsReq_25_Calibration_in_progress_" 3 "FVCMCalPrgsReq_50_Calibration_in_progress_" 4 "FVCMCalPrgsReq_75_Calibration_in_progress_" 5 "FVCMCalPrgsReq_100_Calibration_Finished_" 6 "FVCMCalPrgsReq_calibration_failed" 7 "FVCMCalPrgsReq_reserved";
VAL_ 362 FVCMFltSts 0 "FVCMFltSts_No_Fault" 1 "FVCMFltSts_Fault" 2 "FVCMFltSts_2_Reserved" 3 "FVCMFltSts_3_Reserved";
VAL_ 362 HDCSysSts 0 "HDCSysSts_Normal" 1 "HDCSysSts_Enabled" 2 "HDCSysSts_Active" 3 "HDCSysSts_Failed" 4 "HDCSysSts_Temporarily_Inhibited";
VAL_ 362 SCSMdSts 0 "SCSMdSts_Unavailable" 1 "SCSMdSts_Normal_Mode" 2 "SCSMdSts_TCS_OFF_Mode" 3 "SCSMdSts_ESP_OFF_Mode";
VAL_ 362 TCSOpngMd 0 "TCSOpngMd_Off" 1 "TCSOpngMd_Normal" 2 "TCSOpngMd_Off_Road";
VAL_ 362 TCSOpngSts 0 "TCSOpngSts_Inactive" 1 "TCSOpngSts_Active" 2 "TCSOpngSts_Fault";
VAL_ 362 VSEMd 0 "VSEMd_Off" 1 "VSEMd_Normal" 2 "VSEMd_Competitive";
VAL_ 362 VSESts 0 "VSESts_Inactive" 1 "VSESts_Active" 2 "VSESts_Fault" 3 "VSESts_Warming_Up" 4 "VSESts_Not_Ready";
VAL_ 596 BrkFludLvlLow 0 "False" 1 "True";
VAL_ 596 BrkFludLvlLowV 0 "Valid" 1 "Invalid";
VAL_ 596 CCOnStsECM 0 "CCOnStsECM_0_Cruise_control_off" 1 "CCOnStsECM_1_Cruise_control_ON";
VAL_ 596 LADSAFnInd 0 "LADSAFnInd_0_IDLE" 1 "LADSAFnInd_1_Reserved" 2 "LADSAFnInd_2_Reserved" 3 "LADSAFnInd_3_Reserved" 4 "LADSAFnInd_4_Reserved" 5 "LADSAFnInd_5_Reserved" 6 "LADSAFnInd_6_Reserved" 7 "LADSAFnInd_7_Reserved" 8 "LADSAFnInd_8_Reserved" 9 "LADSAFnInd_9_Reserved" 10 "LADSAFnInd_10_ParkIn" 11 "LADSAFnInd_11_ParkOut" 12 "LADSAFnInd_12_NRCD" 13 "LADSAFnInd_13_RemoteOnekeyParkIn" 14 "LADSAFnInd_14_RemoteOnekeyParkOut";
VAL_ 1353 EnOilPrsLowIO 0 "False" 1 "True";
VAL_ 934 StrgCDMSSetngDspCmd 0 "StrgCDMSSetngDspCmd_0_Gear0" 1 "StrgCDMSSetngDspCmd_1_Gear1" 2 "StrgCDMSSetngDspCmd_2_Gear2" 3 "StrgCDMSSetngDspCmd_3_Gear3" 4 "StrgCDMSSetngDspCmd_4_Gear4" 5 "StrgCDMSSetngDspCmd_5_Gear5" 6 "StrgCDMSSetngDspCmd_6_Gear6" 7 "StrgCDMSSetngDspCmd_7_Gear7" 8 "StrgCDMSSetngDspCmd_8_Gear8" 9 "StrgCDMSSetngDspCmd_9_Gear9" 10 "StrgCDMSSetngDspCmd_10_Gear10" 11 "StrgCDMSSetngDspCmd_11_Gear11" 12 "StrgCDMSSetngDspCmd_12_Gear12" 13 "StrgCDMSSetngDspCmd_13_Gear13" 14 "StrgCDMSSetngDspCmd_14_Gear14" 15 "StrgCDMSSetngDspCmd_15_Gear15" 16 "StrgCDMSSetngDspCmd_16_Gear16" 17 "StrgCDMSSetngDspCmd_17_Gear17" 18 "StrgCDMSSetngDspCmd_18_Gear18" 19 "StrgCDMSSetngDspCmd_19_Gear19" 20 "StrgCDMSSetngDspCmd_20_Gear20" 21 "StrgCDMSSetngDspCmd_21_Gear21" 22 "StrgCDMSSetngDspCmd_22_Gear22" 23 "StrgCDMSSetngDspCmd_23_Gear23" 24 "StrgCDMSSetngDspCmd_24_Gear24" 25 "StrgCDMSSetngDspCmd_25_Gear25" 26 "StrgCDMSSetngDspCmd_26_Gear26" 27 "StrgCDMSSetngDspCmd_27_Gear27" 28 "StrgCDMSSetngDspCmd_28_Gear28" 29 "StrgCDMSSetngDspCmd_29_Gear29" 30 "StrgCDMSSetngDspCmd_30_Gear30" 31 "StrgCDMSSetngDspCmd_31_Gear31" 32 "StrgCDMSSetngDspCmd_32_Gear32" 33 "StrgCDMSSetngDspCmd_33_Gear33" 34 "StrgCDMSSetngDspCmd_34_Gear34" 35 "StrgCDMSSetngDspCmd_35_Gear35" 36 "StrgCDMSSetngDspCmd_36_Gear36" 37 "StrgCDMSSetngDspCmd_37_Gear37" 38 "StrgCDMSSetngDspCmd_38_Gear38" 39 "StrgCDMSSetngDspCmd_39_Gear39" 40 "StrgCDMSSetngDspCmd_40_Gear40" 41 "StrgCDMSSetngDspCmd_41_Gear41" 42 "StrgCDMSSetngDspCmd_42_Gear42" 43 "StrgCDMSSetngDspCmd_43_Gear43" 44 "StrgCDMSSetngDspCmd_44_Gear44" 45 "StrgCDMSSetngDspCmd_45_Gear45" 46 "StrgCDMSSetngDspCmd_46_Gear46" 47 "StrgCDMSSetngDspCmd_47_Gear47" 48 "StrgCDMSSetngDspCmd_48_Gear48" 49 "StrgCDMSSetngDspCmd_49_Gear49" 50 "StrgCDMSSetngDspCmd_50_Gear50" 51 "StrgCDMSSetngDspCmd_51_Gear51" 52 "StrgCDMSSetngDspCmd_52_Gear52" 53 "StrgCDMSSetngDspCmd_53_Gear53" 54 "StrgCDMSSetngDspCmd_54_Gear54" 55 "StrgCDMSSetngDspCmd_55_Gear55" 56 "StrgCDMSSetngDspCmd_56_Gear56" 57 "StrgCDMSSetngDspCmd_57_Gear57" 58 "StrgCDMSSetngDspCmd_58_Gear58" 59 "StrgCDMSSetngDspCmd_59_Gear59" 60 "StrgCDMSSetngDspCmd_60_Gear60" 61 "StrgCDMSSetngDspCmd_61_Gear61" 62 "StrgCDMSSetngDspCmd_62_Gear62" 63 "StrgCDMSSetngDspCmd_63_Gear63" 64 "StrgCDMSSetngDspCmd_64_Gear64" 65 "StrgCDMSSetngDspCmd_65_Gear65" 66 "StrgCDMSSetngDspCmd_66_Gear66" 67 "StrgCDMSSetngDspCmd_67_Gear67" 68 "StrgCDMSSetngDspCmd_68_Gear68" 69 "StrgCDMSSetngDspCmd_69_Gear69" 70 "StrgCDMSSetngDspCmd_70_Gear70" 71 "StrgCDMSSetngDspCmd_71_Gear71" 72 "StrgCDMSSetngDspCmd_72_Gear72" 73 "StrgCDMSSetngDspCmd_73_Gear73" 74 "StrgCDMSSetngDspCmd_74_Gear74" 75 "StrgCDMSSetngDspCmd_75_Gear75" 76 "StrgCDMSSetngDspCmd_76_Gear76" 77 "StrgCDMSSetngDspCmd_77_Gear77" 78 "StrgCDMSSetngDspCmd_78_Gear78" 79 "StrgCDMSSetngDspCmd_79_Gear79" 80 "StrgCDMSSetngDspCmd_80_Gear80" 81 "StrgCDMSSetngDspCmd_81_Gear81" 82 "StrgCDMSSetngDspCmd_82_Gear82" 83 "StrgCDMSSetngDspCmd_83_Gear83" 84 "StrgCDMSSetngDspCmd_84_Gear84" 85 "StrgCDMSSetngDspCmd_85_Gear85" 86 "StrgCDMSSetngDspCmd_86_Gear86" 87 "StrgCDMSSetngDspCmd_87_Gear87" 88 "StrgCDMSSetngDspCmd_88_Gear88" 89 "StrgCDMSSetngDspCmd_89_Gear89" 90 "StrgCDMSSetngDspCmd_90_Gear90" 91 "StrgCDMSSetngDspCmd_91_Gear91" 92 "StrgCDMSSetngDspCmd_92_Gear92" 93 "StrgCDMSSetngDspCmd_93_Gear93" 94 "StrgCDMSSetngDspCmd_94_Gear94" 95 "StrgCDMSSetngDspCmd_95_Gear95" 96 "StrgCDMSSetngDspCmd_96_Gear96" 97 "StrgCDMSSetngDspCmd_97_Gear97" 98 "StrgCDMSSetngDspCmd_98_Gear98" 99 "StrgCDMSSetngDspCmd_99_Gear99" 100 "StrgCDMSSetngDspCmd_100_Gear100" 101 "StrgCDMSSetngDspCmd_101_Reserved" 102 "StrgCDMSSetngDspCmd_102_Reserved" 103 "StrgCDMSSetngDspCmd_103_Reserved" 104 "StrgCDMSSetngDspCmd_104_Reserved" 105 "StrgCDMSSetngDspCmd_105_Reserved" 106 "StrgCDMSSetngDspCmd_106_Reserved" 107 "StrgCDMSSetngDspCmd_107_Reserved" 108 "StrgCDMSSetngDspCmd_108_Reserved" 109 "StrgCDMSSetngDspCmd_109_Reserved" 110 "StrgCDMSSetngDspCmd_110_Reserved" 111 "StrgCDMSSetngDspCmd_111_Reserved" 112 "StrgCDMSSetngDspCmd_112_Reserved" 113 "StrgCDMSSetngDspCmd_113_Reserved" 114 "StrgCDMSSetngDspCmd_114_Reserved" 115 "StrgCDMSSetngDspCmd_115_Reserved" 116 "StrgCDMSSetngDspCmd_116_Reserved" 117 "StrgCDMSSetngDspCmd_117_Reserved" 118 "StrgCDMSSetngDspCmd_118_Reserved" 119 "StrgCDMSSetngDspCmd_119_Reserved" 120 "StrgCDMSSetngDspCmd_120_Reserved" 121 "StrgCDMSSetngDspCmd_121_Reserved" 122 "StrgCDMSSetngDspCmd_122_Reserved" 123 "StrgCDMSSetngDspCmd_123_Reserved" 124 "StrgCDMSSetngDspCmd_124_Reserved" 125 "StrgCDMSSetngDspCmd_125_Reserved" 126 "StrgCDMSSetngDspCmd_126_Reserved" 127 "StrgCDMSSetngDspCmd_127_Reserved";
VAL_ 76 BrkSysHillStAstAvlbl 0 "False" 1 "True";
VAL_ 76 SLIFSts_ECM 0 "SLIFSts_ECM_0_Off" 1 "SLIFSts_ECM_1_Active" 2 "SLIFSts_ECM_2_Overspeed" 3 "SLIFSts_ECM_3_Standby" 4 "SLIFSts_ECM_4_Fault";
VAL_ 76 SLIFWrngStsResp 0 "SLIFWrngStsResp_0_SLIF_ON" 1 "SLIFWrngStsResp_1_SLIF_Off";
VAL_ 76 SpdAstMdECM 0 "SpdAstMdECM_Off" 1 "SpdAstMdECM_SLIF" 2 "SpdAstMdECM_MSA" 3 "SpdAstMdECM_ISA";
VAL_ 76 SpdAstSysStsECM 0 "SpdAstSysStsECM_Off" 1 "SpdAstSysStsECM_Active_Limiting_" 2 "SpdAstSysStsECM_Standby" 3 "SpdAstSysStsECM_Entry_Conditions_Incorrect" 4 "SpdAstSysStsECM_Overspeed" 5 "SpdAstSysStsECM_Fault" 6 "SpdAstSysStsECM_Active_Passive_" 7 "SpdAstSysStsECM_Reserved";
VAL_ 76 TrgtSpdSrcSts 0 "TrgtSpdSrcSts_Undefined" 1 "TrgtSpdSrcSts_Camera" 2 "TrgtSpdSrcSts_Navigation" 3 "TrgtSpdSrcSts_Fault";
VAL_ 313 FCTSysSelSts 0 "FCTSysSelSts_0_FCTA_On" 1 "FCTSysSelSts_1_FCTA_RCTB_off" 2 "FCTSysSelSts_2_disable" 3 "FCTSysSelSts_3_FCTB_FCTA_On";
VAL_ 313 FrtCrnRdrCalSts 1 "FrtCrnRdrCalSts_1_Calibration_Started" 2 "FrtCrnRdrCalSts_2_Calibration_in_progress" 3 "FrtCrnRdrCalSts_3_Calibration_Finished_Succesful" 4 "FrtCrnRdrCalSts_4_Calibration_Finished_need_Adjust" 5 "FrtCrnRdrCalSts_5_calibration_failure" 6 "FrtCrnRdrCalSts_6_reserve" 7 "FrtCrnRdrCalSts_7_reserve";
VAL_ 313 LFCTAWrnng 0 "LFCTAWrnng_0_nowarning" 1 "LFCTAWrnng_1_warninglevel1" 2 "LFCTAWrnng_2_warninglevel2" 3 "LFCTAWrnng_3_reserved";
VAL_ 313 RFCTAWrnng 0 "RFCTAWrnng_0_nowarning" 1 "RFCTAWrnng_1_warninglevel1" 2 "RFCTAWrnng_2_warninglevel2" 3 "RFCTAWrnng_3_reserved";
VAL_ 553 BSDSelSts 0 "BSDSelSts_0_On" 1 "BSDSelSts_1_Off" 2 "BSDSelSts_2_disable" 3 "BSDSelSts_3_reserved";
VAL_ 553 DOWSelSts 0 "DOWSelSts_On" 1 "DOWSelSts_Off" 2 "DOWSelSts_disable" 3 "DOWSelSts_reserved";
VAL_ 553 LBSDAndLCAWrnng 0 "LBSDAndLCAWrnng_no_warning" 1 "LBSDAndLCAWrnng_warning_level_1" 2 "LBSDAndLCAWrnng_warning_level_2" 3 "LBSDAndLCAWrnng_Reserved";
VAL_ 553 LCASelSts 0 "LCASelSts_On" 1 "LCASelSts_Off" 2 "LCASelSts_disable" 3 "LCASelSts_reserved";
VAL_ 553 LDOWWrnng 0 "LDOWWrnng_no_warning" 1 "LDOWWrnng_warning_level_1" 2 "LDOWWrnng_warning_level_2" 3 "LDOWWrnng_Reserved";
VAL_ 553 LRCTAWrnng 0 "LRCTAWrnng_no_warning" 1 "LRCTAWrnng_warning_level_1" 2 "LRCTAWrnng_warning_level_2" 3 "LRCTAWrnng_Reserved";
VAL_ 553 RBSDAndLCAWrnng 0 "RBSDAndLCAWrnng_no_warning" 1 "RBSDAndLCAWrnng_warning_level_1" 2 "RBSDAndLCAWrnng_warning_level_2" 3 "RBSDAndLCAWrnng_Reserved";
VAL_ 553 RCTBPrflReq 0 "False" 1 "True";
VAL_ 553 RCTBReq 0 "RCTBReq_no_demand" 1 "RCTBReq_demand";
VAL_ 553 RCTBSysFltSts 0 "RCTBSysFltSts_No_Error" 1 "RCTBSysFltSts_Reserved" 2 "RCTBSysFltSts_System_Temporary_Unvailable" 3 "RCTBSysFltSts_Service_Required" 4 "RCTBSysFltSts_Reserved4" 5 "RCTBSysFltSts_Reserved5" 6 "RCTBSysFltSts_Reserved6" 7 "RCTBSysFltSts_Reserved7";
VAL_ 553 RCTBSysSta 1 "RCTBSysSta_Off" 2 "RCTBSysSta_On" 3 "RCTBSysSta_Disable" 4 "RCTBSysSta_Override" 5 "RCTBSysSta_Active" 6 "RCTBSysSta_Reserved6" 7 "RCTBSysSta_Reserved7";
VAL_ 553 RCTSysSelSts 0 "RCTSysSelSts_0_RCTA_On" 1 "RCTSysSelSts_1_RCTA_RCTB_off" 2 "RCTSysSelSts_2_disabled" 3 "RCTSysSelSts_3_RCTB_RCTA_on";
VAL_ 553 RCWSelSts 0 "RCWSelSts_On" 1 "RCWSelSts_Off" 2 "RCWSelSts_disable" 3 "RCWSelSts_reserved";
VAL_ 553 RCWWrnng 0 "RCWWrnng_0_no_warning" 1 "RCWWrnng_1_warning_codition1" 2 "RCWWrnng_2_warning_condition2" 3 "RCWWrnng_3_reserved";
VAL_ 553 RDASwSts 0 "RDASwSts_On" 1 "RDASwSts_Off" 2 "RDASwSts_disable" 3 "RDASwSts_reserved";
VAL_ 553 RDASysSta 1 "RDASysSta_1_Reserved" 2 "RDASysSta_2_System_Temporary_unavailability" 3 "RDASysSta_3_SensorBlockage" 4 "RDASysSta_4_Disabled" 5 "RDASysSta_5_Enabled" 6 "RDASysSta_6_SystemError";
VAL_ 553 RDOWWrnng 0 "RDOWWrnng_no_warning" 1 "RDOWWrnng_warning_level_1" 2 "RDOWWrnng_warning_level_2" 3 "RDOWWrnng_Reserved";
VAL_ 553 RrCrnRdrCalSts 1 "RrCrnRdrCalSts_1_Calibration_Started" 2 "RrCrnRdrCalSts_2_Calibration_in_progress" 3 "RrCrnRdrCalSts_3_Calibration_Finished_Succesful" 4 "RrCrnRdrCalSts_4_Calibration_Finished_need_Adjust" 5 "RrCrnRdrCalSts_5_calibration_failure" 6 "RrCrnRdrCalSts_6_reserve" 7 "RrCrnRdrCalSts_7_reserve";
VAL_ 553 RRCTAWrnng 0 "RRCTAWrnng_no_warning" 1 "RRCTAWrnng_warning_level_1" 2 "RRCTAWrnng_warning_level_2" 3 "RRCTAWrnng_Reserved";
VAL_ 560 ELSDCustSetngDspCmd 0 "ELSDCustSetngDspCmd_0_Function_Disable" 1 "ELSDCustSetngDspCmd_1_Comfort_Mode" 2 "ELSDCustSetngDspCmd_2_Normal_Mode" 3 "ELSDCustSetngDspCmd_3_Sport_Mode";
VAL_ 481 StrgWhlEntrtnSwDataIntgty_l 0 "StrgWhlEntrtnSwDataIntgty_l_0_Data_Valid" 1 "StrgWhlEntrtnSwDataIntgty_l_1_Data_Invalid";
VAL_ 481 SWSCnfmSwA_l 0 "False" 1 "True";
VAL_ 481 SWSEntrtnUserSwA_l 0 "False" 1 "True";
VAL_ 481 SWSFastrUserSwA_l 0 "False" 1 "True";
VAL_ 481 SWSFnChngSwA_l 0 "SWSFnChngSwA_l_FICM" 1 "SWSFnChngSwA_l_IPK";
VAL_ 481 SWSSelDwnSwA_l 0 "False" 1 "True";
VAL_ 481 SWSSelLSwA_l 0 "False" 1 "True";
VAL_ 481 SWSSelRSwA_l 0 "False" 1 "True";
VAL_ 481 SWSSelUpSwA_l 0 "False" 1 "True";
VAL_ 481 SWSSocContSwA_l 0 "False" 1 "True";
VAL_ 481 SWSVcSwA_l 0 "False" 1 "True";
VAL_ 819 FOTASts 0 "FOTASts_0_None_FOTA" 1 "FOTASts_1_FOTA";
VAL_ 819 FOTAStsV 0 "FOTAStsV_0_invalid" 1 "FOTAStsV_1_valid";
VAL_ 852 EmgcCallFlrSts 0 "EmgcCallFlrSts_0_No_failure" 1 "EmgcCallFlrSts_1_Light_level" 2 "EmgcCallFlrSts_2_Heavy_level" 3 "EmgcCallFlrSts_3_Disabled";
VAL_ 852 EmgcCallTrigd 0 "False" 1 "True";
VAL_ 501 AutocTrCmddGear_TCM 0 "AutocTrCmddGear_TCM_0_Not_Supported" 1 "AutocTrCmddGear_TCM_1_First_Gear" 2 "AutocTrCmddGear_TCM_2_Second_Gear" 3 "AutocTrCmddGear_TCM_3_Third_Gear" 4 "AutocTrCmddGear_TCM_4_Fourth_Gear" 5 "AutocTrCmddGear_TCM_5_Fifth_Gear" 6 "AutocTrCmddGear_TCM_6_Sixth_Gear" 7 "AutocTrCmddGear_TCM_7_Seventh_Gear" 8 "AutocTrCmddGear_TCM_8_Eighth_Gear" 9 "AutocTrCmddGear_TCM_9_Ninth_Gear" 10 "AutocTrCmddGear_TCM_10_reserved" 11 "AutocTrCmddGear_TCM_11_reserved" 12 "AutocTrCmddGear_TCM_12_reserved" 13 "AutocTrCmddGear_TCM_13_Neutral_Gear" 14 "AutocTrCmddGear_TCM_14_Reverse_Gear" 15 "AutocTrCmddGear_TCM_15_Park_Gear";
VAL_ 501 DrvrShftCtrlReqDndIO 0 "False" 1 "True";
VAL_ 501 DrvrShftCtrlTrgtGear_TCM 0 "DrvrShftCtrlTrgtGear_TCM_0_Not_Supported" 1 "DrvrShftCtrlTrgtGear_TCM_1_First_Gear" 2 "DrvrShftCtrlTrgtGear_TCM_2_Second_Gear" 3 "DrvrShftCtrlTrgtGear_TCM_3_Third_Gear" 4 "DrvrShftCtrlTrgtGear_TCM_4_Fourth_Gear" 5 "DrvrShftCtrlTrgtGear_TCM_5_Fifth_Gear" 6 "DrvrShftCtrlTrgtGear_TCM_6_Sixth_Gear" 7 "DrvrShftCtrlTrgtGear_TCM_7_Seventh_Gear" 8 "DrvrShftCtrlTrgtGear_TCM_8_Eighth_Gear" 9 "DrvrShftCtrlTrgtGear_TCM_9_Ninth_Gear";
VAL_ 501 TrCrpMdA_TCM 0 "False" 1 "True";
VAL_ 501 TrEngdSta_TCM 0 "TrEngdSta_TCM_Transmission_Not_Engaged" 1 "TrEngdSta_TCM_Transmissino_Engaged_in_Forward" 2 "TrEngdSta_TCM_Transmission_Engaged_in_Reverse" 3 "TrEngdSta_TCM_Operating_State_Not_Reached";
VAL_ 501 TrEngdStaV_TCM 0 "Valid" 1 "Invalid";
VAL_ 501 TrEPBAppReq 0 "False" 1 "True";
VAL_ 501 TrEstdGear_TCM 0 "TrEstdGear_TCM_0_Not_Supported" 1 "TrEstdGear_TCM_1_First_Gear" 2 "TrEstdGear_TCM_2_Second_Gear" 3 "TrEstdGear_TCM_3_Third_Gear" 4 "TrEstdGear_TCM_4_Fourth_Gear" 5 "TrEstdGear_TCM_5_Fifth_Gear" 6 "TrEstdGear_TCM_6_Sixth_Gear" 7 "TrEstdGear_TCM_7_Seventh_Gear" 8 "TrEstdGear_TCM_8_Eighth_Gear" 9 "TrEstdGear_TCM_9_Ninth_Gear" 10 "TrEstdGear_TCM_10_reserved" 11 "TrEstdGear_TCM_11_reserved" 12 "TrEstdGear_TCM_12_reserved" 13 "TrEstdGear_TCM_13_Neutral_Gear" 14 "TrEstdGear_TCM_14_Reverse_Gear" 15 "TrEstdGear_TCM_15_Park_Gear";
VAL_ 501 TrEstdGearV_TCM 0 "Valid" 1 "Invalid";
VAL_ 501 TrIntnlSwPos 0 "TrIntnlSwPos_Between_Range" 1 "TrIntnlSwPos_Park_Range" 2 "TrIntnlSwPos_Reverse_Range" 3 "TrIntnlSwPos_Neutral_Range" 4 "TrIntnlSwPos_Forward_Range_A" 5 "TrIntnlSwPos_Forward_Range_B" 6 "TrIntnlSwPos_Forward_Range_C" 7 "TrIntnlSwPos_Forward_Range_D" 8 "TrIntnlSwPos_Forward_Range_E" 9 "TrIntnlSwPos_Forward_Range_F" 10 "TrIntnlSwPos_Forward_Range_G" 11 "TrIntnlSwPos_Forward_Range_H" 12 "TrIntnlSwPos_Lever_Position_Unknown";
VAL_ 501 TrIntnlSwPosV 0 "TrIntnlSwPosV_0_Valid" 1 "TrIntnlSwPosV_1_Invalid";
VAL_ 501 TrPrkPos 0 "TrPrkPos_0_Non_Park_Position" 1 "TrPrkPos_1_Park_Position" 2 "TrPrkPos_2_Working_in_Progress" 3 "TrPrkPos_3_Unknown";
VAL_ 501 TrPrkSysF 0 "False" 1 "True";
VAL_ 501 TrShftLvrPos_TCM 0 "TrShftLvrPos_TCM_Between_Ranges" 1 "TrShftLvrPos_TCM_Park_Range" 2 "TrShftLvrPos_TCM_Reverse_Range" 3 "TrShftLvrPos_TCM_Neutral_Range" 4 "TrShftLvrPos_TCM_Forward_Range_A" 5 "TrShftLvrPos_TCM_Forward_Range_B" 6 "TrShftLvrPos_TCM_Forward_Range_C" 7 "TrShftLvrPos_TCM_Forward_Range_D" 8 "TrShftLvrPos_TCM_Forward_Range_E" 9 "TrShftLvrPos_TCM_Forward_Range_F" 10 "TrShftLvrPos_TCM_Forward_Range_G" 11 "TrShftLvrPos_TCM_Forward_Range_H" 12 "TrShftLvrPos_TCM_12_Reserved" 13 "TrShftLvrPos_TCM_13_Reserved" 14 "TrShftLvrPos_TCM_14_Reserved" 15 "TrShftLvrPos_TCM_Lever_Position_Unknown";
VAL_ 501 TrShftLvrPosV_TCM 0 "Valid" 1 "Invalid";
VAL_ 501 TrShftPtrnASts_TCM 0 "TrShftPtrnASts_TCM_Default_Shift_Pattern_Active" 1 "TrShftPtrnASts_TCM_Shift_Pattern_1_Active" 2 "TrShftPtrnASts_TCM_Shift_Pattern_2_Active" 3 "TrShftPtrnASts_TCM_Shift_Pattern_3_Active" 4 "TrShftPtrnASts_TCM_Shift_Pattern_4_Active" 5 "TrShftPtrnASts_TCM_PT_Non_Protection_Pattern_Active" 6 "TrShftPtrnASts_TCM_PT_Protection_Pattern_Active";
VAL_ 501 TrTapUpTapDwnMdSts_TCM 0 "TrTapUpTapDwnMdSts_TCM_No_Activation" 1 "TrTapUpTapDwnMdSts_TCM_Driver_Shift_Control_Active" 2 "TrTapUpTapDwnMdSts_TCM_Electronic_Range_Select_Active";
VAL_ 501 TrTrgtShftLvrPos 0 "TrTrgtShftLvrPos_0_Between_Ranges" 1 "TrTrgtShftLvrPos_1_Park_Range" 2 "TrTrgtShftLvrPos_2_Reverse_Range" 3 "TrTrgtShftLvrPos_3_Neutral_Range" 4 "TrTrgtShftLvrPos_4_Forward_Range_A" 5 "TrTrgtShftLvrPos_5_Forward_Range_B" 6 "TrTrgtShftLvrPos_6_Forward_Range_C" 7 "TrTrgtShftLvrPos_7_Forward_Range_D" 8 "TrTrgtShftLvrPos_8_Forward_Range_E" 9 "TrTrgtShftLvrPos_9_Forward_Range_F" 10 "TrTrgtShftLvrPos_10_Forward_Range_G" 11 "TrTrgtShftLvrPos_11_Forward_Range_H" 12 "TrTrgtShftLvrPos_12_Reserved" 13 "TrTrgtShftLvrPos_13_Reserved" 14 "TrTrgtShftLvrPos_14_Reserved" 15 "TrTrgtShftLvrPos_15_Lever_Position_Unknown";
VAL_ 1358 TrClThrmlProtnNotfn 0 "TrClThrmlProtnNotfn_No_Indication" 1 "TrClThrmlProtnNotfn_Indication_1" 2 "TrClThrmlProtnNotfn_Indication_2" 3 "TrClThrmlProtnNotfn_Indication_3" 4 "TrClThrmlProtnNotfn_Indication_4" 5 "TrClThrmlProtnNotfn_Indication_5" 6 "TrClThrmlProtnNotfn_Indication_6" 7 "TrClThrmlProtnNotfn_Indication_7" 8 "TrClThrmlProtnNotfn_Indication_8" 9 "TrClThrmlProtnNotfn_Indication_9" 10 "TrClThrmlProtnNotfn_Indication_10" 11 "TrClThrmlProtnNotfn_Indication_11" 12 "TrClThrmlProtnNotfn_Indication_12" 13 "TrClThrmlProtnNotfn_Indication_13" 14 "TrClThrmlProtnNotfn_Indication_14" 15 "TrClThrmlProtnNotfn_Indication_15";
VAL_ 1358 TrNonEmsnRltdMalfA 0 "False" 1 "True";
VAL_ 839 DrvrWrnngInvd 0 "DrvrWrnngInvd_0_not_active" 1 "DrvrWrnngInvd_1_active";
VAL_ 839 GearboxExtnlSigFlt 0 "GearboxExtnlSigFlt_0_not_active" 1 "GearboxExtnlSigFlt_1_active";
VAL_ 839 GearboxFlt 0 "GearboxFlt_0_not_active" 1 "GearboxFlt_1_active";
VAL_ 839 GearboxSeltrFlt 0 "GearboxSeltrFlt_0_not_active" 1 "GearboxSeltrFlt_1_active";
VAL_ 839 GearboxTemTooHi 0 "GearboxTemTooHi_0_not_active" 1 "GearboxTemTooHi_1_active";
VAL_ 839 MecnclLimphomeInNonPark 0 "MecnclLimphomeInNonPark_0_not_active" 1 "MecnclLimphomeInNonPark_1_active";
VAL_ 839 MecnclLimphomeInPark 0 "MecnclLimphomeInPark_0_not_active" 1 "MecnclLimphomeInPark_1_active";
VAL_ 839 PosParkOnlyAtSdsl 0 "PosParkOnlyAtSdsl_0_not_active" 1 "PosParkOnlyAtSdsl_1_active";
VAL_ 839 PosParkWillBeEngd 0 "PosParkWillBeEngd_0_not_active" 1 "PosParkWillBeEngd_1_active";
VAL_ 839 ShftLvrToLPos 0 "ShftLvrToLPos_0_not_active" 1 "ShftLvrToLPos_1_active";
VAL_ 839 StepOnBrkToShftGear 0 "StepOnBrkToShftGear_0_not_active" 1 "StepOnBrkToShftGear_1_active";
VAL_ 839 VehSpdHiToShft 0 "VehSpdHiToShft_0_not_active" 1 "VehSpdHiToShft_1_active";
VAL_ 770 FuelDoorOpenIO 0 "False" 1 "True";
VAL_ 770 RmndPwrOffIO 0 "False" 1 "True";
VAL_ 770 SrvcFuelSysIO 0 "False" 1 "True";
VAL_ 770 VehRfulSta 0 "VehRfulSta_0_Inactive" 1 "VehRfulSta_1_wait_to_refuel" 2 "VehRfulSta_2_ready_to_refuel" 3 "VehRfulSta_3_close_fuel_door";
VAL_ 1010 AutoSeatHeatVentSts 0 "AutoSeatHeatVentSts_0_Disable" 1 "AutoSeatHeatVentSts_1_Enable" 2 "AutoSeatHeatVentSts_2_Reserved" 3 "AutoSeatHeatVentSts_3_NotAvailable";
VAL_ 1010 FLSeatHeatLvl 0 "FLSeatHeatLvl_0_FLSeatHeatLvl_OFF" 1 "FLSeatHeatLvl_Front_left_seat_heat_level_1" 2 "FLSeatHeatLvl_Front_left_seat_heat_level_2" 3 "FLSeatHeatLvl_Front_left_seat_heat_level_3";
VAL_ 1010 FLSeatVentLvl 0 "FLSeatVentLvl_OFF" 1 "Front left seat vent level 1" 2 "Front left seat vent level 2" 3 "Front left seat vent level 3";
VAL_ 1010 FRSeatHeatLvl 0 "FRSeatHeatLvl_OFF" 1 "FRSeatHeatLvl_Front_right_seat_heat_level_1" 2 "FRSeatHeatLvl_Front_right_seat_heat_level_2" 3 "FRSeatHeatLvl_Front_right_seat_heat_level_3";
VAL_ 1010 FRSeatVentLvl 0 "FRSeatVentLvl_OFF" 1 "FRSeatVentLvl_Front_right_seat_vent_level_1" 2 "FRSeatVentLvl_Front_right_seat_vent_level_2" 3 "FRSeatVentLvl_Front_right_seat_vent_level_3";
VAL_ 761 DrvrSeatAutoRclSts 0 "DrvrSeatAutoRclSts_Disable" 1 "DrvrSeatAutoRclSts_Enable" 2 "DrvrSeatAutoRclSts_Reserved" 3 "DrvrSeatAutoRclSts_Not_available";
VAL_ 761 DrvrSeatEasyExitSts 0 "DrvrSeatEasyExitSts_Disable" 1 "DrvrSeatEasyExitSts_Enable" 2 "DrvrSeatEasyExitSts_Reserved" 3 "DrvrSeatEasyExitSts_Not_available";
VAL_ 761 MSMDrvrSeatZeroSt 0 "MSMDrvrSeatZeroSt_0_NotLearning" 1 "MSMDrvrSeatZeroSt_1_Learned";
VAL_ 761 SeatPosMmrySetSucdChmR 0 "False" 1 "True";
VAL_ 761 StrgWhlHeatLvl 0 "StrgWhlHeatLvl_OFF" 1 "StrgWhlHeatLvl_Steering_Wheel_Heat_level_1" 2 "StrgWhlHeatLvl_Steering_Wheel_Heat_level_2" 3 "StrgWhlHeatLvl_Steering_Wheel_Heat_level_3";
VAL_ 89 HUDBrtnsVal 0 "HUDBrtnsVal_0_unavailable" 1 "HUDBrtnsVal_1_level1" 2 "HUDBrtnsVal_2_level2" 3 "HUDBrtnsVal_3_level3" 4 "HUDBrtnsVal_4_level4" 5 "HUDBrtnsVal_5_level5" 6 "HUDBrtnsVal_6_level6" 7 "HUDBrtnsVal_7_level7" 8 "HUDBrtnsVal_8_level8" 9 "HUDBrtnsVal_9_level9" 10 "HUDBrtnsVal_10_level10" 11 "HUDBrtnsVal_11_level11" 12 "HUDBrtnsVal_12_level12" 13 "HUDBrtnsVal_13_level13" 14 "HUDBrtnsVal_14_level14" 15 "HUDBrtnsVal_15_level15" 16 "HUDBrtnsVal_16_level16" 17 "HUDBrtnsVal_17_level17" 18 "HUDBrtnsVal_18_level18" 19 "HUDBrtnsVal_19_level19" 20 "HUDBrtnsVal_20_level20" 21 "HUDBrtnsVal_21_level21";
VAL_ 89 HudColSetngMdSts 0 "HudColSetngMdSts_0_color1" 1 "HudColSetngMdSts_1_color2" 2 "HudColSetngMdSts_2_color3" 3 "HudColSetngMdSts_3_color4";
VAL_ 89 HudStupAniSetngSts 0 "HudStupAniSetngSts_0_animation1" 1 "HudStupAniSetngSts_1_animation2" 2 "HudStupAniSetngSts_2_animation3" 3 "HudStupAniSetngSts_3_animation4";
VAL_ 89 HUDSwSts 0 "HUDSwSts_0_unavailable" 1 "HUDSwSts_1_on" 2 "HUDSwSts_2_off";
VAL_ 89 HUDSysFltSts 0 "HUDSysFltSts_0_no_fault" 1 "HUDSysFltSts_1_fault";
VAL_ 89 HudThemeSetngMdSts 0 "HudThemeSetngMdSts_0_normal" 1 "HudThemeSetngMdSts_1_sport" 2 "HudThemeSetngMdSts_2_snow" 3 "HudThemeSetngMdSts_3_customization";
VAL_ 89 HUDVertPosAutoAdjtSwSts 0 "HUDVertPosAutoAdjtSwSts_0_unavailable" 1 "HUDVertPosAutoAdjtSwSts_1_on" 2 "HUDVertPosAutoAdjtSwSts_2_off";
VAL_ 89 HUDVertPosDspCmd 0 "HUDVertPosDspCmd_0_unavailable" 1 "HUDVertPosDspCmd_1_level1" 2 "HUDVertPosDspCmd_2_level2" 3 "HUDVertPosDspCmd_3_level3" 4 "HUDVertPosDspCmd_4_level4" 5 "HUDVertPosDspCmd_5_level5" 6 "HUDVertPosDspCmd_6_level6" 7 "HUDVertPosDspCmd_7_level7" 8 "HUDVertPosDspCmd_8_level8" 9 "HUDVertPosDspCmd_9_level9" 10 "HUDVertPosDspCmd_10_level10" 11 "HUDVertPosDspCmd_11_level11" 12 "HUDVertPosDspCmd_12_level12" 13 "HUDVertPosDspCmd_13_level13" 14 "HUDVertPosDspCmd_14_level14" 15 "HUDVertPosDspCmd_15_level15" 16 "HUDVertPosDspCmd_16_level16" 17 "HUDVertPosDspCmd_17_level17" 18 "HUDVertPosDspCmd_18_level18" 19 "HUDVertPosDspCmd_19_level19" 20 "HUDVertPosDspCmd_20_level20" 21 "HUDVertPosDspCmd_21_level21";
VAL_ 90 HUDNavReq 0 "False" 1 "True";
VAL_ 576 PEPSAntFlt 0 "False" 1 "True";
VAL_ 576 PEPSSSBFltSts 0 "PEPSSSBFltSts_No_Fault" 1 "PEPSSSBFltSts_short_to_GND" 2 "PEPSSSBFltSts_short_to_Battery" 3 "PEPSSSBFltSts_Stuck" 4 "PEPSSSBFltSts_Open_Circuit" 5 "PEPSSSBFltSts_switch_failed" 6 "PEPSSSBFltSts_6_Reserved" 7 "PEPSSSBFltSts_7_Reserved";
VAL_ 518 PwrLftgtPosV 0 "Valid" 1 "Invalid";
VAL_ 763 PwrLftgtManuClsReq 0 "False" 1 "True";
VAL_ 763 PwrLftgtPutInParkReq 0 "False" 1 "True";
VAL_ 763 PwrLftgtSts 0 "PwrLftgtSts_system_fault" 1 "PwrLftgtSts_system_Limit" 2 "PwrLftgtSts_full_open" 3 "PwrLftgtSts_full_Close" 4 "PwrLftgtSts_opening" 5 "PwrLftgtSts_closing" 6 "PwrLftgtSts_middle_Stop" 7 "PwrLftgtSts_Transition_trough_striker";
VAL_ 1149 FLTirePrsV 0 "Valid" 1 "Invalid";
VAL_ 1149 FLTireTemV 0 "Valid" 1 "Invalid";
VAL_ 1149 FRTirePrsV 0 "Valid" 1 "Invalid";
VAL_ 1149 FRTireTemV 0 "Valid" 1 "Invalid";
VAL_ 1149 RLTirePrsV 0 "Valid" 1 "Invalid";
VAL_ 1149 RLTireTemV 0 "Valid" 1 "Invalid";
VAL_ 1149 RRTirePrsV 0 "Valid" 1 "Invalid";
VAL_ 1149 RRTireTemV 0 "Valid" 1 "Invalid";
VAL_ 1150 FLTireSts 0 "FLTireSts_Normal" 1 "FLTireSts_Unkown" 2 "FLTireSts_Pressure_Low" 3 "FLTireSts_Quick_leak" 4 "FLTireSts_Pressure_High" 5 "FLTireSts_Temperature_High" 6 "FLTireSts_Axle_Pressure_imbalance" 7 "FLTireSts_Battery_Low";
VAL_ 1150 FRTireSts 0 "FRTireSts_Normal" 1 "FRTireSts_Unkown" 2 "FRTireSts_Pressure_Low" 3 "FRTireSts_Quick_leak" 4 "FRTireSts_Pressure_High" 5 "FRTireSts_Temperature_High" 6 "FRTireSts_Axle_Pressure_imbalance" 7 "FRTireSts_Battery_Low";
VAL_ 1150 RLTireSts 0 "RLTireSts_Normal" 1 "RLTireSts_Unkown" 2 "RLTireSts_Pressure_Low" 3 "RLTireSts_Quick_leak" 4 "RLTireSts_Pressure_High" 5 "RLTireSts_Temperature_High" 6 "RLTireSts_Axle_Pressure_imbalance" 7 "RLTireSts_Battery_Low";
VAL_ 1150 RRTireSts 0 "RRTireSts_Normal" 1 "RRTireSts_Unkown" 2 "RRTireSts_Pressure_Low" 3 "RRTireSts_Quick_leak" 4 "RRTireSts_Pressure_High" 5 "RRTireSts_Temperature_High" 6 "RRTireSts_Axle_Pressure_imbalance" 7 "RRTireSts_Battery_Low";
VAL_ 1150 TPMSAutoLoctnCm 0 "False" 1 "True";
VAL_ 1150 TPMSF 0 "False" 1 "True";
VAL_ 1150 TPMSIdficnLrnCm 0 "False" 1 "True";
VAL_ 1150 TPMSTirePrsLowIO 0 "False" 1 "True";
VAL_ 1150 TPMSWntrMdA 0 "False" 1 "True";
SIG_GROUP_ 1546 DIAG_PhysReq_VKR 1 : DiagnosticReqVKR;
SIG_GROUP_ 337 HADS_020ms_PDU00 1 : DistOutODD HADS_020ms_PDU00_CRC HADS_020ms_PDU00_RC HADS_020ms_PDU00_Reserve03 HADS_020ms_PDU00_Reserve04 HADS_020ms_PDU00_Reserve05 NOPMsgReq NOPSysFltSts NOPSysSts SHWAEPBAppdReq SHWAIndSts SHWASysFltSts SHWASysMsg SHWASysReqHzrdLghtReqSts SHWASysSts SHWASysTakeOver;
SIG_GROUP_ 862 SCS_020ms_PDU04 1 : EPBAppcnSts EPBAvlblySts EPBCCCanclReqd EPBFlrSts EPBSts EPBSwSts EPBSwStsV EPBSysAudWrnngReq EPBSysDspMsgReq EPBSysStsIndReq EPBSysWrnngIndReq SCS_020ms_PDU04_CRC SCS_020ms_PDU04_RC SCS_020ms_PDU04_Reserve01;
SIG_GROUP_ 501 TCM_PTCAN_FrP02 1 : AutocTrCmddGear_TCM DrvrShftCtrlReqDndIO DrvrShftCtrlTrgtGear_TCM TCM_025ms_PDU02_CRC TCM_025ms_PDU02_RC TCM_025ms_PDU02_Reserve03 TCM_025ms_PDU02_Reserve04 TCM_025ms_PDU02_Reserve05 TrCrpMdA_TCM TrEngdSta_TCM TrEngdStaV_TCM TrEPBAppReq TrEstdGear_TCM TrEstdGearV_TCM TrIntnlSwPos TrIntnlSwPosV TrPrkPos TrPrkSysF TrShftLvrPos_TCM TrShftLvrPosV_TCM TrShftPtrnASts_TCM TrTapUpTapDwnMdSts_TCM TrTrgtShftLvrPos;
